VERSION ""

NS_ :

BS_:

BU_: WPC2 RLPSU DPSU APSU PSB SHVU_RR vHS_B2 FCS EMCU SLB ARS RCM CGW_CCU vDummy_HS_B ATS RLHV SGU PFSU ALBCU DSAU SWRC SHVU_FR RCS RRPSU BLTN_CAM SCM DLBCU OHCL RWPC RRHV WPC HOD ASAU

BO_ 607 ATS_04_200ms: 8 ATS
 SG_ ATS_RRStSldFwdBtn : 16|2@1+ (1,0) [0|0] ""  Vector__XXX
 SG_ ATS_RRStSldBwdBtn : 18|2@1+ (1,0) [0|0] ""  Vector__XXX
 SG_ ATS_RRStRclFwdBtn : 20|2@1+ (1,0) [0|0] ""  Vector__XXX
 SG_ ATS_RRStRclBwdBtn : 22|2@1+ (1,0) [0|0] ""  Vector__XXX
 SG_ ATS_RRStTltUpBtn : 24|2@1+ (1,0) [0|0] ""  Vector__XXX
 SG_ ATS_RRStTltDnBtn : 26|2@1+ (1,0) [0|0] ""  Vector__XXX
 SG_ ATS_RRStLegRestPopBtn : 32|2@1+ (1,0) [0|0] ""  Vector__XXX
 SG_ ATS_RRStFRestPopBtn : 34|2@1+ (1,0) [0|0] ""  Vector__XXX
 SG_ ATS_RRStAstPopBtn : 36|2@1+ (1,0) [0|0] ""  Vector__XXX
 SG_ ATS_RRFauCondiBtn : 38|2@1+ (1,0) [0|0] ""  Vector__XXX
 SG_ ATS_RRStHRestUpBtn : 40|2@1+ (1,0) [0|0] ""  Vector__XXX
 SG_ ATS_RRStHRestDnBtn : 42|2@1+ (1,0) [0|0] ""  Vector__XXX
 SG_ ATS_RRStHRestFwdBtn : 44|2@1+ (1,0) [0|0] ""  Vector__XXX
 SG_ ATS_RRStHRestBwdBtn : 46|2@1+ (1,0) [0|0] ""  Vector__XXX
 SG_ ATS_RRStShoulderADJFwdBtn : 48|2@1+ (1,0) [0|0] ""  Vector__XXX
 SG_ ATS_RRStShoulderADJBwdBtn : 50|2@1+ (1,0) [0|0] ""  Vector__XXX
 SG_ ATS_RRStLegRestUpBtn : 56|2@1+ (1,0) [0|0] ""  Vector__XXX
 SG_ ATS_RRStLegRestDnBtn : 58|2@1+ (1,0) [0|0] ""  Vector__XXX
 SG_ ATS_RRStLegRestExtUpBtn : 60|2@1+ (1,0) [0|0] ""  Vector__XXX
 SG_ ATS_RRStLegRestExtDnBtn : 62|2@1+ (1,0) [0|0] ""  Vector__XXX

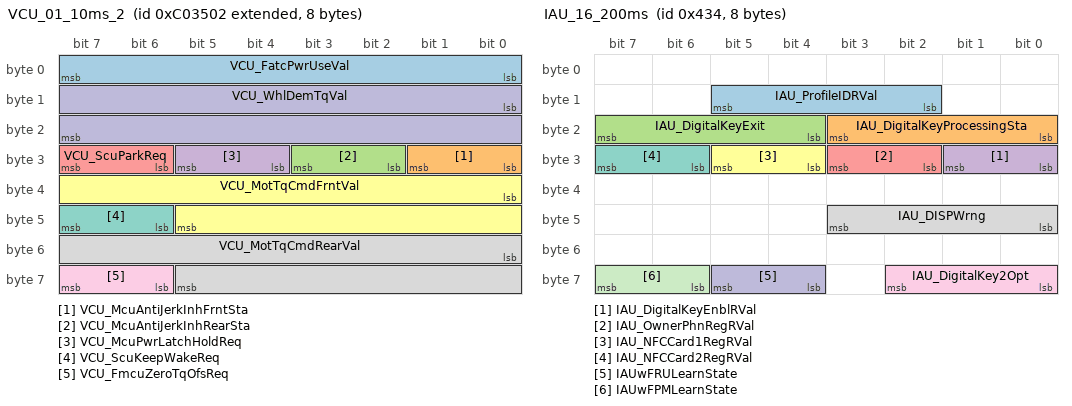
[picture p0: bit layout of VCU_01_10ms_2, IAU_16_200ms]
BO_ 2160080130 VCU_01_10ms_2: 8 CGW_CCU
 SG_ VCU_FatcPwrUseVal : 0|8@1+ (10,0) [0|2550] "W"  Vector__XXX
 SG_ VCU_McuAntiJerkInhFrntSta : 24|2@1+ (1,0) [0|3] ""  Vector__XXX
 SG_ VCU_McuAntiJerkInhRearSta : 26|2@1+ (1,0) [0|3] ""  Vector__XXX
 SG_ VCU_McuPwrLatchHoldReq : 28|2@1+ (1,0) [0|0] ""  Vector__XXX
 SG_ VCU_ScuParkReq : 30|2@1+ (1,0) [0|0] "flag"  Vector__XXX
 SG_ VCU_MotTqCmdFrntVal : 32|14@1- (0.125,0) [-1024|1023.875] "Nm"  Vector__XXX
 SG_ VCU_ScuKeepWakeReq : 46|2@1+ (1,0) [0|0] "flag"  Vector__XXX
 SG_ VCU_MotTqCmdRearVal : 48|14@1- (0.125,0) [-1024|1023.875] "Nm"  Vector__XXX
 SG_ VCU_FmcuZeroTqOfsReq : 62|2@1+ (1,0) [0|0] "flag"  Vector__XXX
 SG_ VCU_WhlDemTqVal : 8|16@1- (1,0) [-32768|32767] "Nm"  Vector__XXX

BO_ 1076 IAU_16_200ms: 8 CGW_CCU
 SG_ IAU_ProfileIDRVal : 10|4@1+ (1,0) [0|0] ""  WPC,RWPC,DPSU,DLBCU,RCM,BLTN_CAM,SGU,WPC2
 SG_ IAU_DigitalKeyProcessingSta : 16|4@1+ (1,0) [0|0] ""  Vector__XXX
 SG_ IAU_DigitalKeyExit : 20|4@1+ (1,0) [0|0] ""  Vector__XXX
 SG_ IAU_DigitalKeyEnblRVal : 24|2@1+ (1,0) [0|0] ""  Vector__XXX
 SG_ IAU_OwnerPhnRegRVal : 26|2@1+ (1,0) [0|0] ""  Vector__XXX
 SG_ IAU_NFCCard1RegRVal : 28|2@1+ (1,0) [0|0] ""  Vector__XXX
 SG_ IAU_NFCCard2RegRVal : 30|2@1+ (1,0) [0|0] ""  Vector__XXX
 SG_ IAU_DISPWrng : 40|4@1+ (1,0) [0|0] ""  Vector__XXX
 SG_ IAU_DigitalKey2Opt : 56|3@1+ (1,0) [0|0] ""  WPC,WPC2
 SG_ IAUwFRULearnState : 60|2@1+ (1,0) [0|0] ""  Vector__XXX
 SG_ IAUwFPMLearnState : 62|2@1+ (1,0) [0|0] ""  Vector__XXX

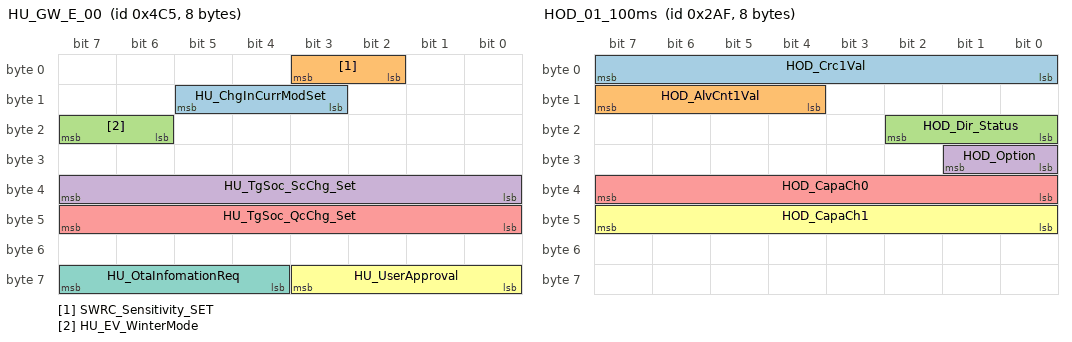
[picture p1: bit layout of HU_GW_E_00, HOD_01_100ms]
BO_ 1221 HU_GW_E_00: 8 CGW_CCU
 SG_ HU_ChgInCurrModSet : 11|3@1+ (1,0) [0|0] ""  Vector__XXX
 SG_ SWRC_Sensitivity_SET : 2|2@1+ (1,0) [0|0] ""  SWRC
 SG_ HU_EV_WinterMode : 22|2@1+ (1,0) [0|0] ""  Vector__XXX
 SG_ HU_TgSoc_ScChg_Set : 32|8@1+ (0.5,0) [0|100] "%"  Vector__XXX
 SG_ HU_TgSoc_QcChg_Set : 40|8@1+ (0.5,0) [0|100] "%"  Vector__XXX
 SG_ HU_UserApproval : 56|4@1+ (1,0) [0|0] ""  Vector__XXX
 SG_ HU_OtaInfomationReq : 60|4@1+ (1,0) [0|0] ""  Vector__XXX

BO_ 687 HOD_01_100ms: 8 HOD
 SG_ HOD_Crc1Val : 0|8@1+ (1,0) [0|0] ""  CGW_CCU
 SG_ HOD_AlvCnt1Val : 12|4@1+ (1,0) [0|0] ""  CGW_CCU
 SG_ HOD_Dir_Status : 16|3@1+ (1,0) [0|0] ""  CGW_CCU
 SG_ HOD_Option : 24|2@1+ (1,0) [0|0] ""  CGW_CCU
 SG_ HOD_CapaCh0 : 32|8@1+ (1,0) [0|0] ""  CGW_CCU
 SG_ HOD_CapaCh1 : 40|8@1+ (1,0) [0|0] ""  CGW_CCU

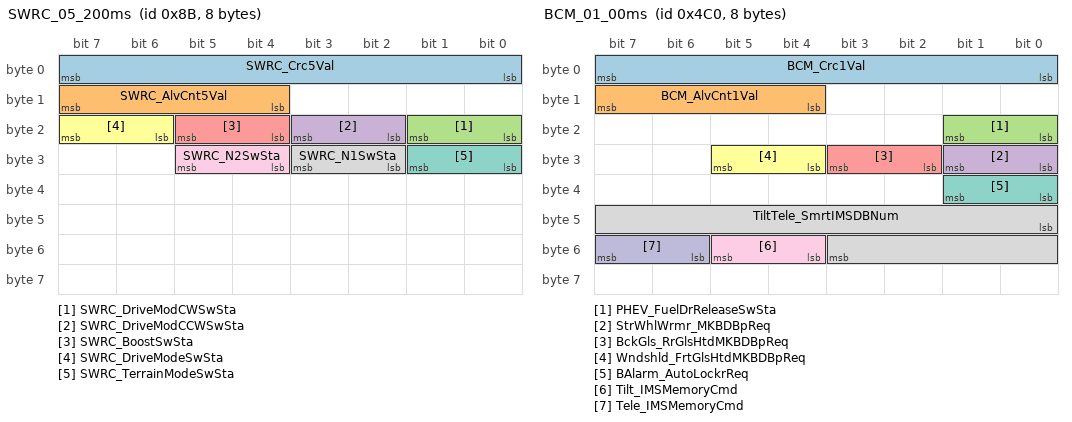
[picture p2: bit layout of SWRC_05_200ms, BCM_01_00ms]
BO_ 139 SWRC_05_200ms: 8 SWRC
 SG_ SWRC_Crc5Val : 0|8@1+ (1,0) [0|0] ""  CGW_CCU
 SG_ SWRC_AlvCnt5Val : 12|4@1+ (1,0) [0|0] ""  CGW_CCU
 SG_ SWRC_DriveModCWSwSta : 16|2@1+ (1,0) [0|0] ""  CGW_CCU
 SG_ SWRC_DriveModCCWSwSta : 18|2@1+ (1,0) [0|0] ""  CGW_CCU
 SG_ SWRC_BoostSwSta : 20|2@1+ (1,0) [0|0] ""  CGW_CCU
 SG_ SWRC_DriveModeSwSta : 22|2@1+ (1,0) [0|0] ""  CGW_CCU
 SG_ SWRC_TerrainModeSwSta : 24|2@1+ (1,0) [0|0] ""  CGW_CCU
 SG_ SWRC_N1SwSta : 26|2@1+ (1,0) [0|0] ""  CGW_CCU
 SG_ SWRC_N2SwSta : 28|2@1+ (1,0) [0|0] ""  CGW_CCU

BO_ 1216 BCM_01_00ms: 8 CGW_CCU
 SG_ BCM_Crc1Val : 0|8@1+ (1,0) [0|0] ""  Vector__XXX
 SG_ BCM_AlvCnt1Val : 12|4@1+ (1,0) [0|0] ""  Vector__XXX
 SG_ PHEV_FuelDrReleaseSwSta : 16|2@1+ (1,0) [0|0] ""  Vector__XXX
 SG_ StrWhlWrmr_MKBDBpReq : 24|2@1+ (1,0) [0|0] ""  Vector__XXX
 SG_ BckGls_RrGlsHtdMKBDBpReq : 26|2@1+ (1,0) [0|0] ""  Vector__XXX
 SG_ Wndshld_FrtGlsHtdMKBDBpReq : 28|2@1+ (1,0) [0|0] ""  Vector__XXX
 SG_ BAlarm_AutoLockrReq : 32|2@1+ (1,0) [0|0] ""  Vector__XXX
 SG_ TiltTele_SmrtIMSDBNum : 40|12@1+ (1,0) [0|0] ""  SCM
 SG_ Tilt_IMSMemoryCmd : 52|2@1+ (1,0) [0|0] ""  SCM
 SG_ Tele_IMSMemoryCmd : 54|2@1+ (1,0) [0|0] ""  SCM

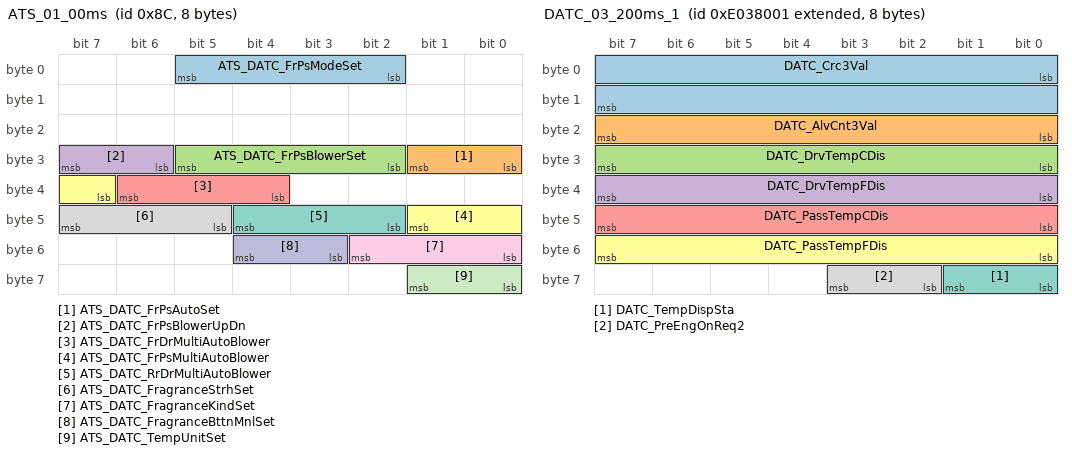
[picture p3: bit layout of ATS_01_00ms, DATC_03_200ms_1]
BO_ 140 ATS_01_00ms: 8 ATS
 SG_ ATS_DATC_FrPsModeSet : 2|4@1+ (1,0) [0|0] ""  CGW_CCU
 SG_ ATS_DATC_FrPsAutoSet : 24|2@1+ (1,0) [0|0] ""  CGW_CCU
 SG_ ATS_DATC_FrPsBlowerSet : 26|4@1+ (1,0) [0|0] ""  CGW_CCU
 SG_ ATS_DATC_FrPsBlowerUpDn : 30|2@1+ (1,0) [0|0] ""  CGW_CCU
 SG_ ATS_DATC_FrDrMultiAutoBlower : 36|3@1+ (1,0) [0|0] ""  CGW_CCU
 SG_ ATS_DATC_FrPsMultiAutoBlower : 39|3@1+ (1,0) [0|0] ""  CGW_CCU
 SG_ ATS_DATC_RrDrMultiAutoBlower : 42|3@1+ (1,0) [0|0] ""  CGW_CCU
 SG_ ATS_DATC_FragranceStrhSet : 45|3@1+ (1,0) [0|0] ""  CGW_CCU
 SG_ ATS_DATC_FragranceKindSet : 48|3@1+ (1,0) [0|0] ""  CGW_CCU
 SG_ ATS_DATC_FragranceBttnMnlSet : 51|2@1+ (1,0) [0|0] ""  CGW_CCU
 SG_ ATS_DATC_TempUnitSet : 56|2@1+ (1,0) [0|0] ""  CGW_CCU

BO_ 2382594049 DATC_03_200ms_1: 8 CGW_CCU
 SG_ DATC_Crc3Val : 0|16@1+ (1,0) [0|0] ""  Vector__XXX
 SG_ DATC_AlvCnt3Val : 16|8@1+ (1,0) [0|0] ""  Vector__XXX
 SG_ DATC_DrvTempCDis : 24|8@1+ (0.5,14) [0|0] "¡É"  ATS
 SG_ DATC_DrvTempFDis : 32|8@1+ (1,56) [0|0] "¢µ"  ATS
 SG_ DATC_PassTempCDis : 40|8@1+ (0.5,14) [0|0] "¡É"  ATS
 SG_ DATC_PassTempFDis : 48|8@1+ (1,56) [0|0] "¢µ"  ATS
 SG_ DATC_TempDispSta : 56|2@1+ (1,0) [0|0] ""  Vector__XXX
 SG_ DATC_PreEngOnReq2 : 58|2@1+ (1,0) [0|0] ""  Vector__XXX

BO_ 1219 HU_BLTN_CAM_E_00: 8 CGW_CCU
 SG_ BLTN_CAM_Rec_OWD_NvalueSet : 0|2@1+ (1,0) [0|0] ""  BLTN_CAM
 SG_ BLTN_CAM_Time_Stm_NvalueSet : 10|2@1+ (1,0) [0|0] ""  BLTN_CAM
 SG_ BLTN_CAM_Spd_Stm_NvalueSet : 12|2@1+ (1,0) [0|0] ""  BLTN_CAM
 SG_ BLTN_CAM_Locatn_Stm_NvalueSet : 14|2@1+ (1,0) [0|0] ""  BLTN_CAM
 SG_ BLTN_CAM_TrnSig_Stm_NvalueSet : 16|2@1+ (1,0) [0|0] ""  BLTN_CAM
 SG_ BLTN_CAM_AclBrk_Stm_NvalueSet : 18|2@1+ (1,0) [0|0] ""  BLTN_CAM
 SG_ BLTN_CAM_Rec_DEV_NvalueSet : 2|2@1+ (1,0) [0|0] ""  BLTN_CAM
 SG_ BLTN_CAM_GearPos_Stm_NvalueSet : 20|2@1+ (1,0) [0|0] ""  BLTN_CAM
 SG_ BLTN_CAM_EVSen_Stm_NvalueSet : 22|2@1+ (1,0) [0|0] ""  BLTN_CAM
 SG_ BLTN_CAM_Strangl_Stm_NvalueSet : 24|2@1+ (1,0) [0|0] ""  BLTN_CAM
 SG_ BLTN_CAM_PrkTime_NvalueSet : 30|8@1+ (1,0) [0|0] "Hour"  BLTN_CAM
 SG_ BLTN_CAM_EV_BfrTime_NvalueSet : 38|5@1+ (1,0) [0|0] ""  BLTN_CAM
 SG_ BLTN_CAM_Rec_OWP_NvalueSet : 4|2@1+ (1,0) [0|0] ""  BLTN_CAM
 SG_ BLTN_CAM_EV_AftTime_NvalueSet : 43|5@1+ (1,0) [0|0] ""  BLTN_CAM
 SG_ BLTN_CAM_TML_Int_NvalueSet : 48|4@1+ (1,0) [0|0] ""  BLTN_CAM
 SG_ BLTN_CAM_Sen_DEV_NvalueSet : 52|4@1+ (1,0) [0|0] ""  BLTN_CAM
 SG_ BLTN_CAM_Sen_PEV_NvalueSet : 56|4@1+ (1,0) [0|0] ""  BLTN_CAM
 SG_ BLTN_CAM_Rec_PEV_NvalueSet : 6|2@1+ (1,0) [0|0] ""  BLTN_CAM
 SG_ BLTN_CAM_AudRec_NvalueSet : 8|2@1+ (1,0) [0|0] ""  BLTN_CAM

BO_ 1218 HU_USM_E_08: 8 CGW_CCU
 SG_ C_AVN_PTGHeightNValueSet : 13|3@1+ (1,0) [0|0] ""  Vector__XXX
 SG_ CF_AVN_SCCMLReset : 16|2@1+ (1,0) [0|0] ""  Vector__XXX
 SG_ C_TgltAwayCloseNValue : 18|2@1+ (1,0) [0|0] ""  Vector__XXX
 SG_ C_HAnBNValueSet : 20|2@1+ (1,0) [0|0] ""  Vector__XXX
 SG_ CF_AVN_RrSeatRemindNValueSet : 22|2@1+ (1,0) [0|0] ""  Vector__XXX
 SG_ CF_AVN_DSWNValueSet : 24|2@1+ (1,0) [0|0] ""  Vector__XXX
 SG_ CF_AVN_RRPSU_RLNValueSet : 26|3@1+ (1,0) [0|0] ""  APSU,RRPSU,RLPSU
 SG_ CF_AVN_APSUNValueSet : 29|3@1+ (1,0) [0|0] ""  APSU,ASAU
 SG_ CF_AVN_NCC_CameraNValueSet : 32|3@1+ (1,0) [0|0] ""  Vector__XXX
 SG_ CF_AVN_RRPSU_RRNValueSet : 37|3@1+ (1,0) [0|0] ""  APSU,RRPSU,RLPSU
 SG_ CF_AVN_HtBlcAstNValueSet : 40|4@1+ (1,0) [0|0] ""  APSU,SHVU_FR
 SG_ CF_AVN_HtBlcDrvNValueSet : 44|4@1+ (1,0) [0|0] ""  APSU,SHVU_FR
 SG_ CF_AVN_SCCModeNValueSet : 48|2@1+ (1,0) [0|0] ""  Vector__XXX
 SG_ CF_AVN_SCCMLChar1Set : 50|3@1+ (1,0) [0|0] ""  Vector__XXX
 SG_ CF_AVN_UIPNValueSet : 54|2@1+ (1,0) [0|0] ""  Vector__XXX
 SG_ CF_AVN_SCCMLChar2Set : 56|3@1+ (1,0) [0|0] ""  Vector__XXX
 SG_ CF_AVN_SCCMLChar3Set : 59|3@1+ (1,0) [0|0] ""  Vector__XXX
 SG_ CF_AVN_HDALCFuncNValueSet : 8|2@1+ (1,0) [0|0] ""  Vector__XXX

BO_ 2323816451 CCU_CCS_01_00ms_3: 8 CGW_CCU

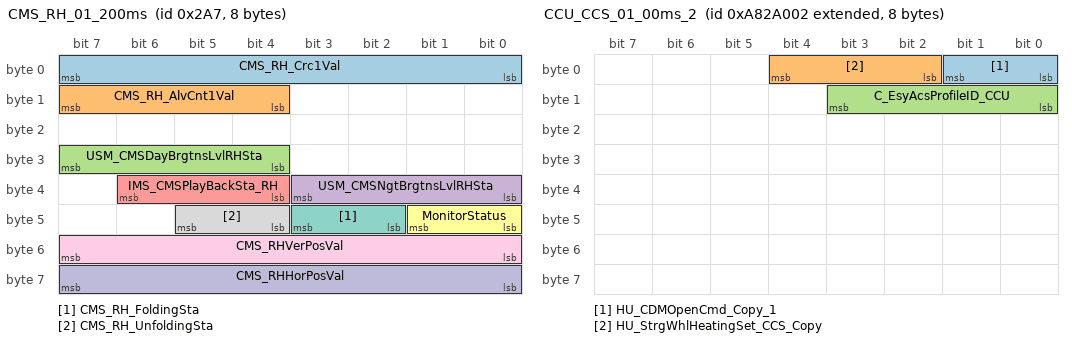
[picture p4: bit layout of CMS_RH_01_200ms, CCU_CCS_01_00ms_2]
BO_ 679 CMS_RH_01_200ms: 8 CGW_CCU
 SG_ CMS_RH_Crc1Val : 0|8@1+ (1,0) [0|0] ""  Vector__XXX
 SG_ CMS_RH_AlvCnt1Val : 12|4@1+ (1,0) [0|0] ""  Vector__XXX
 SG_ USM_CMSDayBrgtnsLvlRHSta : 28|4@1+ (1,0) [0|0] ""  Vector__XXX
 SG_ USM_CMSNgtBrgtnsLvlRHSta : 32|4@1+ (1,0) [0|0] ""  Vector__XXX
 SG_ IMS_CMSPlayBackSta_RH : 36|3@1+ (1,0) [0|0] ""  DPSU
 SG_ MonitorStatus : 40|2@1+ (1,0) [0|0] ""  Vector__XXX
 SG_ CMS_RH_FoldingSta : 42|2@1+ (1,0) [0|0] ""  Vector__XXX
 SG_ CMS_RH_UnfoldingSta : 44|2@1+ (1,0) [0|0] ""  Vector__XXX
 SG_ CMS_RHVerPosVal : 48|8@1+ (0.02,0) [0|0] "V"  Vector__XXX
 SG_ CMS_RHHorPosVal : 56|8@1+ (0.02,0) [0|0] "V"  Vector__XXX

BO_ 2323816450 CCU_CCS_01_00ms_2: 8 CGW_CCU
 SG_ HU_CDMOpenCmd_Copy_1 : 0|2@1+ (1,0) [0|0] ""  Vector__XXX
 SG_ HU_StrgWhlHeatingSet_CCS_Copy : 2|3@1+ (1,0) [0|0] ""  Vector__XXX
 SG_ C_EsyAcsProfileID_CCU : 8|4@1+ (1,0) [0|0] ""  DPSU

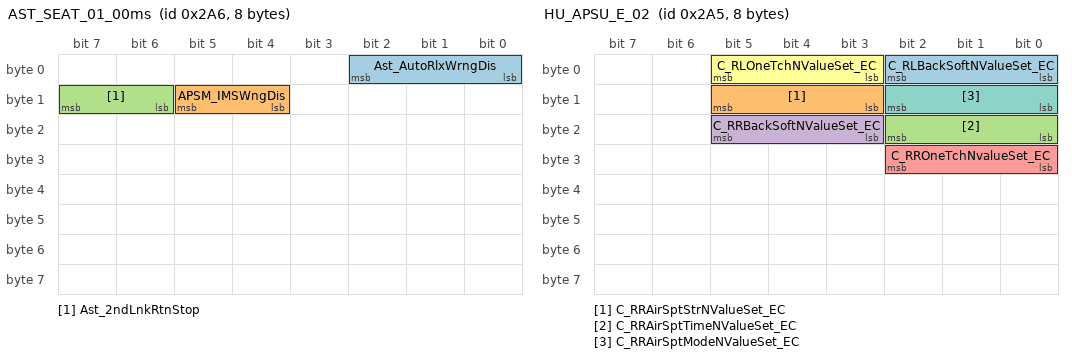
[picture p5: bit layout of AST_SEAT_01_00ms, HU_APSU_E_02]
BO_ 678 AST_SEAT_01_00ms: 8 APSU
 SG_ Ast_AutoRlxWrngDis : 0|3@1+ (1,0) [0|0] ""  CGW_CCU
 SG_ APSM_IMSWngDis : 12|2@1+ (1,0) [0|0] ""  Vector__XXX
 SG_ Ast_2ndLnkRtnStop : 14|2@1+ (1,0) [0|0] ""  RLPSU,RRPSU

BO_ 677 HU_APSU_E_02: 8 CGW_CCU
 SG_ C_RLBackSoftNValueSet_EC : 0|3@1+ (1,0) [0|0] ""  RLPSU,ATS
 SG_ C_RRAirSptStrNValueSet_EC : 11|3@1+ (1,0) [0|0] ""  RRPSU,ATS
 SG_ C_RRAirSptTimeNValueSet_EC : 16|3@1+ (1,0) [0|0] ""  RRPSU,ATS
 SG_ C_RRBackSoftNValueSet_EC : 19|3@1+ (1,0) [0|0] ""  RRPSU,ATS
 SG_ C_RROneTchNvalueSet_EC : 24|3@1+ (1,0) [0|0] ""  RRPSU,ATS
 SG_ C_RLOneTchNValueSet_EC : 3|3@1+ (1,0) [0|0] ""  RRPSU,RLPSU,ATS
 SG_ C_RRAirSptModeNValueSet_EC : 8|3@1+ (1,0) [0|0] ""  RRPSU,ATS

BO_ 2323816449 CCU_CCS_01_00ms_1: 8 CGW_CCU
 SG_ C_CtrlDrLockRlyCCS_Copy_2 : 0|2@1+ (1,0) [0|0] ""  Vector__XXX
 SG_ C_TeleHeatingCmdIBOX_Copy_2 : 10|2@1+ (1,0) [0|0] ""  Vector__XXX
 SG_ C_TeleStrgWhlHeatingCmdIBOX_Copy_2 : 12|2@1+ (1,0) [0|0] ""  Vector__XXX
 SG_ C_TeleDefoggerHeatingCmdIBOX_Copy_2 : 14|2@1+ (1,0) [0|0] ""  Vector__XXX
 SG_ C_TeleDrvSeatOpCmdIBOX_Copy_2 : 16|4@1+ (1,0) [0|0] ""  SHVU_FR,DPSU
 SG_ C_CtrlDrUnlockRlyCCS_Copy_2 : 2|2@1+ (1,0) [0|0] ""  Vector__XXX
 SG_ C_TeleAstSeatOpCmdIBOX_Copy_2 : 20|4@1+ (1,0) [0|0] ""  APSU,SHVU_FR
 SG_ C_TeleRRSeatOpCmdIBOX_Copy_2 : 24|4@1+ (1,0) [0|0] ""  RRHV,SHVU_FR,SHVU_RR,RRPSU,RLPSU,ATS
 SG_ C_TeleRLSeatOpCmdIBOX_Copy_1 : 28|4@1+ (1,0) [0|0] ""  RLHV,SHVU_FR,SHVU_RR,RRPSU,RLPSU,ATS
 SG_ C_BlindCmdAVN_Copy_2 : 32|3@1+ (1,0) [0|0] ""  Vector__XXX
 SG_ C_GlassCmdAVN_Copy_2 : 35|3@1+ (1,0) [0|0] ""  Vector__XXX
 SG_ C_DrvWindowCmdAVN_Copy_2 : 38|4@1+ (1,0) [0|0] ""  Vector__XXX
 SG_ C_HazardFromCCS_Copy_2 : 4|2@1+ (1,0) [0|0] ""  Vector__XXX
 SG_ C_AstWindowCmdAVN_Copy_2 : 42|4@1+ (1,0) [0|0] ""  Vector__XXX
 SG_ C_RRWindowCmdAVN_Copy_2 : 46|4@1+ (1,0) [0|0] ""  Vector__XXX
 SG_ C_RLWindowCmdAVN_Copy_2 : 50|4@1+ (1,0) [0|0] ""  Vector__XXX
 SG_ TailCtrlReq_Copy : 54|2@1+ (1,0) [0|0] ""  Vector__XXX
 SG_ HazardCtrlReq_Copy : 56|2@1+ (1,0) [0|0] ""  Vector__XXX
 SG_ HU_DATC_AirCleaningSet_Copy_1 : 58|2@1+ (1,0) [0|0] ""  Vector__XXX
 SG_ C_PanicFromCCS_Copy_2 : 6|2@1+ (1,0) [0|0] ""  Vector__XXX
 SG_ C_TeleFrontHeatingCmdIBOX_Copy_1 : 60|2@1+ (1,0) [0|0] ""  Vector__XXX
 SG_ RAC_AirCleaningCtrlReq_Copy_1 : 62|2@1+ (1,0) [0|0] ""  Vector__XXX
 SG_ C_PreCrankReq_Copy : 8|2@1+ (1,0) [0|0] ""  Vector__XXX

BO_ 676 HU_APSU_E_01: 8 CGW_CCU
 SG_ C_DrAirSptNValueSet_EC : 0|2@1+ (1,0) [0|0] ""  DLBCU,DSAU
 SG_ C_DrCushSoftNValueSet_EC : 11|3@1+ (1,0) [0|0] ""  DLBCU,DSAU
 SG_ C_AstAirSptNValueSet_EC : 14|2@1+ (1,0) [0|0] ""  ASAU,ALBCU
 SG_ C_DrBackSoftNValueSet_EC : 16|3@1+ (1,0) [0|0] ""  DLBCU,DSAU
 SG_ C_AstAirSptModeNValueSet_EC : 19|3@1+ (1,0) [0|0] ""  ASAU,ALBCU
 SG_ C_DrAirSptModeNValueSet_EC : 2|3@1+ (1,0) [0|0] ""  DLBCU,DSAU
 SG_ C_RLAirSptNValueSet_EC : 22|2@1+ (1,0) [0|0] ""  RLPSU,ATS
 SG_ C_AstAirSptStrNValueSet_EC : 24|3@1+ (1,0) [0|0] ""  ASAU,ALBCU
 SG_ C_AstAirSptTimeNValueSet_EC : 27|3@1+ (1,0) [0|0] ""  ASAU,ALBCU
 SG_ C_RRAirSptNValueSet_EC : 30|2@1+ (1,0) [0|0] ""  RRPSU,ATS
 SG_ C_AstCushSoftNValueSet_EC : 32|3@1+ (1,0) [0|0] ""  ASAU
 SG_ C_AstBackSoftNValueSet_EC : 35|3@1+ (1,0) [0|0] ""  ASAU
 SG_ C_AstRlxNValueSet_EC : 40|3@1+ (1,0) [0|0] ""  APSU
 SG_ C_RLAirSptModeNValueSet_EC : 43|3@1+ (1,0) [0|0] ""  RLPSU,ATS
 SG_ C_DrAirSptStrNValueSet_EC : 5|3@1+ (1,0) [0|0] ""  DLBCU,DSAU
 SG_ C_RLAirSptStrNValueSet_EC : 56|3@1+ (1,0) [0|0] ""  RLPSU,ATS
 SG_ C_RLAirSptTimeNValueSet_EC : 59|3@1+ (1,0) [0|0] ""  RLPSU,ATS
 SG_ C_DrAirSptTimeNValueSet_EC : 8|3@1+ (1,0) [0|0] ""  DLBCU,DSAU

BO_ 675 HU_USM_E_11: 8 CGW_CCU
 SG_ Usm_RpmMUDSet : 1|2@1+ (1,0) [0|0] ""  Vector__XXX
 SG_ CF_AVN_HtBlcRLNValueSet : 11|4@1+ (1,0) [0|0] ""  SHVU_FR,SHVU_RR,RRPSU,RLPSU
 SG_ CF_AVN_BRAKE_PedalfeelNValueSet2 : 15|3@1+ (1,0) [0|0] ""  Vector__XXX
 SG_ CF_AVN_ISLA_AutoNModSet : 18|2@1+ (1,0) [0|0] ""  Vector__XXX
 SG_ CF_AVN_HtBlcRRNValueSet : 20|4@1+ (1,0) [0|0] ""  SHVU_FR,SHVU_RR,RRPSU,RLPSU
 SG_ LapTimer_AutoMeasure_Setting : 24|2@1+ (1,0) [0|0] ""  Vector__XXX
 SG_ LapTimer_TimeGap_Setting : 26|2@1+ (1,0) [0|0] ""  Vector__XXX
 SG_ Usm_RpmSANDSet : 3|2@1+ (1,0) [0|0] ""  Vector__XXX
 SG_ CF_AVN_RemoteWDWNValueSet : 30|2@1+ (1,0) [0|0] ""  Vector__XXX
 SG_ USM_TowWeight_Set : 32|4@1+ (1,0) [0|0] ""  Vector__XXX
 SG_ CF_AVN_PABArbgNValueSet : 36|2@1+ (1,0) [0|0] ""  Vector__XXX
 SG_ CF_AVN_SportHUD2 : 38|2@1+ (1,0) [0|0] ""  Vector__XXX
 SG_ C_SLB_SmartCtrl_Set_Nvalue : 44|4@1+ (1,0) [0|0] ""  SLB,DLBCU
 SG_ HU_CustomNewMenuSet : 5|4@1+ (1,0) [0|0] ""  Vector__XXX
 SG_ USM_RpmComfortRearSet : 57|2@1+ (1,0) [0|0] ""  Vector__XXX
 SG_ Usm_RpmMyDriveModeSet : 59|2@1+ (1,0) [0|0] ""  Vector__XXX
 SG_ CF_AVN_PDWLmtNvalueSet : 61|2@1+ (1,0) [0|0] ""  Vector__XXX
 SG_ CF_AVN_PCA_RrEquipNvalueSet : 9|2@1+ (1,0) [0|0] ""  Vector__XXX

BO_ 1227 PSM_01_00ms: 8 DPSU
 SG_ DrvIMS_MemoryP1Req : 0|2@1+ (1,0) [0|0] ""  CGW_CCU
 SG_ DrvIMS_PlyBckP2Req : 10|2@1+ (1,0) [0|0] ""  CGW_CCU
 SG_ DrvIMS_PlyBckP3Req : 12|2@1+ (1,0) [0|0] ""  CGW_CCU
 SG_ DrvIMS_PlyBckStpReq : 14|2@1+ (1,0) [0|0] ""  CGW_CCU
 SG_ SmrtIMS_PlyBckReq : 16|12@1+ (1,0) [0|0] ""  CGW_CCU
 SG_ DrvIMS_MemoryP2Req : 2|2@1+ (1,0) [0|0] ""  CGW_CCU
 SG_ PSM_IMSReq : 28|3@1+ (1,0) [0|0] ""  CGW_CCU
 SG_ SmrtIMS_ImgDBVal : 32|5@1+ (1,0) [0|0] ""  CGW_CCU
 SG_ SmrtIMS_PlyBckStpReq : 37|2@1+ (1,0) [0|0] ""  CGW_CCU
 SG_ DrvIMS_MemoryP3Req : 4|2@1+ (1,0) [0|0] ""  CGW_CCU
 SG_ SmrtIMS_EnterSwSta : 40|2@1+ (1,0) [0|0] ""  CGW_CCU
 SG_ DrvIMS_BzrReq : 42|2@1+ (1,0) [0|0] ""  CGW_CCU
 SG_ DrvIMS_ErrConWmgDis : 46|2@1+ (1,0) [0|0] ""  CGW_CCU
 SG_ PSM_DrvRlxReturn_Req : 48|3@1+ (1,0) [0|0] ""  CGW_CCU
 SG_ Drv_AutoRlxWrngDis : 51|3@1+ (1,0) [0|0] ""  CGW_CCU
 SG_ DrvIMS_MemorySetEnaSta : 6|2@1+ (1,0) [0|0] ""  CGW_CCU
 SG_ DrvIMS_PlyBckP1Req : 8|2@1+ (1,0) [0|0] ""  CGW_CCU

BO_ 2323816452 CCU_CCS_01_00ms_4: 8 CGW_CCU

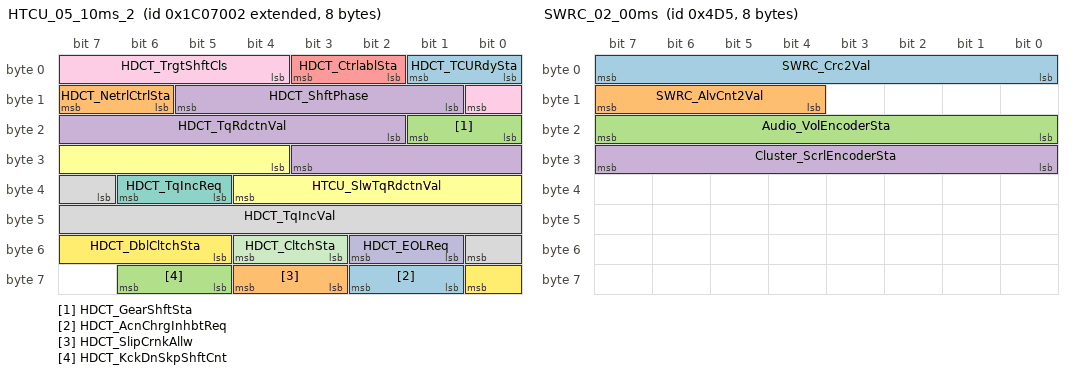
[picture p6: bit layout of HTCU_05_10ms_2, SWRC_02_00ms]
BO_ 2176872450 HTCU_05_10ms_2: 8 CGW_CCU
 SG_ HDCT_TCURdySta : 0|2@1+ (1,0) [0|0] ""  Vector__XXX
 SG_ HDCT_NetrlCtrlSta : 14|2@1+ (1,0) [0|0] ""  Vector__XXX
 SG_ HDCT_GearShftSta : 16|2@1+ (1,0) [0|0] ""  Vector__XXX
 SG_ HDCT_TqRdctnVal : 18|10@1+ (0.390625,-200) [0|0] "%"  Vector__XXX
 SG_ HDCT_CtrlablSta : 2|2@1+ (1,0) [0|0] ""  Vector__XXX
 SG_ HTCU_SlwTqRdctnVal : 28|9@1+ (0.390625,0) [0|0] "%"  Vector__XXX
 SG_ HDCT_TqIncReq : 37|2@1+ (1,0) [0|0] ""  Vector__XXX
 SG_ HDCT_TqIncVal : 39|10@1+ (0.390625,-200) [0|0] "%"  Vector__XXX
 SG_ HDCT_TrgtShftCls : 4|5@1+ (1,0) [0|0] "flag"  Vector__XXX
 SG_ HDCT_EOLReq : 49|2@1+ (1,0) [0|0] ""  Vector__XXX
 SG_ HDCT_CltchSta : 51|2@1+ (1,0) [0|0] ""  Vector__XXX
 SG_ HDCT_DblCltchSta : 53|4@1+ (1,0) [0|0] ""  Vector__XXX
 SG_ HDCT_AcnChrgInhbtReq : 57|2@1+ (1,0) [0|0] ""  Vector__XXX
 SG_ HDCT_SlipCrnkAllw : 59|2@1+ (1,0) [0|0] ""  Vector__XXX
 SG_ HDCT_KckDnSkpShftCnt : 61|2@1+ (1,0) [0|0] ""  Vector__XXX
 SG_ HDCT_ShftPhase : 9|5@1+ (1,0) [0|0] ""  Vector__XXX

BO_ 1237 SWRC_02_00ms: 8 SWRC
 SG_ SWRC_Crc2Val : 0|8@1+ (1,0) [0|0] ""  Vector__XXX
 SG_ SWRC_AlvCnt2Val : 12|4@1+ (1,0) [0|0] ""  Vector__XXX
 SG_ Audio_VolEncoderSta : 16|8@1+ (1,0) [0|0] ""  CGW_CCU
 SG_ Cluster_ScrlEncoderSta : 24|8@1+ (1,0) [0|0] ""  CGW_CCU

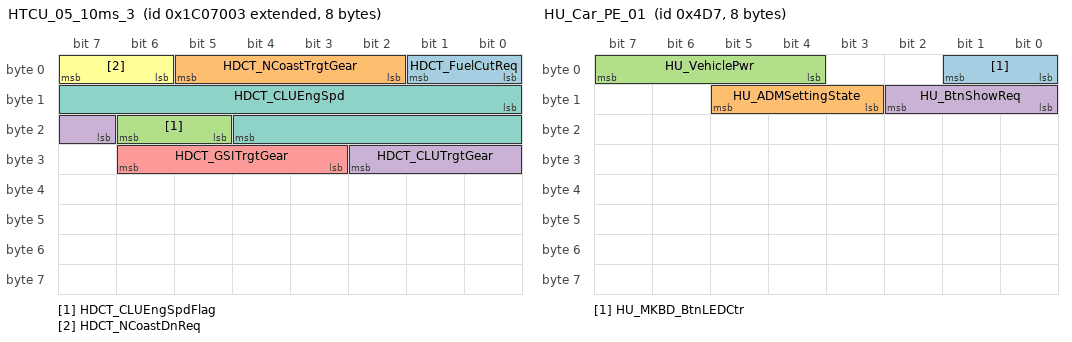
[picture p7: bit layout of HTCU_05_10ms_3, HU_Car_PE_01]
BO_ 2176872451 HTCU_05_10ms_3: 8 CGW_CCU
 SG_ HDCT_FuelCutReq : 0|2@1+ (1,0) [0|0] ""  Vector__XXX
 SG_ HDCT_NCoastTrgtGear : 2|4@1+ (1,0) [0|0] ""  Vector__XXX
 SG_ HDCT_CLUEngSpdFlag : 21|2@1+ (1,0) [0|0] ""  Vector__XXX
 SG_ HDCT_CLUTrgtGear : 23|4@1+ (1,0) [0|0] ""  Vector__XXX
 SG_ HDCT_GSITrgtGear : 27|4@1+ (1,0) [0|0] ""  Vector__XXX
 SG_ HDCT_NCoastDnReq : 6|2@1+ (1,0) [0|0] ""  Vector__XXX
 SG_ HDCT_CLUEngSpd : 8|13@1+ (0.9766,0) [0|0] ""  Vector__XXX

BO_ 1239 HU_Car_PE_01: 8 CGW_CCU
 SG_ HU_MKBD_BtnLEDCtr : 0|2@1+ (1,0) [0|0] ""  Vector__XXX
 SG_ HU_ADMSettingState : 11|3@1+ (1,0) [0|0] ""  Vector__XXX
 SG_ HU_VehiclePwr : 4|4@1+ (1,0) [0|0] ""  SGU
 SG_ HU_BtnShowReq : 8|3@1+ (1,0) [0|0] ""  SWRC

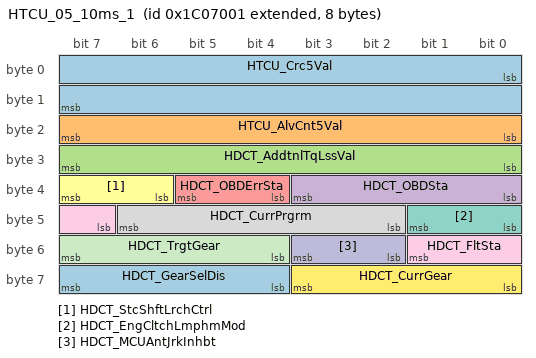
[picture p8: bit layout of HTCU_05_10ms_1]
BO_ 2176872449 HTCU_05_10ms_1: 8 CGW_CCU
 SG_ HTCU_Crc5Val : 0|16@1+ (1,0) [0|0] ""  Vector__XXX
 SG_ HTCU_AlvCnt5Val : 16|8@1+ (1,0) [0|0] ""  Vector__XXX
 SG_ HDCT_AddtnlTqLssVal : 24|8@1+ (0.390625,0) [0|0] "%"  Vector__XXX
 SG_ HDCT_OBDSta : 32|4@1+ (1,0) [0|0] ""  Vector__XXX
 SG_ HDCT_OBDErrSta : 36|2@1+ (1,0) [0|0] ""  Vector__XXX
 SG_ HDCT_StcShftLrchCtrl : 38|2@1+ (1,0) [0|0] ""  Vector__XXX
 SG_ HDCT_EngCltchLmphmMod : 40|2@1+ (1,0) [0|0] ""  Vector__XXX
 SG_ HDCT_CurrPrgrm : 42|5@1+ (1,0) [0|0] ""  Vector__XXX
 SG_ HDCT_FltSta : 47|3@1+ (1,0) [0|0] ""  Vector__XXX
 SG_ HDCT_MCUAntJrkInhbt : 50|2@1+ (1,0) [0|0] ""  Vector__XXX
 SG_ HDCT_TrgtGear : 52|4@1+ (1,0) [0|0] ""  Vector__XXX
 SG_ HDCT_CurrGear : 56|4@1+ (1,0) [0|0] ""  Vector__XXX
 SG_ HDCT_GearSelDis : 60|4@1+ (1,0) [0|0] ""  SWRC,BLTN_CAM

CM_ BO_ 678 "[EC] On Event and On Change";
CM_ SG_ 678 Ast_AutoRlxWrngDis "Assist seat auto relax warning information for AVN Display";
CM_ SG_ 678 APSM_IMSWngDis "Ast IMS information";
CM_ BO_ 140 "[EC] On Event and On Change";
CM_ SG_ 140 ATS_DATC_FrPsModeSet "Front Passenger side Mode Set";
CM_ SG_ 140 ATS_DATC_FrPsAutoSet "Front Passenger side Auto Set";
CM_ SG_ 140 ATS_DATC_FrPsBlowerSet "Front Passenger side Blower Set";
CM_ SG_ 140 ATS_DATC_FrPsBlowerUpDn "Front Passenger side Blower Up Down";
CM_ SG_ 140 ATS_DATC_FrDrMultiAutoBlower "Front Driver side Multi-Auto Blower set";
CM_ SG_ 140 ATS_DATC_FrPsMultiAutoBlower "Front Passenger side Multi-Auto Blower set";
CM_ SG_ 140 ATS_DATC_RrDrMultiAutoBlower "Rear Driver side Multi-Auto Blower set";
CM_ SG_ 140 ATS_DATC_FragranceStrhSet "Fragrance Strength Set (¹ßÇâ ±â´É Çâ ¼¼±â ¼³Á¤)";
CM_ SG_ 140 ATS_DATC_FragranceKindSet "Fragrance Kind Set (¹ßÇâ ±â´É Çâ Á¾·ù ¼³Á¤)";
CM_ SG_ 140 ATS_DATC_FragranceBttnMnlSet "Fragrance Button Manual Set (¹ßÇâ ±â´É ¹öÆ° ¼öµ¿ ÀÔ·Â)";
CM_ SG_ 140 ATS_DATC_TempUnitSet "Temp Unit Set (¿Âµµ ´ÜÀ§ ¼³Á¤)";
CM_ BO_ 607 "[PE] Periodic and On Event";
CM_ SG_ 607 ATS_RRStSldFwdBtn "Rear Right Power Seat Slide Forward Touch Button";
CM_ SG_ 607 ATS_RRStSldBwdBtn "Rear Right Power Seat Slide Backward Touch Button";
CM_ SG_ 607 ATS_RRStRclFwdBtn "Rear Right Power Seat Recline Forward Touch Button";
CM_ SG_ 607 ATS_RRStRclBwdBtn "Rear Right Power Seat Recline Backward Touch Button";
CM_ SG_ 607 ATS_RRStTltUpBtn "Rear Right Power Seat Tilt Up Touch Button";
CM_ SG_ 607 ATS_RRStTltDnBtn "Rear Right Power Seat Tilt Down Touch Button";
CM_ SG_ 607 ATS_RRStLegRestPopBtn "Rear Right Leg Rest Move Pop Up Button";
CM_ SG_ 607 ATS_RRStFRestPopBtn "Rear Right Foot Rest Move Pop Up Button";
CM_ SG_ 607 ATS_RRStAstPopBtn "Rear Right Assist Seat Move Pop Up Button";
CM_ SG_ 607 ATS_RRFauCondiBtn "Rear Right FAU Operational Condition Move Button";
CM_ SG_ 607 ATS_RRStHRestUpBtn "Rear Right Power Seat Head Rest Up Touch Button";
CM_ SG_ 607 ATS_RRStHRestDnBtn "Rear Right Power Seat Head Rest Down Touch Button";
CM_ SG_ 607 ATS_RRStHRestFwdBtn "Rear Right Power Seat Head Rest Forward Touch Button";
CM_ SG_ 607 ATS_RRStHRestBwdBtn "Rear Right Power Seat Head Rest Backward Touch Button";
CM_ SG_ 607 ATS_RRStShoulderADJFwdBtn "Rear Right Power Seat Shoulder Adjuster Forward Touch Button";
CM_ SG_ 607 ATS_RRStShoulderADJBwdBtn "Rear Right Power Seat Shoulder Adjuster Backward Touch Button";
CM_ SG_ 607 ATS_RRStLegRestUpBtn "Rear Right Power Seat Leg Rest Up Touch Button";
CM_ SG_ 607 ATS_RRStLegRestDnBtn "Rear Right Power Seat Leg Rest Down Touch Button";
CM_ SG_ 607 ATS_RRStLegRestExtUpBtn "Rear Right Power Seat Leg Rest Ext. Up Touch Button";
CM_ SG_ 607 ATS_RRStLegRestExtDnBtn "Rear Right Power Seat Leg Rest Ext. Down Touch Button";
CM_ BO_ 1216 "[EC] On Event and On Change";
CM_ SG_ 1216 BCM_Crc1Val "BCM_CyclicRedundancyCheck1Value";
CM_ SG_ 1216 BCM_AlvCnt1Val "BCM_AliveCounter1Value";
CM_ SG_ 1216 PHEV_FuelDrReleaseSwSta "PHEV_FuelDoorReleaseSwitchStatus ##2G##BCM - BCMmsg01 - C_FuelDrReleaseSw";
CM_ SG_ 1216 BAlarm_AutoLockrReq "BAlarm_AutoLockRequest ##2G##BCM - BCMmsg01 - C_AutoLockCmd";
CM_ BO_ 2323816449 "[EC] On Event and On Change";
CM_ SG_ 2323816449 C_CtrlDrLockRlyCCS_Copy_2 "Command for Remote Door Lock";
CM_ SG_ 2323816449 C_TeleHeatingCmdIBOX_Copy_2 "'Command for Remote Heating

(Steering Wheel, Rear Window, Side Mirror)";
CM_ SG_ 2323816449 C_TeleStrgWhlHeatingCmdIBOX_Copy_2 "'Command for Remote Heating
(Steering Wheel)";
CM_ SG_ 2323816449 C_TeleDefoggerHeatingCmdIBOX_Copy_2 "'Command for Remote Heating
(Rear Window, Side Mirror)";
CM_ SG_ 2323816449 C_TeleDrvSeatOpCmdIBOX_Copy_2 "Command for Remote Seat Heat/Vent control (Driver)";
CM_ SG_ 2323816449 C_CtrlDrUnlockRlyCCS_Copy_2 "Command for Remote Door UnLock";
CM_ SG_ 2323816449 C_TeleAstSeatOpCmdIBOX_Copy_2 "Command for Remote Seat Heat/Vent control (Passenger)";
CM_ SG_ 2323816449 C_TeleRRSeatOpCmdIBOX_Copy_2 "Command for Remote Seat Heat/Vent control (Rear Right)";
CM_ SG_ 2323816449 C_TeleRLSeatOpCmdIBOX_Copy_1 "Command for Remote Seat Heat/Vent control (Rear Left)";
CM_ SG_ 2323816449 C_BlindCmdAVN_Copy_2 "This signal indicates Sunroof Blind Open/Close Command";
CM_ SG_ 2323816449 C_GlassCmdAVN_Copy_2 "This signal indicates Sunroof Glass Open/Close Command";
CM_ SG_ 2323816449 C_DrvWindowCmdAVN_Copy_2 "This signal indicates DRV Window Open/Close Command";
CM_ SG_ 2323816449 C_HazardFromCCS_Copy_2 "Command for Remote Hazard";
CM_ SG_ 2323816449 C_AstWindowCmdAVN_Copy_2 "This signal indicates AST Window Open/Close Command";
CM_ SG_ 2323816449 C_RRWindowCmdAVN_Copy_2 "This signal indicates RR Window Open/Close Command";
CM_ SG_ 2323816449 C_RLWindowCmdAVN_Copy_2 "This signal indicates RL Window Open/Close Command";
CM_ SG_ 2323816449 TailCtrlReq_Copy "This signal is for cotroling Tail lamp.";
CM_ SG_ 2323816449 HazardCtrlReq_Copy "This signal is request for controling Hazard lamp.";
CM_ SG_ 2323816449 HU_DATC_AirCleaningSet_Copy_1 "Air Cleaning System set";
CM_ SG_ 2323816449 C_PanicFromCCS_Copy_2 "Command for Remote Panic (Only for USA)";
CM_ SG_ 2323816449 C_TeleFrontHeatingCmdIBOX_Copy_1 "Command for Remote Heating (Front Window)";
CM_ SG_ 2323816449 RAC_AirCleaningCtrlReq_Copy_1 "RAC_Air Cleaning Control Request";
CM_ SG_ 2323816449 C_PreCrankReq_Copy "Command for B-CAN wake up singal (Need to send this signal before other remote commands)";
CM_ BO_ 2323816450 "[EC] On Event and On Change";
CM_ SG_ 2323816450 HU_CDMOpenCmd_Copy_1 "Command for CDM open/close";
CM_ SG_ 2323816450 C_EsyAcsProfileID_CCU "This signal indicates the current detected profile ID by smartphone APP.
(The drv seat move to the easy access position of the detected profile ID when receive the signal)";
CM_ BO_ 2323816451 "[EC] On Event and On Change";
CM_ BO_ 2323816452 "[EC] On Event and On Change";
CM_ BO_ 679 "[PE] Periodic and On Event";
CM_ SG_ 679 CMS_RH_Crc1Val "CMS_RH_CyclicRedundancyCheck1Value";
CM_ SG_ 679 CMS_RH_AlvCnt1Val "CMS_RH_AliveCounter1Value";
CM_ SG_ 679 CMS_RHVerPosVal "RH Outside Mirror Vertical Position sensor value";
CM_ SG_ 679 CMS_RHHorPosVal "RH Outside Mirror Horizontal Position sensor value";
CM_ BO_ 2382594049 "[PE] Periodic and On Event";
CM_ SG_ 2382594049 DATC_Crc3Val "DATC_CyclicRedundancyCheck3Value";
CM_ SG_ 2382594049 DATC_AlvCnt3Val "DATC_AliveCounter3Value";
CM_ SG_ 2382594049 DATC_DrvTempCDis "DATC_DriverTemperatureCelciusDisplay";
CM_ SG_ 2382594049 DATC_DrvTempFDis "DATC_DriverTemperatureFahrenheitDisplay";
CM_ SG_ 2382594049 DATC_PassTempCDis "DATC_PassengerTemperatureCelciusDisplay";
CM_ SG_ 2382594049 DATC_PassTempFDis "DATC_PassengerTemperatureFahrenheitDisplay";
CM_ SG_ 2382594049 DATC_TempDispSta "DATCTempDisplayStatus";
CM_ SG_ 2382594049 DATC_PreEngOnReq2 "Pre Engine On Request";
CM_ BO_ 687 "[P] Periodic";
CM_ SG_ 687 HOD_Crc1Val "HOD_CyclicRedundancyCheck1Value";
CM_ SG_ 687 HOD_AlvCnt1Val "HOD_AliveCounter1Value";
CM_ SG_ 687 HOD_Dir_Status "hands on-off status";
CM_ SG_ 687 HOD_Option "HOD_Option";
CM_ SG_ 687 HOD_CapaCh0 "Front zone Capacitance value(pF)";
CM_ SG_ 687 HOD_CapaCh1 "Rear zone Capacitance value(pF)";
CM_ BO_ 2176872449 "[P] Periodic";
CM_ SG_ 2176872449 HTCU_Crc5Val "HTCU_CyclicRedundancyCheck5Value";
CM_ SG_ 2176872449 HTCU_AlvCnt5Val "HTCU_AliveCounter5Value";
CM_ SG_ 2176872449 HDCT_AddtnlTqLssVal "Additional Torque Loss Value ## TCU16 - CR_Tcu_AddTqLoss_Pc";
CM_ SG_ 2176872449 HDCT_OBDSta "OBD Status ## TCU16 - CF_Tcu_ObdStat";
CM_ SG_ 2176872449 HDCT_OBDErrSta "OBD Error Status ## TCU16 - CF_Tcu_ObdRelErr";
CM_ SG_ 2176872449 HDCT_StcShftLrchCtrl "Static Shift Lurch Control ## TCU16 - CF_Tcu_StaticLurchCtl";
CM_ SG_ 2176872449 HDCT_EngCltchLmphmMod "Engine Clutch Limphome Mode ## TCU16 - CF_Tcu_CltLimAct";
CM_ SG_ 2176872449 HDCT_CurrPrgrm "Current Program ## TCU16 - CF_Tcu_CurProgram";
CM_ SG_ 2176872449 HDCT_FltSta "TCU fault status ## TCU16 - CF_Tcu_Flt";
CM_ SG_ 2176872449 HDCT_MCUAntJrkInhbt "MCU Anti-Jerk Inhibition ## TCU16 - CF_Tcu_MCUAntiJerkInh";
CM_ SG_ 2176872449 HDCT_TrgtGear "Target Gear ## TCU11 - CF_Tcu_TarGe";
CM_ SG_ 2176872449 HDCT_CurrGear "Current Gear ## TCU11 - HDCT_CurrGear";
CM_ SG_ 2176872449 HDCT_GearSelDis "Gear Select Display ## TCU11 - CF_Tcu_GarSelDisp";
CM_ BO_ 2176872450 "[P] Periodic";
CM_ SG_ 2176872450 HDCT_TCURdySta "TCU Ready Status ## TCU11 - CF_Tcu_Rdy";
CM_ SG_ 2176872450 HDCT_NetrlCtrlSta "Neutralize Control Status ## TCU11 - CF_Tcu_NeutAck";
CM_ SG_ 2176872450 HDCT_GearShftSta "Gear Shfit Status ## TCU11 - CF_Tcu_GarChange";
CM_ SG_ 2176872450 HDCT_TqRdctnVal "Torque Reduction Value ## TCU11 - CR_Tcu_TqRedReq_Pc";
CM_ SG_ 2176872450 HDCT_CtrlablSta "Controllable Status ## TCU11 - CF_Tcu_Cont";
CM_ SG_ 2176872450 HTCU_SlwTqRdctnVal "Slow Torque Reduction Value ## TCU11 - CR_Tcu_TqRedReqSlw_Pc";
CM_ SG_ 2176872450 HDCT_TqIncReq "Torque Increase Request ## TCU11 - CF_Tcu_TqIncReq";
CM_ SG_ 2176872450 HDCT_TqIncVal "Torque Increase Value ## TCU11 - CR_Tcu_TqIncReq_Pc";
CM_ SG_ 2176872450 HDCT_TrgtShftCls "Target Shift Class ## TCU11 - CF_Tcu_ShiftClass";
CM_ SG_ 2176872450 HDCT_EOLReq "EOL Request ## DCT_TCU1 - CF_Tcu_DCT_EOLReq";
CM_ SG_ 2176872450 HDCT_CltchSta "Clutch Status ## DCT_TCU1 - CF_Tcu_CltStat";
CM_ SG_ 2176872450 HDCT_DblCltchSta "Double Clutch Status ## DCT_TCU1 - CF_Tcu_DCT_CltState";
CM_ SG_ 2176872450 HDCT_AcnChrgInhbtReq "Aircon Change Inhibit Request ## DCT_TCU1 - CF_Tcu_ChgInhAC";
CM_ SG_ 2176872450 HDCT_SlipCrnkAllw "Slip Crank Allow ## DCT_TCU1 - CF_Tcu_SlipCrk_Allow";
CM_ SG_ 2176872450 HDCT_KckDnSkpShftCnt "Kick Down Skip Shift Count ## DCT_TCU1 - CF_Tcu_KD_SkipShft_Cnt";
CM_ SG_ 2176872450 HDCT_ShftPhase "Shift Phase ## TCU11 - CF_Tcu_ShiftPhase";
CM_ BO_ 2176872451 "[P] Periodic";
CM_ SG_ 2176872451 HDCT_FuelCutReq "Fuel Cut Request ## DCT_TCU1 - CF_Tcu_FuelCutReq";
CM_ SG_ 2176872451 HDCT_NCoastTrgtGear "N Coast Target Gear ## DCT_TCU1 - CR_Tcu_NCoastTgtGear";
CM_ SG_ 2176872451 HDCT_CLUEngSpdFlag "Cluster Engine Speed Flag ## DCT_TCU1 - Cluster_Engine_RPM_Flag";
CM_ SG_ 2176872451 HDCT_CLUTrgtGear "Clutster Target Gear ## DCT_TCU1 - CF_Tcu_TarGeforCLU";
CM_ SG_ 2176872451 HDCT_GSITrgtGear "GSI Target Gear ## DCT_TCU1 - CF_Tcu_GSITgtGear";
CM_ SG_ 2176872451 HDCT_NCoastDnReq "N Coast Down Request ## DCT_TCU1 - CF_Tcu_NcoastDwnReq";
CM_ SG_ 2176872451 HDCT_CLUEngSpd "Clutster Engine Speed ## DCT_TCU1 - Cluster_Engine_RPM";
CM_ BO_ 676 "[EC] On Event and On Change";
CM_ SG_ 676 C_DrAirSptNValueSet_EC "Driver Seat Smart Air Support On/Off";
CM_ SG_ 676 C_DrCushSoftNValueSet_EC "Driver Seat Cushion Softness";
CM_ SG_ 676 C_AstAirSptNValueSet_EC "Assistant Seat Smart Air Support On/Off";
CM_ SG_ 676 C_DrBackSoftNValueSet_EC "Driver Seat Back Softness";
CM_ SG_ 676 C_AstAirSptModeNValueSet_EC "Assistant Seat Smart Air Support Mode";
CM_ SG_ 676 C_DrAirSptModeNValueSet_EC "Driver Seat Smart Air Support Mode";
CM_ SG_ 676 C_RLAirSptNValueSet_EC "2nd Left Seat Smart Air Support On/Off";
CM_ SG_ 676 C_AstAirSptStrNValueSet_EC "Assistant Seat Smart Air Support Strength";
CM_ SG_ 676 C_AstAirSptTimeNValueSet_EC "Assistant Seat Smart Air Support Time";
CM_ SG_ 676 C_RRAirSptNValueSet_EC "2nd Right side seat Smart Air Support On/Off";
CM_ SG_ 676 C_AstCushSoftNValueSet_EC "Assistant Seat Cushion Softness off/low/mid/high";
CM_ SG_ 676 C_AstBackSoftNValueSet_EC "Assistant Seat Back Softness Off/Low/Mid/High";
CM_ SG_ 676 C_AstRlxNValueSet_EC "Assistant seat Moving control : Relaxtion mode";
CM_ SG_ 676 C_RLAirSptModeNValueSet_EC "2nd Left Seat Smart Air Support Mode";
CM_ SG_ 676 C_DrAirSptStrNValueSet_EC "Driver Seat Smart Air Support Strength";
CM_ SG_ 676 C_RLAirSptStrNValueSet_EC "2nd Left Seat Smart Air Support Strength";
CM_ SG_ 676 C_RLAirSptTimeNValueSet_EC "2nd Left Seat Smart Air Support Time";
CM_ SG_ 676 C_DrAirSptTimeNValueSet_EC "Driver Seat Smart Air Support Time";
CM_ BO_ 677 "[EC] On Event and On Change";
CM_ SG_ 677 C_RLBackSoftNValueSet_EC "2nd Left Seat Back Softness";
CM_ SG_ 677 C_RRAirSptStrNValueSet_EC "2nd Right side seat Smart Air Support Strength";
CM_ SG_ 677 C_RRAirSptTimeNValueSet_EC "2nd Right side seat Smart Air Support Time";
CM_ SG_ 677 C_RRBackSoftNValueSet_EC "2nd Right side seat Back Softness";
CM_ SG_ 677 C_RROneTchNvalueSet_EC "2nd Right side seat One Touch Mode";
CM_ SG_ 677 C_RLOneTchNValueSet_EC "2nd Left side seat One Touch Mode";
CM_ SG_ 677 C_RRAirSptModeNValueSet_EC "2nd Right side seat Moving control : Smart Air Support Mode";
CM_ BO_ 1219 "[EC] On Event and On Change";
CM_ SG_ 1219 BLTN_CAM_Rec_OWD_NvalueSet "Record On/Off Set of On While Driving";
CM_ SG_ 1219 BLTN_CAM_Time_Stm_NvalueSet "Record Set of Date and Time Stamp";
CM_ SG_ 1219 BLTN_CAM_Spd_Stm_NvalueSet "Record Set of Speed Stamp";
CM_ SG_ 1219 BLTN_CAM_Locatn_Stm_NvalueSet "Record Set of Location Stamp";
CM_ SG_ 1219 BLTN_CAM_TrnSig_Stm_NvalueSet "Record Set of Turn Signal Stamp";
CM_ SG_ 1219 BLTN_CAM_AclBrk_Stm_NvalueSet "Record Set of Accelerator Brake Stamp";
CM_ SG_ 1219 BLTN_CAM_Rec_DEV_NvalueSet "Record On/Off Set of Driving Event";
CM_ SG_ 1219 BLTN_CAM_GearPos_Stm_NvalueSet "Record Set of Gear Position Stamp";
CM_ SG_ 1219 BLTN_CAM_EVSen_Stm_NvalueSet "Record Set of Event Sensitivity Stamp";
CM_ SG_ 1219 BLTN_CAM_Strangl_Stm_NvalueSet "Record Set of Steering Angle Stamp";
CM_ SG_ 1219 BLTN_CAM_PrkTime_NvalueSet "Parking Operation Setting Time, Resolution : hr";
CM_ SG_ 1219 BLTN_CAM_EV_BfrTime_NvalueSet "Driving Event Time Setting - Before, Resolution : sec";
CM_ SG_ 1219 BLTN_CAM_Rec_OWP_NvalueSet "Record On/Off Set of On While Parked, 0x0(Default) : Parking recording function not supported";
CM_ SG_ 1219 BLTN_CAM_EV_AftTime_NvalueSet "Driving Event Time Setting - After, Resolution : sec";
CM_ SG_ 1219 BLTN_CAM_TML_Int_NvalueSet "Record Set of Time-lapse Interval, Resolution : sec";
CM_ SG_ 1219 BLTN_CAM_Sen_DEV_NvalueSet "Set of Event  Detection Sensitivity of Driving Mode";
CM_ SG_ 1219 BLTN_CAM_Sen_PEV_NvalueSet "Set of Event  Detection Sensitivity of Parking Mode";
CM_ SG_ 1219 BLTN_CAM_Rec_PEV_NvalueSet "Record Set of Parked Event, 0x0(Default) : Parking recording function not supported";
CM_ SG_ 1219 BLTN_CAM_AudRec_NvalueSet "Audio Record On/Off Set";
CM_ BO_ 1239 "[PE] Periodic and On Event";
CM_ SG_ 1239 HU_ADMSettingState "Information for ADM(Accessry Delay Mode) Setting Vaule in HU / Made at 2021.1.25";
CM_ SG_ 1239 HU_VehiclePwr "Information for the H/U power status for ADM(Accessary Delay Mode)";
CM_ BO_ 1221 "[EC] On Event and On Change";
CM_ SG_ 1221 HU_ChgInCurrModSet "Charge current set signal";
CM_ SG_ 1221 SWRC_Sensitivity_SET "SWRC_OpticalSwtich_Sensitivity_Setting";
CM_ SG_ 1221 HU_EV_WinterMode "<For after OS/DE/SK3 EV/AE PE EV>

EV Battery temp. up setting on/off 
- setting signal : CR_Bms_WinterMode";
CM_ SG_ 1221 HU_TgSoc_ScChg_Set "<For after OS/DE/SK3 EV>
Target SOC user setting value for slow charger(SC/AC).
- For EV only";
CM_ SG_ 1221 HU_TgSoc_QcChg_Set "<For after OS/DE/SK3 EV>
Target SOC user setting value for fast charger(QC/DC).
- For EV only";
CM_ BO_ 1218 "[EC] On Event and On Change";
CM_ SG_ 1218 C_AVN_PTGHeightNValueSet "Power Tailgate(Trunk) Height Request Signal";
CM_ SG_ 1218 CF_AVN_SCCMLReset "Request for SCC-ML reset";
CM_ SG_ 1218 C_HAnBNValueSet "USM Request for Horn Feedback";
CM_ SG_ 1218 CF_AVN_RrSeatRemindNValueSet "USM Request for Rear Seat Remind function";
CM_ SG_ 1218 CF_AVN_DSWNValueSet "Request for driver state warning";
CM_ SG_ 1218 CF_AVN_RRPSU_RLNValueSet "Request for Seat easy access of rear left seat";
CM_ SG_ 1218 CF_AVN_APSUNValueSet "Request for easy access of passenger seat";
CM_ SG_ 1218 CF_AVN_NCC_CameraNValueSet "Request for Eco Vehicle NCC";
CM_ SG_ 1218 CF_AVN_RRPSU_RRNValueSet "Request for seat easy access of rear right seat";
CM_ SG_ 1218 CF_AVN_HtBlcAstNValueSet "Request for Passenger seat heater balance";
CM_ SG_ 1218 CF_AVN_HtBlcDrvNValueSet "Request for Driver seat heater balance";
CM_ SG_ 1218 CF_AVN_SCCModeNValueSet "This signal request for scc setting(Whether sccml or following driving mode)";
CM_ SG_ 1218 CF_AVN_SCCMLChar1Set "Request for scc-ml acceleration learning result change";
CM_ SG_ 1218 CF_AVN_UIPNValueSet "USM Request for Ultrasonic Intrusion Protection function";
CM_ SG_ 1218 CF_AVN_SCCMLChar2Set "Request for scc-ml distnace learning result change";
CM_ SG_ 1218 CF_AVN_SCCMLChar3Set "Request for scc-ml reaction learning result change";
CM_ SG_ 1218 CF_AVN_HDALCFuncNValueSet "Request for highway lane change assist";
CM_ BO_ 675 "[EC] On Event and On Change";
CM_ SG_ 675 CF_AVN_HtBlcRLNValueSet "Request for 2nd Left seat heater balance";
CM_ SG_ 675 CF_AVN_ISLA_AutoNModSet "USM Set Signal for Activing N Mode Setting when Vehicle enter into Winding Road";
CM_ SG_ 675 CF_AVN_HtBlcRRNValueSet "Request for 2nd Right seat heater balance";
CM_ SG_ 675 CF_AVN_RemoteWDWNValueSet "Remote Window On/Off Set signal of USM for Fob Key";
CM_ SG_ 675 USM_TowWeight_Set "Trailer Mode Setting USM: Tow Weight set for User";
CM_ SG_ 675 CF_AVN_PABArbgNValueSet "USM PAB On/Off Set Signal";
CM_ SG_ 675 CF_AVN_SportHUD2 "Related to HUD Sports mode of custom mode2";
CM_ SG_ 675 HU_CustomNewMenuSet "Custom Mode User Setting Signal";
CM_ SG_ 675 USM_RpmComfortRearSet "RPM Display Setting When Comfort(Rear) mode Set";
CM_ SG_ 675 Usm_RpmMyDriveModeSet "Cluster MY Drive Mode RPM Set Signal";
CM_ SG_ 675 CF_AVN_PCA_RrEquipNvalueSet "Headunit Setting signal for Rear Safety of USM";
CM_ BO_ 1076 "[PE] Periodic and On Event";
CM_ SG_ 1076 IAU_ProfileIDRVal "This signal Indicate the Current detected Profile ID by IAU.";
CM_ SG_ 1076 IAU_DigitalKeyProcessingSta "Digital Key USM settitng Process State";
CM_ SG_ 1076 IAU_DigitalKeyExit "Digital Key USM setting Exit Condition";
CM_ SG_ 1076 IAU_DigitalKeyEnblRVal "Digital Key Function Enable / Disable flag (Fob is required for changing flag)";
CM_ SG_ 1076 IAU_OwnerPhnRegRVal "Vehicle Owner's Phone is Registered for Digital Key function";
CM_ SG_ 1076 IAU_NFCCard1RegRVal "NFC Card 1 is Registered for Digital Key function";
CM_ SG_ 1076 IAU_NFCCard2RegRVal "NFC Card 2 is Registered for Digital Key function";
CM_ SG_ 1076 IAU_DigitalKey2Opt "Digital Key2 Option Signal";
CM_ BO_ 1227 "[EC] On Event and On Change";
CM_ SG_ 1227 DrvIMS_MemoryP1Req "PSM_DriverSeatPositionMemoryP1Request";
CM_ SG_ 1227 DrvIMS_PlyBckP2Req "PSM_PlayBackP2Request";
CM_ SG_ 1227 DrvIMS_PlyBckP3Req "PSM_PlayBackP3Request";
CM_ SG_ 1227 DrvIMS_PlyBckStpReq "PSM_PlayBackStopRequest";
CM_ SG_ 1227 SmrtIMS_PlyBckReq "HCIMS_PlayBackRequest";
CM_ SG_ 1227 DrvIMS_MemoryP2Req "PSM_DriverSeatPositionMemoryP2Request";
CM_ SG_ 1227 SmrtIMS_ImgDBVal "Smart IMS image DB number";
CM_ SG_ 1227 SmrtIMS_PlyBckStpReq "HCIMS_Status";
CM_ SG_ 1227 DrvIMS_MemoryP3Req "PSM_DriverSeatPositionMemoryP3Request";
CM_ SG_ 1227 SmrtIMS_EnterSwSta "Smart IMS switch on using IMS switch";
CM_ SG_ 1227 DrvIMS_BzrReq "PSM_DriverSeatImsBuzzerRequest";
CM_ SG_ 1227 DrvIMS_ErrConWmgDis "Warning about IMS Mem/Play Error Condition";
CM_ SG_ 1227 Drv_AutoRlxWrngDis "Drive seat auto relax warning information for AVN display";
CM_ SG_ 1227 DrvIMS_MemorySetEnaSta "PSM_MemorySetEnableStatus";
CM_ SG_ 1227 DrvIMS_PlyBckP1Req "PSM_PlayBackP1Request";
CM_ BO_ 1237 "[EC] On Event and On Change";
CM_ SG_ 1237 SWRC_Crc2Val "SWRC_CyclicRedundancyCheck2Value";
CM_ SG_ 1237 SWRC_AlvCnt2Val "SWRC_AliveCounter2Value";
CM_ SG_ 1237 Audio_VolEncoderSta "Audio_VolumeScrollSwitchStatus";
CM_ SG_ 1237 Cluster_ScrlEncoderSta "Cluster_ScrollSwitchStatus";
CM_ BO_ 139 "[PE] Periodic and On Event";
CM_ BO_ 2160080130 "[P] Periodic";
CM_ SG_ 2160080130 VCU_FatcPwrUseVal "VCU_FatcPowerUseValue ##2G##VCU - VCU5 - CR_Vcu_FatcCst";
CM_ SG_ 2160080130 VCU_McuAntiJerkInhFrntSta "VCU_McuAntiJerkInhibitionFrontStatus";
CM_ SG_ 2160080130 VCU_McuAntiJerkInhRearSta "VCU_McuAntiJerkInhibitionRearStatus ##2G##VCU - VCU3 - CF_Vcu_MCUAntiJerkInh";
CM_ SG_ 2160080130 VCU_McuPwrLatchHoldReq "VCU_McuPowerLatchHoldRequest ##2G##VCU - VCU20 - CF_Vcu_McuPwrLatchHoldReq";
CM_ SG_ 2160080130 VCU_ScuParkReq "VCU_ScuParkingRequest ##2G##VCU - VCU12 - CF_Vcu_PARKCMD";
CM_ SG_ 2160080130 VCU_MotTqCmdFrntVal "VCU_MotorTorqueCommandFrontValue";
CM_ SG_ 2160080130 VCU_ScuKeepWakeReq "VCU_ScuKeepWakeRequest ##2G##VCU - VCU12 - CF_Vcu_SSD";
CM_ SG_ 2160080130 VCU_MotTqCmdRearVal "VCU_MotorTorqueCommandRearValue";
CM_ SG_ 2160080130 VCU_FmcuZeroTqOfsReq "VCU_FmcuZeroTorqueOffsetRequest";
CM_ SG_ 2160080130 VCU_WhlDemTqVal "VCU_WheelDemandTorqueValue ##2G##VCU - VCU2 - CR_Vcu_WhlDemTq_Nm";
BA_DEF_ BO_ "DiagState" ENUM "No","Yes" ;
BA_DEF_ BO_ "DiagResponse" ENUM "No","Yes" ;
BA_DEF_ BO_ "DiagRequest" ENUM "No","Yes" ;
BA_DEF_ BO_ "TpMessage" ENUM "No","Yes" ;
BA_DEF_ BO_ "UsrMsgIDSforwardDeviation" INT 0 100 ;
BA_DEF_ BO_ "UsrMsgIDSbackwardDeviation" INT 50 1000 ;
BA_DEF_ BO_ "GenMsgCycleTime" INT 0 2000 ;
BA_DEF_ BO_ "GenMsgStartDelayTime" INT 0 2000 ;
BA_DEF_ BO_ "GenMsgSendType" ENUM "Cyclic","NoMsgSendType" ;
BA_DEF_ BO_ "GenMsgCycleTimeFast" INT 0 500 ;
BA_DEF_ BO_ "GenMsgDelayTime" INT 0 20 ;
BA_DEF_ BO_ "GenMsgILSupport" ENUM "No","Yes" ;
BA_DEF_ BO_ "GenMsgNrOfRepetition" INT 0 3 ;
BA_DEF_ BO_ "NmMessage" ENUM "No","Yes" ;
BA_DEF_ BO_ "NWM-Botschaft" ENUM "No","Yes" ;
BA_DEF_ BO_ "TpTxIndex" INT 0 255 ;
BA_DEF_ BO_ "VFrameFormat" ENUM "StandardCAN","ExtendedCAN","reserved","reserved","reserved","reserved","reserved","reserved","reserved","reserved","reserved","reserved","reserved","reserved","StandardCAN_FD","ExtendedCAN_FD" ;
BA_DEF_ SG_ "UserSigValidity" ENUM "B+","ACC","IG","IG1","IG2","IG3","IG1 or IG2","IG1 or IG3","Undef" ;
BA_DEF_ SG_ "TimeoutValue" STRING ;
BA_DEF_ SG_ "UsrSigPurpose" ENUM "Undef","FN","DIAG","DIAG(Req)","DIAG(Res)","DIAG(Phy)","DEV","CCP(Req)","CCP(Res)","NM","TP" ;
BA_DEF_ SG_ "GenSigStartValue" INT 0 1215752192 ;
BA_DEF_ SG_ "NetworkRequest" ENUM "Yes","No" ;
BA_DEF_ SG_ "NetworkRequestHoldingTime" INT 0 65535 ;
BA_DEF_ SG_ "Description" STRING ;
BA_DEF_ SG_ "Version" STRING ;
BA_DEF_ SG_ "GenSigEnvVarType" ENUM "Int","Float","Undef" ;
BA_DEF_ SG_ "GenSigSendType" ENUM "Cyclic","OnWrite","OnWriteWithRepetition","OnChange","OnChangeWithRepetition","IfActive","IfActiveWithRepetition","NoSigSendType","OnChangeAndIfActive","OnChangeAndIfActiveWithRepetition" ;
BA_DEF_ SG_ "GwSigLatencyTime" INT 0 65536 ;
BA_DEF_ SG_ "GwSigMissingSourceType" ENUM "Undef","OldValue","DefaultValue","InitialValue" ;
BA_DEF_ SG_ "NWM-WakeupAllowed" ENUM "<n.a.>" ;
BA_DEF_ SG_ "RoutingFactor" INT 1 1215752192 ;
BA_DEF_REL_ BU_SG_REL_ "GenSigTimeoutTime" INT 0 7000 ;
BA_DEF_DEF_ "DiagState" "No" ;
BA_DEF_DEF_ "DiagResponse" "No" ;
BA_DEF_DEF_ "DiagRequest" "No" ;
BA_DEF_DEF_ "TpMessage" "No" ;
BA_DEF_DEF_ "UsrMsgIDSforwardDeviation" 10 ;
BA_DEF_DEF_ "UsrMsgIDSbackwardDeviation" 100 ;
BA_DEF_DEF_ "GenMsgCycleTime" 200 ;
BA_DEF_DEF_ "GenMsgStartDelayTime" 0 ;
BA_DEF_DEF_ "GenMsgSendType" "NoMsgSendType" ;
BA_DEF_DEF_ "GenMsgCycleTimeFast" 40 ;
BA_DEF_DEF_ "GenMsgDelayTime" 20 ;
BA_DEF_DEF_ "GenMsgILSupport" "Yes" ;
BA_DEF_DEF_ "GenMsgNrOfRepetition" 3 ;
BA_DEF_DEF_ "NmMessage" "No" ;
BA_DEF_DEF_ "NWM-Botschaft" "No" ;
BA_DEF_DEF_ "TpTxIndex" 0 ;
BA_DEF_DEF_ "VFrameFormat" "StandardCAN" ;
BA_DEF_DEF_ "UserSigValidity" "IG" ;
BA_DEF_DEF_ "TimeoutValue" "" ;
BA_DEF_DEF_ "UsrSigPurpose" "FN" ;
BA_DEF_DEF_ "GenSigStartValue" 0 ;
BA_DEF_DEF_ "NetworkRequest" "No" ;
BA_DEF_DEF_ "NetworkRequestHoldingTime" 0 ;
BA_DEF_DEF_ "Description" "" ;
BA_DEF_DEF_ "Version" "" ;
BA_DEF_DEF_ "GenSigEnvVarType" "Undef" ;
BA_DEF_DEF_ "GenSigSendType" "NoSigSendType" ;
BA_DEF_DEF_ "GwSigLatencyTime" 40 ;
BA_DEF_DEF_ "GwSigMissingSourceType" "Undef" ;
BA_DEF_DEF_ "NWM-WakeupAllowed" "<n.a.>" ;
BA_DEF_DEF_ "RoutingFactor" 1 ;
BA_DEF_DEF_REL_ "GenSigTimeoutTime" 500 ;
BA_ "GenMsgCycleTime" BO_ 678 0;
BA_ "GenSigSendType" SG_ 678 Ast_AutoRlxWrngDis 4;
BA_ "UserSigValidity" SG_ 678 Ast_AutoRlxWrngDis 1;
BA_REL_ "GenSigTimeoutTime" BU_SG_REL_ CGW_CCU SG_ 678 Ast_AutoRlxWrngDis 0;
BA_ "NetworkRequest" SG_ 678 Ast_AutoRlxWrngDis 0;
BA_ "NetworkRequestHoldingTime" SG_ 678 Ast_AutoRlxWrngDis 5000;
BA_ "RoutingFactor" SG_ 678 Ast_AutoRlxWrngDis 0;
BA_ "Version" SG_ 678 Ast_AutoRlxWrngDis "21.06.10";
BA_ "GenSigSendType" SG_ 678 APSM_IMSWngDis 4;
BA_ "UserSigValidity" SG_ 678 APSM_IMSWngDis 0;
BA_ "NetworkRequest" SG_ 678 APSM_IMSWngDis 0;
BA_ "NetworkRequestHoldingTime" SG_ 678 APSM_IMSWngDis 5000;
BA_ "RoutingFactor" SG_ 678 APSM_IMSWngDis 0;
BA_ "Version" SG_ 678 APSM_IMSWngDis "21.08.01";
BA_ "Description" SG_ 678 Ast_2ndLnkRtnStop "2¿­ ¿äÃ» µû¸¥ µ¿½Â¼® ¸±·º¼Ç ½ÃÆ® Ç¥ÁØÀ§Ä¡ ÀÌµ¿ °£ µ¿ÀÛ Áß´Ü ¹ß»ý ½Ã ÇÇµå¹é ½ÅÈ£";
BA_ "GenSigSendType" SG_ 678 Ast_2ndLnkRtnStop 4;
BA_ "UserSigValidity" SG_ 678 Ast_2ndLnkRtnStop 0;
BA_REL_ "GenSigTimeoutTime" BU_SG_REL_ RLPSU SG_ 678 Ast_2ndLnkRtnStop 0;
BA_REL_ "GenSigTimeoutTime" BU_SG_REL_ RRPSU SG_ 678 Ast_2ndLnkRtnStop 0;
BA_ "RoutingFactor" SG_ 678 Ast_2ndLnkRtnStop 0;
BA_ "Version" SG_ 678 Ast_2ndLnkRtnStop "22.02.01";
BA_ "GenMsgCycleTime" BO_ 140 0;
BA_ "Description" SG_ 140 ATS_DATC_FrPsModeSet "Àü¼® Á¶¼ö¼® Ãø ¸ðµå ¼³Á¤";
BA_ "GenSigSendType" SG_ 140 ATS_DATC_FrPsModeSet 4;
BA_ "UserSigValidity" SG_ 140 ATS_DATC_FrPsModeSet 3;
BA_REL_ "GenSigTimeoutTime" BU_SG_REL_ CGW_CCU SG_ 140 ATS_DATC_FrPsModeSet 0;
BA_ "Version" SG_ 140 ATS_DATC_FrPsModeSet "19.12.08";
BA_ "Description" SG_ 140 ATS_DATC_FrPsAutoSet "Àü¼® Á¶¼ö¼® Ãø AUTO ¼³Á¤";
BA_ "GenSigSendType" SG_ 140 ATS_DATC_FrPsAutoSet 4;
BA_ "UserSigValidity" SG_ 140 ATS_DATC_FrPsAutoSet 3;
BA_REL_ "GenSigTimeoutTime" BU_SG_REL_ CGW_CCU SG_ 140 ATS_DATC_FrPsAutoSet 0;
BA_ "Version" SG_ 140 ATS_DATC_FrPsAutoSet "19.12.08";
BA_ "Description" SG_ 140 ATS_DATC_FrPsBlowerSet "Àü¼® Á¶¼ö¼® Ãø ºí·Î¿ö ´Ü¼ö ¼³Á¤";
BA_ "GenSigSendType" SG_ 140 ATS_DATC_FrPsBlowerSet 4;
BA_ "GenSigStartValue" SG_ 140 ATS_DATC_FrPsBlowerSet 15;
BA_ "UserSigValidity" SG_ 140 ATS_DATC_FrPsBlowerSet 3;
BA_REL_ "GenSigTimeoutTime" BU_SG_REL_ CGW_CCU SG_ 140 ATS_DATC_FrPsBlowerSet 0;
BA_ "Version" SG_ 140 ATS_DATC_FrPsBlowerSet "19.12.08";
BA_ "Description" SG_ 140 ATS_DATC_FrPsBlowerUpDn "Àü¼® Á¶¼ö¼® Ãø ºí·Î¿ö Áõ°¨ ¼³Á¤";
BA_ "GenSigSendType" SG_ 140 ATS_DATC_FrPsBlowerUpDn 4;
BA_ "UserSigValidity" SG_ 140 ATS_DATC_FrPsBlowerUpDn 3;
BA_REL_ "GenSigTimeoutTime" BU_SG_REL_ CGW_CCU SG_ 140 ATS_DATC_FrPsBlowerUpDn 0;
BA_ "Version" SG_ 140 ATS_DATC_FrPsBlowerUpDn "19.12.08";
BA_ "Description" SG_ 140 ATS_DATC_FrDrMultiAutoBlower "Àü¼® ¿îÀü¼® Ãø ¸ÖÆ¼¿ÀÅäºí·Î¿ö ¼³Á¤";
BA_ "GenSigSendType" SG_ 140 ATS_DATC_FrDrMultiAutoBlower 4;
BA_ "UserSigValidity" SG_ 140 ATS_DATC_FrDrMultiAutoBlower 3;
BA_REL_ "GenSigTimeoutTime" BU_SG_REL_ CGW_CCU SG_ 140 ATS_DATC_FrDrMultiAutoBlower 0;
BA_ "Version" SG_ 140 ATS_DATC_FrDrMultiAutoBlower "19.12.08";
BA_ "Description" SG_ 140 ATS_DATC_FrPsMultiAutoBlower "Àü¼® Á¶¼ö¼® Ãø ¸ÖÆ¼¿ÀÅäºí·Î¿ö ¼³Á¤";
BA_ "GenSigSendType" SG_ 140 ATS_DATC_FrPsMultiAutoBlower 4;
BA_ "UserSigValidity" SG_ 140 ATS_DATC_FrPsMultiAutoBlower 3;
BA_REL_ "GenSigTimeoutTime" BU_SG_REL_ CGW_CCU SG_ 140 ATS_DATC_FrPsMultiAutoBlower 0;
BA_ "Version" SG_ 140 ATS_DATC_FrPsMultiAutoBlower "19.12.08";
BA_ "Description" SG_ 140 ATS_DATC_RrDrMultiAutoBlower "ÈÄ¼® ¿îÀü¼® Ãø ¸ÖÆ¼¿ÀÅäºí·Î¿ö ¼³Á¤";
BA_ "GenSigSendType" SG_ 140 ATS_DATC_RrDrMultiAutoBlower 4;
BA_ "UserSigValidity" SG_ 140 ATS_DATC_RrDrMultiAutoBlower 3;
BA_REL_ "GenSigTimeoutTime" BU_SG_REL_ CGW_CCU SG_ 140 ATS_DATC_RrDrMultiAutoBlower 0;
BA_ "Version" SG_ 140 ATS_DATC_RrDrMultiAutoBlower "19.12.08";
BA_ "Description" SG_ 140 ATS_DATC_FragranceStrhSet "Fragrance Strength Set (¹ßÇâ ±â´É Çâ ¼¼±â ¼³Á¤)";
BA_ "GenSigSendType" SG_ 140 ATS_DATC_FragranceStrhSet 4;
BA_ "GenSigStartValue" SG_ 140 ATS_DATC_FragranceStrhSet 7;
BA_ "UserSigValidity" SG_ 140 ATS_DATC_FragranceStrhSet 3;
BA_REL_ "GenSigTimeoutTime" BU_SG_REL_ CGW_CCU SG_ 140 ATS_DATC_FragranceStrhSet 0;
BA_ "Version" SG_ 140 ATS_DATC_FragranceStrhSet "20.03.01";
BA_ "Description" SG_ 140 ATS_DATC_FragranceKindSet "Fragrance Kind Set (¹ßÇâ ±â´É Çâ Á¾·ù ¼³Á¤)";
BA_ "GenSigSendType" SG_ 140 ATS_DATC_FragranceKindSet 4;
BA_ "GenSigStartValue" SG_ 140 ATS_DATC_FragranceKindSet 7;
BA_ "UserSigValidity" SG_ 140 ATS_DATC_FragranceKindSet 3;
BA_REL_ "GenSigTimeoutTime" BU_SG_REL_ CGW_CCU SG_ 140 ATS_DATC_FragranceKindSet 0;
BA_ "Version" SG_ 140 ATS_DATC_FragranceKindSet "20.03.01";
BA_ "Description" SG_ 140 ATS_DATC_FragranceBttnMnlSet "Fragrance Button Manual Set (¹ßÇâ ±â´É ¹öÆ° ¼öµ¿ ÀÔ·Â)";
BA_ "GenSigSendType" SG_ 140 ATS_DATC_FragranceBttnMnlSet 4;
BA_ "GenSigStartValue" SG_ 140 ATS_DATC_FragranceBttnMnlSet 3;
BA_ "UserSigValidity" SG_ 140 ATS_DATC_FragranceBttnMnlSet 3;
BA_REL_ "GenSigTimeoutTime" BU_SG_REL_ CGW_CCU SG_ 140 ATS_DATC_FragranceBttnMnlSet 0;
BA_ "Version" SG_ 140 ATS_DATC_FragranceBttnMnlSet "20.03.01";
BA_ "Description" SG_ 140 ATS_DATC_TempUnitSet "Temp Unit Set (¿Âµµ ´ÜÀ§ ¼³Á¤)";
BA_ "GenSigSendType" SG_ 140 ATS_DATC_TempUnitSet 4;
BA_ "GenSigStartValue" SG_ 140 ATS_DATC_TempUnitSet 3;
BA_ "UserSigValidity" SG_ 140 ATS_DATC_TempUnitSet 3;
BA_REL_ "GenSigTimeoutTime" BU_SG_REL_ CGW_CCU SG_ 140 ATS_DATC_TempUnitSet 0;
BA_ "Version" SG_ 140 ATS_DATC_TempUnitSet "20.04.02";
BA_ "GenMsgSendType" BO_ 607 0;
BA_ "Description" SG_ 607 ATS_RRStSldFwdBtn "ÈÄ¼® RH ½½¶óÀÌµù Àü¹æ ÀÌµ¿";
BA_ "GenSigSendType" SG_ 607 ATS_RRStSldFwdBtn 4;
BA_ "UserSigValidity" SG_ 607 ATS_RRStSldFwdBtn 3;
BA_ "NetworkRequest" SG_ 607 ATS_RRStSldFwdBtn 0;
BA_ "NetworkRequestHoldingTime" SG_ 607 ATS_RRStSldFwdBtn 5000;
BA_ "Version" SG_ 607 ATS_RRStSldFwdBtn "19.09.02";
BA_ "Description" SG_ 607 ATS_RRStSldBwdBtn "ÈÄ¼® RH ½½¶óÀÌµù ÈÄ¹æ ÀÌµ¿";
BA_ "GenSigSendType" SG_ 607 ATS_RRStSldBwdBtn 4;
BA_ "UserSigValidity" SG_ 607 ATS_RRStSldBwdBtn 3;
BA_ "NetworkRequest" SG_ 607 ATS_RRStSldBwdBtn 0;
BA_ "NetworkRequestHoldingTime" SG_ 607 ATS_RRStSldBwdBtn 5000;
BA_ "Version" SG_ 607 ATS_RRStSldBwdBtn "19.09.02";
BA_ "Description" SG_ 607 ATS_RRStRclFwdBtn "ÈÄ¼® RH ¸®Å¬¶óÀÌ´× Àü¹æ ÀÌµ¿";
BA_ "GenSigSendType" SG_ 607 ATS_RRStRclFwdBtn 4;
BA_ "UserSigValidity" SG_ 607 ATS_RRStRclFwdBtn 3;
BA_ "NetworkRequest" SG_ 607 ATS_RRStRclFwdBtn 0;
BA_ "NetworkRequestHoldingTime" SG_ 607 ATS_RRStRclFwdBtn 5000;
BA_ "Version" SG_ 607 ATS_RRStRclFwdBtn "19.09.02";
BA_ "Description" SG_ 607 ATS_RRStRclBwdBtn "ÈÄ¼® RH ¸®Å¬¶óÀÌ´× ÈÄ¹æ ÀÌµ¿";
BA_ "GenSigSendType" SG_ 607 ATS_RRStRclBwdBtn 4;
BA_ "UserSigValidity" SG_ 607 ATS_RRStRclBwdBtn 3;
BA_ "NetworkRequest" SG_ 607 ATS_RRStRclBwdBtn 0;
BA_ "NetworkRequestHoldingTime" SG_ 607 ATS_RRStRclBwdBtn 5000;
BA_ "Version" SG_ 607 ATS_RRStRclBwdBtn "19.09.02";
BA_ "Description" SG_ 607 ATS_RRStTltUpBtn "ÈÄ¼® RH Æ¿Æ® ¾÷ ÀÌµ¿";
BA_ "GenSigSendType" SG_ 607 ATS_RRStTltUpBtn 4;
BA_ "UserSigValidity" SG_ 607 ATS_RRStTltUpBtn 3;
BA_ "NetworkRequest" SG_ 607 ATS_RRStTltUpBtn 0;
BA_ "NetworkRequestHoldingTime" SG_ 607 ATS_RRStTltUpBtn 5000;
BA_ "Version" SG_ 607 ATS_RRStTltUpBtn "19.09.02";
BA_ "Description" SG_ 607 ATS_RRStTltDnBtn "ÈÄ¼® RH Æ¿Æ® ´Ù¿î ÀÌµ¿";
BA_ "GenSigSendType" SG_ 607 ATS_RRStTltDnBtn 4;
BA_ "UserSigValidity" SG_ 607 ATS_RRStTltDnBtn 3;
BA_ "NetworkRequest" SG_ 607 ATS_RRStTltDnBtn 0;
BA_ "NetworkRequestHoldingTime" SG_ 607 ATS_RRStTltDnBtn 5000;
BA_ "Version" SG_ 607 ATS_RRStTltDnBtn "19.09.02";
BA_ "Description" SG_ 607 ATS_RRStLegRestPopBtn "Rear Right Leg Rest Move Pop Up Button";
BA_ "GenSigSendType" SG_ 607 ATS_RRStLegRestPopBtn 4;
BA_ "UserSigValidity" SG_ 607 ATS_RRStLegRestPopBtn 3;
BA_ "NetworkRequest" SG_ 607 ATS_RRStLegRestPopBtn 0;
BA_ "NetworkRequestHoldingTime" SG_ 607 ATS_RRStLegRestPopBtn 5000;
BA_ "Version" SG_ 607 ATS_RRStLegRestPopBtn "20.07.01";
BA_ "Description" SG_ 607 ATS_RRStFRestPopBtn "Rear Right Foot Rest Move Pop Up Button";
BA_ "GenSigSendType" SG_ 607 ATS_RRStFRestPopBtn 4;
BA_ "UserSigValidity" SG_ 607 ATS_RRStFRestPopBtn 3;
BA_ "NetworkRequest" SG_ 607 ATS_RRStFRestPopBtn 0;
BA_ "NetworkRequestHoldingTime" SG_ 607 ATS_RRStFRestPopBtn 5000;
BA_ "Version" SG_ 607 ATS_RRStFRestPopBtn "20.07.01";
BA_ "Description" SG_ 607 ATS_RRStAstPopBtn "Rear Right Assist Seat Move Pop Up Button";
BA_ "GenSigSendType" SG_ 607 ATS_RRStAstPopBtn 4;
BA_ "UserSigValidity" SG_ 607 ATS_RRStAstPopBtn 3;
BA_ "NetworkRequest" SG_ 607 ATS_RRStAstPopBtn 0;
BA_ "NetworkRequestHoldingTime" SG_ 607 ATS_RRStAstPopBtn 5000;
BA_ "Version" SG_ 607 ATS_RRStAstPopBtn "20.07.01";
BA_ "Description" SG_ 607 ATS_RRFauCondiBtn "Rear Right FAU Operational Condition Move Button";
BA_ "GenSigSendType" SG_ 607 ATS_RRFauCondiBtn 4;
BA_ "UserSigValidity" SG_ 607 ATS_RRFauCondiBtn 3;
BA_ "NetworkRequest" SG_ 607 ATS_RRFauCondiBtn 0;
BA_ "NetworkRequestHoldingTime" SG_ 607 ATS_RRFauCondiBtn 5000;
BA_ "Version" SG_ 607 ATS_RRFauCondiBtn "20.07.01";
BA_ "Description" SG_ 607 ATS_RRStHRestUpBtn "ÈÄ¼® RH Çìµå·¹½ºÆ® ¾÷ ÀÌµ¿";
BA_ "GenSigSendType" SG_ 607 ATS_RRStHRestUpBtn 4;
BA_ "UserSigValidity" SG_ 607 ATS_RRStHRestUpBtn 3;
BA_ "NetworkRequest" SG_ 607 ATS_RRStHRestUpBtn 0;
BA_ "NetworkRequestHoldingTime" SG_ 607 ATS_RRStHRestUpBtn 5000;
BA_ "Version" SG_ 607 ATS_RRStHRestUpBtn "19.09.02";
BA_ "Description" SG_ 607 ATS_RRStHRestDnBtn "ÈÄ¼® RH Çìµå·¹½ºÆ® ´Ù¿î ÀÌµ¿";
BA_ "GenSigSendType" SG_ 607 ATS_RRStHRestDnBtn 4;
BA_ "UserSigValidity" SG_ 607 ATS_RRStHRestDnBtn 3;
BA_ "NetworkRequest" SG_ 607 ATS_RRStHRestDnBtn 0;
BA_ "NetworkRequestHoldingTime" SG_ 607 ATS_RRStHRestDnBtn 5000;
BA_ "Version" SG_ 607 ATS_RRStHRestDnBtn "19.09.02";
BA_ "Description" SG_ 607 ATS_RRStHRestFwdBtn "ÈÄ¼® RH Çìµå·¹½ºÆ® Àü¹æ ÀÌµ¿";
BA_ "GenSigSendType" SG_ 607 ATS_RRStHRestFwdBtn 4;
BA_ "UserSigValidity" SG_ 607 ATS_RRStHRestFwdBtn 3;
BA_ "NetworkRequest" SG_ 607 ATS_RRStHRestFwdBtn 0;
BA_ "NetworkRequestHoldingTime" SG_ 607 ATS_RRStHRestFwdBtn 5000;
BA_ "Version" SG_ 607 ATS_RRStHRestFwdBtn "19.09.02";
BA_ "Description" SG_ 607 ATS_RRStHRestBwdBtn "ÈÄ¼® RH Çìµå·¹½ºÆ® ÈÄ¹æ ÀÌµ¿";
BA_ "GenSigSendType" SG_ 607 ATS_RRStHRestBwdBtn 4;
BA_ "UserSigValidity" SG_ 607 ATS_RRStHRestBwdBtn 3;
BA_ "NetworkRequest" SG_ 607 ATS_RRStHRestBwdBtn 0;
BA_ "NetworkRequestHoldingTime" SG_ 607 ATS_RRStHRestBwdBtn 5000;
BA_ "Version" SG_ 607 ATS_RRStHRestBwdBtn "19.09.02";
BA_ "Description" SG_ 607 ATS_RRStShoulderADJFwdBtn "ÈÄ¼® RH ¼ñ´õ¾îÁ®½ºÅÍ FWD ÀÌµ¿";
BA_ "GenSigSendType" SG_ 607 ATS_RRStShoulderADJFwdBtn 4;
BA_ "UserSigValidity" SG_ 607 ATS_RRStShoulderADJFwdBtn 3;
BA_ "NetworkRequest" SG_ 607 ATS_RRStShoulderADJFwdBtn 0;
BA_ "NetworkRequestHoldingTime" SG_ 607 ATS_RRStShoulderADJFwdBtn 5000;
BA_ "Version" SG_ 607 ATS_RRStShoulderADJFwdBtn "20.03.02";
BA_ "Description" SG_ 607 ATS_RRStShoulderADJBwdBtn "ÈÄ¼® RH ¼ñ´õ¾îÁ®½ºÅÍ BWD ÀÌµ¿";
BA_ "GenSigSendType" SG_ 607 ATS_RRStShoulderADJBwdBtn 4;
BA_ "UserSigValidity" SG_ 607 ATS_RRStShoulderADJBwdBtn 3;
BA_ "NetworkRequest" SG_ 607 ATS_RRStShoulderADJBwdBtn 0;
BA_ "NetworkRequestHoldingTime" SG_ 607 ATS_RRStShoulderADJBwdBtn 5000;
BA_ "Version" SG_ 607 ATS_RRStShoulderADJBwdBtn "20.03.02";
BA_ "Description" SG_ 607 ATS_RRStLegRestUpBtn "ÈÄ¼® RH ·¹±×·¹½ºÆ® ¾÷ ÀÌµ¿";
BA_ "GenSigSendType" SG_ 607 ATS_RRStLegRestUpBtn 4;
BA_ "UserSigValidity" SG_ 607 ATS_RRStLegRestUpBtn 3;
BA_ "NetworkRequest" SG_ 607 ATS_RRStLegRestUpBtn 0;
BA_ "NetworkRequestHoldingTime" SG_ 607 ATS_RRStLegRestUpBtn 5000;
BA_ "Version" SG_ 607 ATS_RRStLegRestUpBtn "19.09.02";
BA_ "Description" SG_ 607 ATS_RRStLegRestDnBtn "ÈÄ¼® RH ·¹±×·¹½ºÆ® ´Ù¿î ÀÌµ¿";
BA_ "GenSigSendType" SG_ 607 ATS_RRStLegRestDnBtn 4;
BA_ "UserSigValidity" SG_ 607 ATS_RRStLegRestDnBtn 3;
BA_ "NetworkRequest" SG_ 607 ATS_RRStLegRestDnBtn 0;
BA_ "NetworkRequestHoldingTime" SG_ 607 ATS_RRStLegRestDnBtn 5000;
BA_ "Version" SG_ 607 ATS_RRStLegRestDnBtn "19.09.02";
BA_ "Description" SG_ 607 ATS_RRStLegRestExtUpBtn "ÈÄ¼® RH ·¹±×·¹½ºÆ® Àü¹æ ÀÍ½ºÅÙ¼Ç ÀÌµ¿";
BA_ "GenSigSendType" SG_ 607 ATS_RRStLegRestExtUpBtn 4;
BA_ "UserSigValidity" SG_ 607 ATS_RRStLegRestExtUpBtn 3;
BA_ "NetworkRequest" SG_ 607 ATS_RRStLegRestExtUpBtn 0;
BA_ "NetworkRequestHoldingTime" SG_ 607 ATS_RRStLegRestExtUpBtn 5000;
BA_ "Version" SG_ 607 ATS_RRStLegRestExtUpBtn "19.09.02";
BA_ "Description" SG_ 607 ATS_RRStLegRestExtDnBtn "ÈÄ¼® RH ·¹±×·¹½ºÆ® ÈÄ¹æ ÀÍ½ºÅÙ¼Ç ÀÌµ¿";
BA_ "GenSigSendType" SG_ 607 ATS_RRStLegRestExtDnBtn 4;
BA_ "UserSigValidity" SG_ 607 ATS_RRStLegRestExtDnBtn 3;
BA_ "NetworkRequest" SG_ 607 ATS_RRStLegRestExtDnBtn 0;
BA_ "NetworkRequestHoldingTime" SG_ 607 ATS_RRStLegRestExtDnBtn 5000;
BA_ "Version" SG_ 607 ATS_RRStLegRestExtDnBtn "19.09.02";
BA_ "GenMsgCycleTime" BO_ 1216 0;
BA_ "Description" SG_ 1216 BCM_Crc1Val "The data area for CRC calculation is based on the data length (DLC) of the message DB.

The CRC shall be calculated over the entire data block (excluding the CRC bytes) including the user data, alive counter and Data ID 

 

- CRC Polynomial (0x1D) , Initial Value : 0x00, XOR value : 0xFF, Data ID Mode : Both, Data ID : Message ID + 0xF800 

- The initial value is for CRC calculation and the message should be sent with the calculated result value. 

The mathematical expression to 8 bit CRC polynomial is given here. G(x) = x8 + x4 + x3 + x2 + 1";
BA_ "GenSigSendType" SG_ 1216 BCM_Crc1Val 4;
BA_ "GenSigStartValue" SG_ 1216 BCM_Crc1Val 255;
BA_ "UserSigValidity" SG_ 1216 BCM_Crc1Val 0;
BA_ "Version" SG_ 1216 BCM_Crc1Val "18.11.08";
BA_ "Description" SG_ 1216 BCM_AlvCnt1Val "For the first transmission request for a data element the counter shall be initialized with 0 and shall be incremented by 1

for every subsequent send request. When the counter reaches the maximum value(0xE), then it shall restart with 0 for the next send request";
BA_ "GenSigSendType" SG_ 1216 BCM_AlvCnt1Val 4;
BA_ "UserSigValidity" SG_ 1216 BCM_AlvCnt1Val 0;
BA_ "Version" SG_ 1216 BCM_AlvCnt1Val "18.11.08";
BA_ "Description" SG_ 1216 PHEV_FuelDrReleaseSwSta "- Fuel Filler Door Release SW";
BA_ "GenSigSendType" SG_ 1216 PHEV_FuelDrReleaseSwSta 4;
BA_ "UserSigValidity" SG_ 1216 PHEV_FuelDrReleaseSwSta 0;
BA_ "NetworkRequest" SG_ 1216 PHEV_FuelDrReleaseSwSta 0;
BA_ "NetworkRequestHoldingTime" SG_ 1216 PHEV_FuelDrReleaseSwSta 5000;
BA_ "Version" SG_ 1216 PHEV_FuelDrReleaseSwSta "17.12.00";
BA_ "Description" SG_ 1216 StrWhlWrmr_MKBDBpReq "Steering Wheel Warmer Switch Beep Command";
BA_ "GenSigSendType" SG_ 1216 StrWhlWrmr_MKBDBpReq 4;
BA_ "UserSigValidity" SG_ 1216 StrWhlWrmr_MKBDBpReq 0;
BA_ "NetworkRequest" SG_ 1216 StrWhlWrmr_MKBDBpReq 0;
BA_ "NetworkRequestHoldingTime" SG_ 1216 StrWhlWrmr_MKBDBpReq 5000;
BA_ "Version" SG_ 1216 StrWhlWrmr_MKBDBpReq "20.08.02";
BA_ "Description" SG_ 1216 BckGls_RrGlsHtdMKBDBpReq "Rear Defogger Switch Beep Request";
BA_ "GenSigSendType" SG_ 1216 BckGls_RrGlsHtdMKBDBpReq 4;
BA_ "UserSigValidity" SG_ 1216 BckGls_RrGlsHtdMKBDBpReq 0;
BA_ "NetworkRequest" SG_ 1216 BckGls_RrGlsHtdMKBDBpReq 0;
BA_ "NetworkRequestHoldingTime" SG_ 1216 BckGls_RrGlsHtdMKBDBpReq 5000;
BA_ "Version" SG_ 1216 BckGls_RrGlsHtdMKBDBpReq "20.08.02";
BA_ "Description" SG_ 1216 Wndshld_FrtGlsHtdMKBDBpReq "Front Heated Glass Switch Beep Request";
BA_ "GenSigSendType" SG_ 1216 Wndshld_FrtGlsHtdMKBDBpReq 4;
BA_ "UserSigValidity" SG_ 1216 Wndshld_FrtGlsHtdMKBDBpReq 0;
BA_ "NetworkRequest" SG_ 1216 Wndshld_FrtGlsHtdMKBDBpReq 0;
BA_ "NetworkRequestHoldingTime" SG_ 1216 Wndshld_FrtGlsHtdMKBDBpReq 5000;
BA_ "Version" SG_ 1216 Wndshld_FrtGlsHtdMKBDBpReq "20.08.02";
BA_ "Description" SG_ 1216 BAlarm_AutoLockrReq "-Lock request by Auto Locking

 (BurglarAlarmFunction)";
BA_ "GenSigSendType" SG_ 1216 BAlarm_AutoLockrReq 4;
BA_ "UserSigValidity" SG_ 1216 BAlarm_AutoLockrReq 0;
BA_ "NetworkRequest" SG_ 1216 BAlarm_AutoLockrReq 0;
BA_ "NetworkRequestHoldingTime" SG_ 1216 BAlarm_AutoLockrReq 5000;
BA_ "Version" SG_ 1216 BAlarm_AutoLockrReq "17.12.00";
BA_ "Description" SG_ 1216 TiltTele_SmrtIMSDBNum "Smart IMS DB Number Information";
BA_ "GenSigSendType" SG_ 1216 TiltTele_SmrtIMSDBNum 4;
BA_ "UserSigValidity" SG_ 1216 TiltTele_SmrtIMSDBNum 0;
BA_REL_ "GenSigTimeoutTime" BU_SG_REL_ SCM SG_ 1216 TiltTele_SmrtIMSDBNum 0;
BA_ "NetworkRequest" SG_ 1216 TiltTele_SmrtIMSDBNum 0;
BA_ "NetworkRequestHoldingTime" SG_ 1216 TiltTele_SmrtIMSDBNum 5000;
BA_ "Version" SG_ 1216 TiltTele_SmrtIMSDBNum "20.08.02";
BA_ "Description" SG_ 1216 Tilt_IMSMemoryCmd "Command for IMS Memory";
BA_ "GenSigSendType" SG_ 1216 Tilt_IMSMemoryCmd 4;
BA_ "UserSigValidity" SG_ 1216 Tilt_IMSMemoryCmd 0;
BA_REL_ "GenSigTimeoutTime" BU_SG_REL_ SCM SG_ 1216 Tilt_IMSMemoryCmd 0;
BA_ "NetworkRequest" SG_ 1216 Tilt_IMSMemoryCmd 0;
BA_ "NetworkRequestHoldingTime" SG_ 1216 Tilt_IMSMemoryCmd 5000;
BA_ "Version" SG_ 1216 Tilt_IMSMemoryCmd "20.08.07";
BA_ "Description" SG_ 1216 Tele_IMSMemoryCmd "Command for IMS Memory";
BA_ "GenSigSendType" SG_ 1216 Tele_IMSMemoryCmd 4;
BA_ "UserSigValidity" SG_ 1216 Tele_IMSMemoryCmd 0;
BA_REL_ "GenSigTimeoutTime" BU_SG_REL_ SCM SG_ 1216 Tele_IMSMemoryCmd 0;
BA_ "NetworkRequest" SG_ 1216 Tele_IMSMemoryCmd 0;
BA_ "NetworkRequestHoldingTime" SG_ 1216 Tele_IMSMemoryCmd 5000;
BA_ "Version" SG_ 1216 Tele_IMSMemoryCmd "20.08.07";
BA_ "GenMsgCycleTime" BO_ 2323816449 0;
BA_ "VFrameFormat" BO_ 2323816449 1;
BA_ "GenSigSendType" SG_ 2323816449 C_CtrlDrLockRlyCCS_Copy_2 4;
BA_ "UserSigValidity" SG_ 2323816449 C_CtrlDrLockRlyCCS_Copy_2 0;
BA_ "NetworkRequest" SG_ 2323816449 C_CtrlDrLockRlyCCS_Copy_2 0;
BA_ "NetworkRequestHoldingTime" SG_ 2323816449 C_CtrlDrLockRlyCCS_Copy_2 2000;
BA_ "Version" SG_ 2323816449 C_CtrlDrLockRlyCCS_Copy_2 "20.08.07";
BA_ "GenSigSendType" SG_ 2323816449 C_TeleHeatingCmdIBOX_Copy_2 4;
BA_ "GenSigStartValue" SG_ 2323816449 C_TeleHeatingCmdIBOX_Copy_2 3;
BA_ "UserSigValidity" SG_ 2323816449 C_TeleHeatingCmdIBOX_Copy_2 0;
BA_ "NetworkRequest" SG_ 2323816449 C_TeleHeatingCmdIBOX_Copy_2 0;
BA_ "NetworkRequestHoldingTime" SG_ 2323816449 C_TeleHeatingCmdIBOX_Copy_2 2000;
BA_ "Version" SG_ 2323816449 C_TeleHeatingCmdIBOX_Copy_2 "20.08.07";
BA_ "GenSigSendType" SG_ 2323816449 C_TeleStrgWhlHeatingCmdIBOX_Copy_2 4;
BA_ "GenSigStartValue" SG_ 2323816449 C_TeleStrgWhlHeatingCmdIBOX_Copy_2 3;
BA_ "UserSigValidity" SG_ 2323816449 C_TeleStrgWhlHeatingCmdIBOX_Copy_2 0;
BA_ "NetworkRequest" SG_ 2323816449 C_TeleStrgWhlHeatingCmdIBOX_Copy_2 0;
BA_ "NetworkRequestHoldingTime" SG_ 2323816449 C_TeleStrgWhlHeatingCmdIBOX_Copy_2 2000;
BA_ "Version" SG_ 2323816449 C_TeleStrgWhlHeatingCmdIBOX_Copy_2 "20.08.07";
BA_ "GenSigSendType" SG_ 2323816449 C_TeleDefoggerHeatingCmdIBOX_Copy_2 4;
BA_ "GenSigStartValue" SG_ 2323816449 C_TeleDefoggerHeatingCmdIBOX_Copy_2 3;
BA_ "UserSigValidity" SG_ 2323816449 C_TeleDefoggerHeatingCmdIBOX_Copy_2 0;
BA_ "NetworkRequest" SG_ 2323816449 C_TeleDefoggerHeatingCmdIBOX_Copy_2 0;
BA_ "NetworkRequestHoldingTime" SG_ 2323816449 C_TeleDefoggerHeatingCmdIBOX_Copy_2 2000;
BA_ "Version" SG_ 2323816449 C_TeleDefoggerHeatingCmdIBOX_Copy_2 "20.08.07";
BA_ "GenSigSendType" SG_ 2323816449 C_TeleDrvSeatOpCmdIBOX_Copy_2 4;
BA_ "UserSigValidity" SG_ 2323816449 C_TeleDrvSeatOpCmdIBOX_Copy_2 3;
BA_REL_ "GenSigTimeoutTime" BU_SG_REL_ SHVU_FR SG_ 2323816449 C_TeleDrvSeatOpCmdIBOX_Copy_2 0;
BA_REL_ "GenSigTimeoutTime" BU_SG_REL_ DPSU SG_ 2323816449 C_TeleDrvSeatOpCmdIBOX_Copy_2 0;
BA_ "Version" SG_ 2323816449 C_TeleDrvSeatOpCmdIBOX_Copy_2 "20.08.07";
BA_ "GenSigSendType" SG_ 2323816449 C_CtrlDrUnlockRlyCCS_Copy_2 4;
BA_ "UserSigValidity" SG_ 2323816449 C_CtrlDrUnlockRlyCCS_Copy_2 0;
BA_ "NetworkRequest" SG_ 2323816449 C_CtrlDrUnlockRlyCCS_Copy_2 0;
BA_ "NetworkRequestHoldingTime" SG_ 2323816449 C_CtrlDrUnlockRlyCCS_Copy_2 2000;
BA_ "Version" SG_ 2323816449 C_CtrlDrUnlockRlyCCS_Copy_2 "20.08.07";
BA_ "GenSigSendType" SG_ 2323816449 C_TeleAstSeatOpCmdIBOX_Copy_2 4;
BA_ "UserSigValidity" SG_ 2323816449 C_TeleAstSeatOpCmdIBOX_Copy_2 3;
BA_REL_ "GenSigTimeoutTime" BU_SG_REL_ APSU SG_ 2323816449 C_TeleAstSeatOpCmdIBOX_Copy_2 0;
BA_REL_ "GenSigTimeoutTime" BU_SG_REL_ SHVU_FR SG_ 2323816449 C_TeleAstSeatOpCmdIBOX_Copy_2 0;
BA_ "Version" SG_ 2323816449 C_TeleAstSeatOpCmdIBOX_Copy_2 "20.08.07";
BA_ "GenSigSendType" SG_ 2323816449 C_TeleRRSeatOpCmdIBOX_Copy_2 4;
BA_ "UserSigValidity" SG_ 2323816449 C_TeleRRSeatOpCmdIBOX_Copy_2 3;
BA_REL_ "GenSigTimeoutTime" BU_SG_REL_ RRHV SG_ 2323816449 C_TeleRRSeatOpCmdIBOX_Copy_2 0;
BA_REL_ "GenSigTimeoutTime" BU_SG_REL_ SHVU_FR SG_ 2323816449 C_TeleRRSeatOpCmdIBOX_Copy_2 0;
BA_REL_ "GenSigTimeoutTime" BU_SG_REL_ SHVU_RR SG_ 2323816449 C_TeleRRSeatOpCmdIBOX_Copy_2 0;
BA_REL_ "GenSigTimeoutTime" BU_SG_REL_ RRPSU SG_ 2323816449 C_TeleRRSeatOpCmdIBOX_Copy_2 0;
BA_REL_ "GenSigTimeoutTime" BU_SG_REL_ RLPSU SG_ 2323816449 C_TeleRRSeatOpCmdIBOX_Copy_2 0;
BA_REL_ "GenSigTimeoutTime" BU_SG_REL_ ATS SG_ 2323816449 C_TeleRRSeatOpCmdIBOX_Copy_2 0;
BA_ "Version" SG_ 2323816449 C_TeleRRSeatOpCmdIBOX_Copy_2 "20.08.07";
BA_ "GenSigSendType" SG_ 2323816449 C_TeleRLSeatOpCmdIBOX_Copy_1 4;
BA_ "UserSigValidity" SG_ 2323816449 C_TeleRLSeatOpCmdIBOX_Copy_1 3;
BA_REL_ "GenSigTimeoutTime" BU_SG_REL_ RLHV SG_ 2323816449 C_TeleRLSeatOpCmdIBOX_Copy_1 0;
BA_REL_ "GenSigTimeoutTime" BU_SG_REL_ SHVU_FR SG_ 2323816449 C_TeleRLSeatOpCmdIBOX_Copy_1 0;
BA_REL_ "GenSigTimeoutTime" BU_SG_REL_ SHVU_RR SG_ 2323816449 C_TeleRLSeatOpCmdIBOX_Copy_1 0;
BA_REL_ "GenSigTimeoutTime" BU_SG_REL_ RRPSU SG_ 2323816449 C_TeleRLSeatOpCmdIBOX_Copy_1 0;
BA_REL_ "GenSigTimeoutTime" BU_SG_REL_ RLPSU SG_ 2323816449 C_TeleRLSeatOpCmdIBOX_Copy_1 0;
BA_REL_ "GenSigTimeoutTime" BU_SG_REL_ ATS SG_ 2323816449 C_TeleRLSeatOpCmdIBOX_Copy_1 0;
BA_ "Version" SG_ 2323816449 C_TeleRLSeatOpCmdIBOX_Copy_1 "20.08.07";
BA_ "GenSigSendType" SG_ 2323816449 C_BlindCmdAVN_Copy_2 4;
BA_ "GenSigStartValue" SG_ 2323816449 C_BlindCmdAVN_Copy_2 7;
BA_ "UserSigValidity" SG_ 2323816449 C_BlindCmdAVN_Copy_2 1;
BA_ "Version" SG_ 2323816449 C_BlindCmdAVN_Copy_2 "20.08.07";
BA_ "GenSigSendType" SG_ 2323816449 C_GlassCmdAVN_Copy_2 4;
BA_ "GenSigStartValue" SG_ 2323816449 C_GlassCmdAVN_Copy_2 7;
BA_ "UserSigValidity" SG_ 2323816449 C_GlassCmdAVN_Copy_2 1;
BA_ "Version" SG_ 2323816449 C_GlassCmdAVN_Copy_2 "20.08.07";
BA_ "GenSigSendType" SG_ 2323816449 C_DrvWindowCmdAVN_Copy_2 4;
BA_ "GenSigStartValue" SG_ 2323816449 C_DrvWindowCmdAVN_Copy_2 15;
BA_ "UserSigValidity" SG_ 2323816449 C_DrvWindowCmdAVN_Copy_2 0;
BA_ "Version" SG_ 2323816449 C_DrvWindowCmdAVN_Copy_2 "20.08.07";
BA_ "GenSigSendType" SG_ 2323816449 C_HazardFromCCS_Copy_2 4;
BA_ "UserSigValidity" SG_ 2323816449 C_HazardFromCCS_Copy_2 0;
BA_ "NetworkRequest" SG_ 2323816449 C_HazardFromCCS_Copy_2 0;
BA_ "NetworkRequestHoldingTime" SG_ 2323816449 C_HazardFromCCS_Copy_2 2000;
BA_ "Version" SG_ 2323816449 C_HazardFromCCS_Copy_2 "20.08.07";
BA_ "GenSigSendType" SG_ 2323816449 C_AstWindowCmdAVN_Copy_2 4;
BA_ "GenSigStartValue" SG_ 2323816449 C_AstWindowCmdAVN_Copy_2 15;
BA_ "UserSigValidity" SG_ 2323816449 C_AstWindowCmdAVN_Copy_2 0;
BA_ "Version" SG_ 2323816449 C_AstWindowCmdAVN_Copy_2 "20.08.07";
BA_ "GenSigSendType" SG_ 2323816449 C_RRWindowCmdAVN_Copy_2 4;
BA_ "GenSigStartValue" SG_ 2323816449 C_RRWindowCmdAVN_Copy_2 15;
BA_ "UserSigValidity" SG_ 2323816449 C_RRWindowCmdAVN_Copy_2 0;
BA_ "Version" SG_ 2323816449 C_RRWindowCmdAVN_Copy_2 "20.08.07";
BA_ "GenSigSendType" SG_ 2323816449 C_RLWindowCmdAVN_Copy_2 4;
BA_ "GenSigStartValue" SG_ 2323816449 C_RLWindowCmdAVN_Copy_2 15;
BA_ "UserSigValidity" SG_ 2323816449 C_RLWindowCmdAVN_Copy_2 0;
BA_ "Version" SG_ 2323816449 C_RLWindowCmdAVN_Copy_2 "20.08.07";
BA_ "Description" SG_ 2323816449 TailCtrlReq_Copy "This signal is for cotroling Tail lamp.";
BA_ "GenSigSendType" SG_ 2323816449 TailCtrlReq_Copy 4;
BA_ "UserSigValidity" SG_ 2323816449 TailCtrlReq_Copy 0;
BA_ "Version" SG_ 2323816449 TailCtrlReq_Copy "20.08.07";
BA_ "Description" SG_ 2323816449 HazardCtrlReq_Copy "This signal is request for controling Hazard lamp.";
BA_ "GenSigSendType" SG_ 2323816449 HazardCtrlReq_Copy 4;
BA_ "UserSigValidity" SG_ 2323816449 HazardCtrlReq_Copy 0;
BA_ "Version" SG_ 2323816449 HazardCtrlReq_Copy "20.08.07";
BA_ "GenSigSendType" SG_ 2323816449 HU_DATC_AirCleaningSet_Copy_1 4;
BA_ "GenSigStartValue" SG_ 2323816449 HU_DATC_AirCleaningSet_Copy_1 3;
BA_ "UserSigValidity" SG_ 2323816449 HU_DATC_AirCleaningSet_Copy_1 3;
BA_ "Version" SG_ 2323816449 HU_DATC_AirCleaningSet_Copy_1 "20.08.07";
BA_ "GenSigSendType" SG_ 2323816449 C_PanicFromCCS_Copy_2 4;
BA_ "UserSigValidity" SG_ 2323816449 C_PanicFromCCS_Copy_2 0;
BA_ "NetworkRequest" SG_ 2323816449 C_PanicFromCCS_Copy_2 0;
BA_ "NetworkRequestHoldingTime" SG_ 2323816449 C_PanicFromCCS_Copy_2 2000;
BA_ "Version" SG_ 2323816449 C_PanicFromCCS_Copy_2 "20.08.07";
BA_ "Description" SG_ 2323816449 C_TeleFrontHeatingCmdIBOX_Copy_1 "Command for Remote Heating (Front Window)";
BA_ "GenSigSendType" SG_ 2323816449 C_TeleFrontHeatingCmdIBOX_Copy_1 4;
BA_ "GenSigStartValue" SG_ 2323816449 C_TeleFrontHeatingCmdIBOX_Copy_1 3;
BA_ "UserSigValidity" SG_ 2323816449 C_TeleFrontHeatingCmdIBOX_Copy_1 0;
BA_ "NetworkRequest" SG_ 2323816449 C_TeleFrontHeatingCmdIBOX_Copy_1 0;
BA_ "NetworkRequestHoldingTime" SG_ 2323816449 C_TeleFrontHeatingCmdIBOX_Copy_1 2000;
BA_ "Version" SG_ 2323816449 C_TeleFrontHeatingCmdIBOX_Copy_1 "20.08.07";
BA_ "Description" SG_ 2323816449 RAC_AirCleaningCtrlReq_Copy_1 "CCS Module(Telematics unit) transmits this signal to control the air cleaning when the remote air-condition is request.";
BA_ "GenSigSendType" SG_ 2323816449 RAC_AirCleaningCtrlReq_Copy_1 4;
BA_ "UserSigValidity" SG_ 2323816449 RAC_AirCleaningCtrlReq_Copy_1 3;
BA_ "Version" SG_ 2323816449 RAC_AirCleaningCtrlReq_Copy_1 "20.09.00";
BA_ "GenSigSendType" SG_ 2323816449 C_PreCrankReq_Copy 4;
BA_ "UserSigValidity" SG_ 2323816449 C_PreCrankReq_Copy 0;
BA_ "NetworkRequest" SG_ 2323816449 C_PreCrankReq_Copy 0;
BA_ "Version" SG_ 2323816449 C_PreCrankReq_Copy "20.08.07";
BA_ "GenMsgCycleTime" BO_ 2323816450 0;
BA_ "VFrameFormat" BO_ 2323816450 1;
BA_ "Description" SG_ 2323816450 HU_CDMOpenCmd_Copy_1 "Command for CDM open/close";
BA_ "GenSigSendType" SG_ 2323816450 HU_CDMOpenCmd_Copy_1 4;
BA_ "UserSigValidity" SG_ 2323816450 HU_CDMOpenCmd_Copy_1 7;
BA_ "Version" SG_ 2323816450 HU_CDMOpenCmd_Copy_1 "20.09.00";
BA_ "Description" SG_ 2323816450 HU_StrgWhlHeatingSet_CCS_Copy "steering wheel heating control by step1/2";
BA_ "GenSigSendType" SG_ 2323816450 HU_StrgWhlHeatingSet_CCS_Copy 4;
BA_ "GenSigStartValue" SG_ 2323816450 HU_StrgWhlHeatingSet_CCS_Copy 7;
BA_ "UserSigValidity" SG_ 2323816450 HU_StrgWhlHeatingSet_CCS_Copy 0;
BA_ "Version" SG_ 2323816450 HU_StrgWhlHeatingSet_CCS_Copy "21.05.02";
BA_ "GenSigSendType" SG_ 2323816450 C_EsyAcsProfileID_CCU 4;
BA_ "UserSigValidity" SG_ 2323816450 C_EsyAcsProfileID_CCU 0;
BA_REL_ "GenSigTimeoutTime" BU_SG_REL_ DPSU SG_ 2323816450 C_EsyAcsProfileID_CCU 0;
BA_ "Version" SG_ 2323816450 C_EsyAcsProfileID_CCU "20.09.00";
BA_ "GenMsgCycleTime" BO_ 2323816451 0;
BA_ "VFrameFormat" BO_ 2323816451 1;
BA_ "GenMsgCycleTime" BO_ 2323816452 0;
BA_ "VFrameFormat" BO_ 2323816452 1;
BA_ "GenMsgSendType" BO_ 679 0;
BA_ "Description" SG_ 679 CMS_RH_Crc1Val "The data area for CRC calculation is based on the data length (DLC) of the message DB.

The CRC shall be calculated over the entire data block (excluding the CRC bytes) including the user data, alive counter and Data ID 

 

- CRC Polynomial (0x1D) , Initial Value : 0x00, XOR value : 0xFF, Data ID Mode : Both, Data ID : Message ID + 0xF800 

- The initial value is for CRC calculation and the message should be sent with the calculated result value. 

The mathematical expression to 8 bit CRC polynomial is given here. G(x) = x8 + x4 + x3 + x2 + 1";
BA_ "GenSigSendType" SG_ 679 CMS_RH_Crc1Val 4;
BA_ "GenSigStartValue" SG_ 679 CMS_RH_Crc1Val 255;
BA_ "UserSigValidity" SG_ 679 CMS_RH_Crc1Val 0;
BA_ "RoutingFactor" SG_ 679 CMS_RH_Crc1Val 0;
BA_ "Version" SG_ 679 CMS_RH_Crc1Val "19.09.06";
BA_ "Description" SG_ 679 CMS_RH_AlvCnt1Val "For the first transmission request for a data element the counter shall be initialized with 0 and shall be incremented by 1

for every subsequent send request. When the counter reaches the maximum value(0xE), then it shall restart with 0 for the next send request";
BA_ "GenSigSendType" SG_ 679 CMS_RH_AlvCnt1Val 4;
BA_ "UserSigValidity" SG_ 679 CMS_RH_AlvCnt1Val 0;
BA_ "RoutingFactor" SG_ 679 CMS_RH_AlvCnt1Val 0;
BA_ "Version" SG_ 679 CMS_RH_AlvCnt1Val "19.09.06";
BA_ "GenSigSendType" SG_ 679 USM_CMSDayBrgtnsLvlRHSta 4;
BA_ "GenSigStartValue" SG_ 679 USM_CMSDayBrgtnsLvlRHSta 5;
BA_ "UserSigValidity" SG_ 679 USM_CMSDayBrgtnsLvlRHSta 0;
BA_ "NetworkRequest" SG_ 679 USM_CMSDayBrgtnsLvlRHSta 0;
BA_ "NetworkRequestHoldingTime" SG_ 679 USM_CMSDayBrgtnsLvlRHSta 5;
BA_ "RoutingFactor" SG_ 679 USM_CMSDayBrgtnsLvlRHSta 0;
BA_ "Version" SG_ 679 USM_CMSDayBrgtnsLvlRHSta "19.12.00";
BA_ "GenSigSendType" SG_ 679 USM_CMSNgtBrgtnsLvlRHSta 4;
BA_ "GenSigStartValue" SG_ 679 USM_CMSNgtBrgtnsLvlRHSta 5;
BA_ "UserSigValidity" SG_ 679 USM_CMSNgtBrgtnsLvlRHSta 0;
BA_ "NetworkRequest" SG_ 679 USM_CMSNgtBrgtnsLvlRHSta 0;
BA_ "NetworkRequestHoldingTime" SG_ 679 USM_CMSNgtBrgtnsLvlRHSta 5;
BA_ "RoutingFactor" SG_ 679 USM_CMSNgtBrgtnsLvlRHSta 0;
BA_ "Version" SG_ 679 USM_CMSNgtBrgtnsLvlRHSta "19.12.00";
BA_ "GenSigSendType" SG_ 679 IMS_CMSPlayBackSta_RH 4;
BA_ "UserSigValidity" SG_ 679 IMS_CMSPlayBackSta_RH 0;
BA_REL_ "GenSigTimeoutTime" BU_SG_REL_ DPSU SG_ 679 IMS_CMSPlayBackSta_RH 1500;
BA_ "NetworkRequest" SG_ 679 IMS_CMSPlayBackSta_RH 0;
BA_ "NetworkRequestHoldingTime" SG_ 679 IMS_CMSPlayBackSta_RH 5;
BA_ "RoutingFactor" SG_ 679 IMS_CMSPlayBackSta_RH 0;
BA_ "Version" SG_ 679 IMS_CMSPlayBackSta_RH "20.08.07";
BA_ "GenSigSendType" SG_ 679 MonitorStatus 4;
BA_ "UserSigValidity" SG_ 679 MonitorStatus 0;
BA_ "NetworkRequest" SG_ 679 MonitorStatus 0;
BA_ "NetworkRequestHoldingTime" SG_ 679 MonitorStatus 5;
BA_ "RoutingFactor" SG_ 679 MonitorStatus 0;
BA_ "Version" SG_ 679 MonitorStatus "20.04.06";
BA_ "GenSigSendType" SG_ 679 CMS_RH_FoldingSta 4;
BA_ "UserSigValidity" SG_ 679 CMS_RH_FoldingSta 0;
BA_ "NetworkRequest" SG_ 679 CMS_RH_FoldingSta 0;
BA_ "NetworkRequestHoldingTime" SG_ 679 CMS_RH_FoldingSta 5000;
BA_ "RoutingFactor" SG_ 679 CMS_RH_FoldingSta 0;
BA_ "Version" SG_ 679 CMS_RH_FoldingSta "20.11.04";
BA_ "GenSigSendType" SG_ 679 CMS_RH_UnfoldingSta 4;
BA_ "UserSigValidity" SG_ 679 CMS_RH_UnfoldingSta 0;
BA_ "NetworkRequest" SG_ 679 CMS_RH_UnfoldingSta 0;
BA_ "NetworkRequestHoldingTime" SG_ 679 CMS_RH_UnfoldingSta 5000;
BA_ "RoutingFactor" SG_ 679 CMS_RH_UnfoldingSta 0;
BA_ "Version" SG_ 679 CMS_RH_UnfoldingSta "20.11.04";
BA_ "Description" SG_ 679 CMS_RHVerPosVal "This signal indicates RH Outside Mirror Vertical Position Sensor Voltage";
BA_ "GenSigSendType" SG_ 679 CMS_RHVerPosVal 4;
BA_ "UserSigValidity" SG_ 679 CMS_RHVerPosVal 0;
BA_ "NetworkRequest" SG_ 679 CMS_RHVerPosVal 0;
BA_ "NetworkRequestHoldingTime" SG_ 679 CMS_RHVerPosVal 5000;
BA_ "RoutingFactor" SG_ 679 CMS_RHVerPosVal 0;
BA_ "Version" SG_ 679 CMS_RHVerPosVal "20.08.07";
BA_ "Description" SG_ 679 CMS_RHHorPosVal "This signal indicates RH Outside Mirror Horizontal Position Sensor Voltage";
BA_ "GenSigSendType" SG_ 679 CMS_RHHorPosVal 4;
BA_ "UserSigValidity" SG_ 679 CMS_RHHorPosVal 0;
BA_ "NetworkRequest" SG_ 679 CMS_RHHorPosVal 0;
BA_ "NetworkRequestHoldingTime" SG_ 679 CMS_RHHorPosVal 5000;
BA_ "RoutingFactor" SG_ 679 CMS_RHHorPosVal 0;
BA_ "Version" SG_ 679 CMS_RHHorPosVal "20.08.07";
BA_ "GenMsgSendType" BO_ 2382594049 0;
BA_ "VFrameFormat" BO_ 2382594049 1;
BA_ "Description" SG_ 2382594049 DATC_Crc3Val "The data area for CRC calculation is based on the data length (DLC) of the message DB.

The CRC shall be calculated over the entire data block (excluding the CRC bytes) including the user data, alive counter and Data ID

 

- CRC Polynomial (0x1021) , Initial Value : 0xFFFF, XOR value : 0x0000, Data ID : Message ID + 0xF800 

- The initial value is for CRC calculation and the message should be sent with the calculated result value. 

- The mathematical expression to 16 bit CRC polynomial is given here. G(x) = x16 + x12 + x5 + 1";
BA_ "GenSigSendType" SG_ 2382594049 DATC_Crc3Val 4;
BA_ "GenSigStartValue" SG_ 2382594049 DATC_Crc3Val 65535;
BA_ "UserSigValidity" SG_ 2382594049 DATC_Crc3Val 3;
BA_ "Version" SG_ 2382594049 DATC_Crc3Val "18.11.08";
BA_ "Description" SG_ 2382594049 DATC_AlvCnt3Val "For the first transmission request for a data element the counter shall be initialized with 0 and shall be incremented by 1 for every subsequent send request. 

When the counter reaches the maximum value(0xFF), then it shall restart with 0 for the next send request";
BA_ "GenSigSendType" SG_ 2382594049 DATC_AlvCnt3Val 4;
BA_ "UserSigValidity" SG_ 2382594049 DATC_AlvCnt3Val 3;
BA_ "Version" SG_ 2382594049 DATC_AlvCnt3Val "18.11.08";
BA_ "Description" SG_ 2382594049 DATC_DrvTempCDis "This signal indicates setting temperature (¡É) of Driver Side.";
BA_ "GenSigSendType" SG_ 2382594049 DATC_DrvTempCDis 4;
BA_ "UserSigValidity" SG_ 2382594049 DATC_DrvTempCDis 6;
BA_REL_ "GenSigTimeoutTime" BU_SG_REL_ ATS SG_ 2382594049 DATC_DrvTempCDis 1500;
BA_ "Version" SG_ 2382594049 DATC_DrvTempCDis "18.05.01";
BA_ "Description" SG_ 2382594049 DATC_DrvTempFDis "This signal indicates setting temperature (¢µ) of Driver Side.";
BA_ "GenSigSendType" SG_ 2382594049 DATC_DrvTempFDis 4;
BA_ "UserSigValidity" SG_ 2382594049 DATC_DrvTempFDis 6;
BA_REL_ "GenSigTimeoutTime" BU_SG_REL_ ATS SG_ 2382594049 DATC_DrvTempFDis 1500;
BA_ "Version" SG_ 2382594049 DATC_DrvTempFDis "18.05.01";
BA_ "Description" SG_ 2382594049 DATC_PassTempCDis "This signal indicates setting temperature (¡É) of Passenger Side.";
BA_ "GenSigSendType" SG_ 2382594049 DATC_PassTempCDis 4;
BA_ "UserSigValidity" SG_ 2382594049 DATC_PassTempCDis 6;
BA_REL_ "GenSigTimeoutTime" BU_SG_REL_ ATS SG_ 2382594049 DATC_PassTempCDis 1500;
BA_ "Version" SG_ 2382594049 DATC_PassTempCDis "18.05.01";
BA_ "Description" SG_ 2382594049 DATC_PassTempFDis "This signal indicates setting temperature (¢µ) of Passenger Side.";
BA_ "GenSigSendType" SG_ 2382594049 DATC_PassTempFDis 4;
BA_ "UserSigValidity" SG_ 2382594049 DATC_PassTempFDis 6;
BA_REL_ "GenSigTimeoutTime" BU_SG_REL_ ATS SG_ 2382594049 DATC_PassTempFDis 1500;
BA_ "Version" SG_ 2382594049 DATC_PassTempFDis "18.05.01";
BA_ "Description" SG_ 2382594049 DATC_TempDispSta "This signal is an information display of the set temperature range of DATC.";
BA_ "GenSigSendType" SG_ 2382594049 DATC_TempDispSta 4;
BA_ "UserSigValidity" SG_ 2382594049 DATC_TempDispSta 7;
BA_ "Version" SG_ 2382594049 DATC_TempDispSta "17.11.00";
BA_ "Description" SG_ 2382594049 DATC_PreEngOnReq2 "Pre Engine On Request";
BA_ "GenSigSendType" SG_ 2382594049 DATC_PreEngOnReq2 4;
BA_ "UserSigValidity" SG_ 2382594049 DATC_PreEngOnReq2 4;
BA_ "Version" SG_ 2382594049 DATC_PreEngOnReq2 "20.04.03";
BA_ "GenMsgSendType" BO_ 687 0;
BA_ "GenMsgCycleTime" BO_ 687 100;
BA_ "GenMsgCycleTimeFast" BO_ 687 0;
BA_ "GenMsgNrOfRepetition" BO_ 687 0;
BA_ "Description" SG_ 687 HOD_Crc1Val "The data area for CRC calculation is based on the data length (DLC) of the message DB.

The CRC shall be calculated over the entire data block (excluding the CRC bytes) including the user data, alive counter and Data ID 

 

- CRC Polynomial (0x1D) , Initial Value : 0x00, XOR value : 0xFF, Data ID Mode : Both, Data ID : Message ID + 0xF800 

- The initial value is for CRC calculation and the message should be sent with the calculated result value. 

The mathematical expression to 8 bit CRC polynomial is given here. G(x) = x8 + x4 + x3 + x2 + 1";
BA_ "GenSigStartValue" SG_ 687 HOD_Crc1Val 255;
BA_ "UserSigValidity" SG_ 687 HOD_Crc1Val 3;
BA_REL_ "GenSigTimeoutTime" BU_SG_REL_ CGW_CCU SG_ 687 HOD_Crc1Val 1500;
BA_ "Version" SG_ 687 HOD_Crc1Val "19.08.08";
BA_ "Description" SG_ 687 HOD_AlvCnt1Val "For the first transmission request for a data element the counter shall be initialized with 0 and shall be incremented by 1

for every subsequent send request. When the counter reaches the maximum value(0xE), then it shall restart with 0 for the next send request";
BA_ "UserSigValidity" SG_ 687 HOD_AlvCnt1Val 3;
BA_REL_ "GenSigTimeoutTime" BU_SG_REL_ CGW_CCU SG_ 687 HOD_AlvCnt1Val 1500;
BA_ "Version" SG_ 687 HOD_AlvCnt1Val "19.08.08";
BA_ "Description" SG_ 687 HOD_Dir_Status "This signal indicates the status of hands on/off";
BA_ "GenSigStartValue" SG_ 687 HOD_Dir_Status 7;
BA_ "UserSigValidity" SG_ 687 HOD_Dir_Status 3;
BA_REL_ "GenSigTimeoutTime" BU_SG_REL_ CGW_CCU SG_ 687 HOD_Dir_Status 1500;
BA_ "Version" SG_ 687 HOD_Dir_Status "20.01.01";
BA_ "Description" SG_ 687 HOD_Option "This signal is a checkable signal that the HOD is applied.

This signal should be fixed 0x1.";
BA_ "UserSigValidity" SG_ 687 HOD_Option 3;
BA_REL_ "GenSigTimeoutTime" BU_SG_REL_ CGW_CCU SG_ 687 HOD_Option 1500;
BA_ "Version" SG_ 687 HOD_Option "20.01.01";
BA_ "Description" SG_ 687 HOD_CapaCh0 "This signal is a Front Capacitance value(pF)";
BA_ "UserSigValidity" SG_ 687 HOD_CapaCh0 3;
BA_REL_ "GenSigTimeoutTime" BU_SG_REL_ CGW_CCU SG_ 687 HOD_CapaCh0 1500;
BA_ "Version" SG_ 687 HOD_CapaCh0 "21.01.01";
BA_ "Description" SG_ 687 HOD_CapaCh1 "This signal is a Rear Capacitance value(pF)";
BA_ "UserSigValidity" SG_ 687 HOD_CapaCh1 3;
BA_REL_ "GenSigTimeoutTime" BU_SG_REL_ CGW_CCU SG_ 687 HOD_CapaCh1 1500;
BA_ "Version" SG_ 687 HOD_CapaCh1 "21.01.01";
BA_ "GenMsgSendType" BO_ 2176872449 0;
BA_ "GenMsgCycleTime" BO_ 2176872449 50;
BA_ "GenMsgCycleTimeFast" BO_ 2176872449 0;
BA_ "GenMsgNrOfRepetition" BO_ 2176872449 0;
BA_ "VFrameFormat" BO_ 2176872449 1;
BA_ "Description" SG_ 2176872449 HTCU_Crc5Val "The data area for CRC calculation is based on the data length (DLC) of the message DB.

The CRC shall be calculated over the entire data block (excluding the CRC bytes) including the user data, alive counter and Data ID

 

- CRC Polynomial (0x1021) , Initial Value : 0xFFFF, XOR value : 0x0000, Data ID : Message ID + 0xF800 

- The initial value is for CRC calculation and the message should be sent with the calculated result value. 

- The mathematical expression to 16 bit CRC polynomial is given here. G(x) = x16 + x12 + x5 + 1";
BA_ "GenSigStartValue" SG_ 2176872449 HTCU_Crc5Val 65535;
BA_ "UserSigValidity" SG_ 2176872449 HTCU_Crc5Val 3;
BA_ "RoutingFactor" SG_ 2176872449 HTCU_Crc5Val 5;
BA_ "Version" SG_ 2176872449 HTCU_Crc5Val "19.10.00";
BA_ "Description" SG_ 2176872449 HTCU_AlvCnt5Val "For the first transmission request for a data element the counter shall be initialized with 0 and shall be incremented by 1 for every subsequent send request. 

When the counter reaches the maximum value(0xFF), then it shall restart with 0 for the next send request";
BA_ "UserSigValidity" SG_ 2176872449 HTCU_AlvCnt5Val 3;
BA_ "RoutingFactor" SG_ 2176872449 HTCU_AlvCnt5Val 5;
BA_ "Version" SG_ 2176872449 HTCU_AlvCnt5Val "19.10.00";
BA_ "Description" SG_ 2176872449 HDCT_AddtnlTqLssVal "Additional torque loss";
BA_ "UserSigValidity" SG_ 2176872449 HDCT_AddtnlTqLssVal 3;
BA_ "RoutingFactor" SG_ 2176872449 HDCT_AddtnlTqLssVal 5;
BA_ "Version" SG_ 2176872449 HDCT_AddtnlTqLssVal "19.10.01";
BA_ "Description" SG_ 2176872449 HDCT_OBDSta "The signal HDCT_ObdSta is used to inform the OBD master (EMS-ECU) in case a OBD relevant fault is detected. According to the OBD regulations the HTCU could request MIL on, MIL blinking and freeze frame storage. If a freeze frame request by the HTCU has not been acknowledged (CF_Ems_ObdFrfAck) within 2 seconds, this request has to be canceled.

Value description

Bit 0: readiness info / Bit 1: freeze frame request / Bit 2: MIL on request / Bit3: MIL blinking request";
BA_ "UserSigValidity" SG_ 2176872449 HDCT_OBDSta 3;
BA_ "RoutingFactor" SG_ 2176872449 HDCT_OBDSta 5;
BA_ "Version" SG_ 2176872449 HDCT_OBDSta "19.10.01";
BA_ "Description" SG_ 2176872449 HDCT_OBDErrSta "Informs about the presence of an OBD-relevant error in the HTCU.

When an OBD-relevant error detected HDCT_ObdErrSta is set to 1 and the related DTC(s) would be recorded into non-volatile memory. Even if the error is not detected currently, HDCT_ObdErrSta should be set to 1 as long as DTC exists in memory.";
BA_ "UserSigValidity" SG_ 2176872449 HDCT_OBDErrSta 3;
BA_ "RoutingFactor" SG_ 2176872449 HDCT_OBDErrSta 5;
BA_ "Version" SG_ 2176872449 HDCT_OBDErrSta "19.10.01";
BA_ "Description" SG_ 2176872449 HDCT_StcShftLrchCtrl "Static shift DR or RD lurch control";
BA_ "UserSigValidity" SG_ 2176872449 HDCT_StcShftLrchCtrl 3;
BA_ "RoutingFactor" SG_ 2176872449 HDCT_StcShftLrchCtrl 5;
BA_ "Version" SG_ 2176872449 HDCT_StcShftLrchCtrl "19.10.01";
BA_ "Description" SG_ 2176872449 HDCT_EngCltchLmphmMod "Engine clutch limp-home control activation";
BA_ "UserSigValidity" SG_ 2176872449 HDCT_EngCltchLmphmMod 3;
BA_ "RoutingFactor" SG_ 2176872449 HDCT_EngCltchLmphmMod 5;
BA_ "Version" SG_ 2176872449 HDCT_EngCltchLmphmMod "19.10.01";
BA_ "UserSigValidity" SG_ 2176872449 HDCT_CurrPrgrm 3;
BA_ "RoutingFactor" SG_ 2176872449 HDCT_CurrPrgrm 5;
BA_ "Version" SG_ 2176872449 HDCT_CurrPrgrm "19.10.01";
BA_ "Description" SG_ 2176872449 HDCT_FltSta "informs about status of transmission control.



<Value Description>

Bit 0: TCU Diagnostic failure

Bit 1: TCU Diagnostic failure ? Limphome activated

Bit 2: OPU/EOP Diagnostic failure";
BA_ "UserSigValidity" SG_ 2176872449 HDCT_FltSta 3;
BA_ "RoutingFactor" SG_ 2176872449 HDCT_FltSta 5;
BA_ "Version" SG_ 2176872449 HDCT_FltSta "20.02.00";
BA_ "Description" SG_ 2176872449 HDCT_MCUAntJrkInhbt "MCU anti-jerk inhibition";
BA_ "UserSigValidity" SG_ 2176872449 HDCT_MCUAntJrkInhbt 3;
BA_ "RoutingFactor" SG_ 2176872449 HDCT_MCUAntJrkInhbt 5;
BA_ "Version" SG_ 2176872449 HDCT_MCUAntJrkInhbt "19.10.01";
BA_ "Description" SG_ 2176872449 HDCT_TrgtGear "HTCU_TrgtGearSta informs about the speed, which is currently engaged in the gearbox, or, in case of a gear change (HTCU_GearChgSta), which speed is reached.

Note: Gear changes covering more than one speed are also possible.

In the P and N positions, the frictional connection is interrupted hydraulically.

Depending on the type of error, the 3rd or 4th (forward) speed, and the R (reverse) speed are engaged in the limp home program.";
BA_ "UserSigValidity" SG_ 2176872449 HDCT_TrgtGear 3;
BA_ "RoutingFactor" SG_ 2176872449 HDCT_TrgtGear 5;
BA_ "Version" SG_ 2176872449 HDCT_TrgtGear "19.10.01";
BA_ "Description" SG_ 2176872449 HDCT_CurrGear "CUR_GR indicates the gear speed which is currently engaged in the gearbox.";
BA_ "UserSigValidity" SG_ 2176872449 HDCT_CurrGear 3;
BA_ "RoutingFactor" SG_ 2176872449 HDCT_CurrGear 5;
BA_ "Version" SG_ 2176872449 HDCT_CurrGear "19.10.01";
BA_ "Description" SG_ 2176872449 HDCT_GearSelDis "Position (P, R, N..), which was identified by the gear selector.

In case the gear selector is in a intermediate position, the last clear recognized position is used.

There is no specific phase relationship between the output and any other signal.";
BA_ "GenSigStartValue" SG_ 2176872449 HDCT_GearSelDis 9;
BA_ "UserSigValidity" SG_ 2176872449 HDCT_GearSelDis 3;
BA_ "RoutingFactor" SG_ 2176872449 HDCT_GearSelDis 5;
BA_ "Version" SG_ 2176872449 HDCT_GearSelDis "19.10.01";
BA_ "GenMsgSendType" BO_ 2176872450 0;
BA_ "GenMsgCycleTime" BO_ 2176872450 50;
BA_ "GenMsgCycleTimeFast" BO_ 2176872450 0;
BA_ "GenMsgNrOfRepetition" BO_ 2176872450 0;
BA_ "VFrameFormat" BO_ 2176872450 1;
BA_ "Description" SG_ 2176872450 HDCT_TCURdySta "Flag that the HTCU is ready to work. (In fact, this flag is true from the moment that CAN is working. So, normally no ¡°false¡± will be sent on CAN.) This flag does not show that everything is alright in the HTCU. This information is given in the warning and fault flags.";
BA_ "UserSigValidity" SG_ 2176872450 HDCT_TCURdySta 3;
BA_ "RoutingFactor" SG_ 2176872450 HDCT_TCURdySta 5;
BA_ "Version" SG_ 2176872450 HDCT_TCURdySta "19.10.01";
BA_ "Description" SG_ 2176872450 HDCT_NetrlCtrlSta "This signal indicates the status of Neutral Control Response.";
BA_ "UserSigValidity" SG_ 2176872450 HDCT_NetrlCtrlSta 3;
BA_ "RoutingFactor" SG_ 2176872450 HDCT_NetrlCtrlSta 5;
BA_ "Version" SG_ 2176872450 HDCT_NetrlCtrlSta "19.10.01";
BA_ "Description" SG_ 2176872450 HDCT_GearShftSta "HTCU_GearChgSta indicates whether a gear change is being executed in the gearbox.

Note : Gear change means a gear shift at D-range and Garage shift(PRND).";
BA_ "UserSigValidity" SG_ 2176872450 HDCT_GearShftSta 3;
BA_ "RoutingFactor" SG_ 2176872450 HDCT_GearShftSta 5;
BA_ "Version" SG_ 2176872450 HDCT_GearShftSta "19.10.01";
BA_ "Description" SG_ 2176872450 HDCT_TqRdctnVal "The HTCU requests a torque reduction via the signal CR_Tcu_TqInt_Pc to the ECU and MCU.

The requested torque HTCU_TqRdctnPcVal refers to a maximum torque CR_Ems_TqStd_Nm. This conversion into a physical quantity provides a range of CR_Ems_TqStd_Nm of 0 ..199.61%.

There is no specific phase relationship between the output and any other signal.

Conversion : (PH) = 0.390625 * (HEX) [%]";
BA_ "GenSigStartValue" SG_ 2176872450 HDCT_TqRdctnVal 1023;
BA_ "UserSigValidity" SG_ 2176872450 HDCT_TqRdctnVal 3;
BA_ "RoutingFactor" SG_ 2176872450 HDCT_TqRdctnVal 5;
BA_ "Version" SG_ 2176872450 HDCT_TqRdctnVal "20.05.02";
BA_ "Description" SG_ 2176872450 HDCT_CtrlablSta "CF_Tcu_Cont indicates the status of the HTCU control which normally works by hydraulic pressure in the T/M";
BA_ "UserSigValidity" SG_ 2176872450 HDCT_CtrlablSta 3;
BA_ "RoutingFactor" SG_ 2176872450 HDCT_CtrlablSta 5;
BA_ "Version" SG_ 2176872450 HDCT_CtrlablSta "19.10.01";
BA_ "Description" SG_ 2176872450 HTCU_SlwTqRdctnVal "The HTCU requests a slow torque reduction via the signal HTCU_TqRdctnPcVal to the ECU and MCU.";
BA_ "GenSigStartValue" SG_ 2176872450 HTCU_SlwTqRdctnVal 511;
BA_ "UserSigValidity" SG_ 2176872450 HTCU_SlwTqRdctnVal 3;
BA_ "RoutingFactor" SG_ 2176872450 HTCU_SlwTqRdctnVal 5;
BA_ "Version" SG_ 2176872450 HTCU_SlwTqRdctnVal "19.10.01";
BA_ "Description" SG_ 2176872450 HDCT_TqIncReq "An Identifier of a DCT HTCU controller for increasing torque intervention. 



This bit is to prevent the triggering of unintended DCT HTCU interventions.";
BA_ "UserSigValidity" SG_ 2176872450 HDCT_TqIncReq 3;
BA_ "RoutingFactor" SG_ 2176872450 HDCT_TqIncReq 5;
BA_ "Version" SG_ 2176872450 HDCT_TqIncReq "19.10.01";
BA_ "Description" SG_ 2176872450 HDCT_TqIncVal "The HTCU requests the engine RPM increase via the signal HTCU_TqIncPcVal to the EMS..

The requested torque HTCU_TqIncPcVal refers to maximum torque CR_Ems_TqStd_Nm. This conversion into a physical quantity provides a range of CR_Ems_TqStd_Nm of 0..99.6094%.";
BA_ "UserSigValidity" SG_ 2176872450 HDCT_TqIncVal 3;
BA_ "RoutingFactor" SG_ 2176872450 HDCT_TqIncVal 5;
BA_ "Version" SG_ 2176872450 HDCT_TqIncVal "20.05.02";
BA_ "Description" SG_ 2176872450 HDCT_TrgtShftCls "HTCU Shift Target Class";
BA_ "UserSigValidity" SG_ 2176872450 HDCT_TrgtShftCls 3;
BA_ "RoutingFactor" SG_ 2176872450 HDCT_TrgtShftCls 5;
BA_ "Version" SG_ 2176872450 HDCT_TrgtShftCls "19.10.01";
BA_ "UserSigValidity" SG_ 2176872450 HDCT_EOLReq 3;
BA_ "RoutingFactor" SG_ 2176872450 HDCT_EOLReq 5;
BA_ "Version" SG_ 2176872450 HDCT_EOLReq "19.10.01";
BA_ "Description" SG_ 2176872450 HDCT_CltchSta "Status of DCT clutches. This signal gives information about the frictional connection between the engine and the drive train.";
BA_ "UserSigValidity" SG_ 2176872450 HDCT_CltchSta 3;
BA_ "RoutingFactor" SG_ 2176872450 HDCT_CltchSta 5;
BA_ "Version" SG_ 2176872450 HDCT_CltchSta "19.10.01";
BA_ "UserSigValidity" SG_ 2176872450 HDCT_DblCltchSta 3;
BA_ "RoutingFactor" SG_ 2176872450 HDCT_DblCltchSta 5;
BA_ "Version" SG_ 2176872450 HDCT_DblCltchSta "19.10.01";
BA_ "Description" SG_ 2176872450 HDCT_AcnChrgInhbtReq "Inhibit changes of engine torque. e.g. by changing status of the air condition.";
BA_ "UserSigValidity" SG_ 2176872450 HDCT_AcnChrgInhbtReq 3;
BA_ "RoutingFactor" SG_ 2176872450 HDCT_AcnChrgInhbtReq 5;
BA_ "Version" SG_ 2176872450 HDCT_AcnChrgInhbtReq "19.10.01";
BA_ "UserSigValidity" SG_ 2176872450 HDCT_SlipCrnkAllw 3;
BA_ "RoutingFactor" SG_ 2176872450 HDCT_SlipCrnkAllw 5;
BA_ "Version" SG_ 2176872450 HDCT_SlipCrnkAllw "19.10.01";
BA_ "UserSigValidity" SG_ 2176872450 HDCT_KckDnSkpShftCnt 3;
BA_ "RoutingFactor" SG_ 2176872450 HDCT_KckDnSkpShftCnt 5;
BA_ "Version" SG_ 2176872450 HDCT_KckDnSkpShftCnt "19.10.01";
BA_ "Description" SG_ 2176872450 HDCT_ShftPhase "HDCT_ShftPhaseSta informs about control shift phase of the release element or apply element during shifting.";
BA_ "UserSigValidity" SG_ 2176872450 HDCT_ShftPhase 3;
BA_ "RoutingFactor" SG_ 2176872450 HDCT_ShftPhase 5;
BA_ "Version" SG_ 2176872450 HDCT_ShftPhase "19.10.01";
BA_ "GenMsgSendType" BO_ 2176872451 0;
BA_ "GenMsgCycleTime" BO_ 2176872451 50;
BA_ "GenMsgCycleTimeFast" BO_ 2176872451 0;
BA_ "GenMsgNrOfRepetition" BO_ 2176872451 0;
BA_ "VFrameFormat" BO_ 2176872451 1;
BA_ "Description" SG_ 2176872451 HDCT_FuelCutReq "Fuel Cut request bit signal to let EMS perform ¡®Fuel Cut torque intervention¡¯ during shift.";
BA_ "UserSigValidity" SG_ 2176872451 HDCT_FuelCutReq 3;
BA_ "RoutingFactor" SG_ 2176872451 HDCT_FuelCutReq 5;
BA_ "Version" SG_ 2176872451 HDCT_FuelCutReq "19.10.02";
BA_ "Description" SG_ 2176872451 HDCT_NCoastTrgtGear "Target Gear Information to Control of gN Coast Down";
BA_ "UserSigValidity" SG_ 2176872451 HDCT_NCoastTrgtGear 3;
BA_ "RoutingFactor" SG_ 2176872451 HDCT_NCoastTrgtGear 5;
BA_ "Version" SG_ 2176872451 HDCT_NCoastTrgtGear "19.10.02";
BA_ "Description" SG_ 2176872451 HDCT_CLUEngSpdFlag "Flag for Engine RPM(from ECU) Display on Cluster, Only when this flag is set to 1, Cluster shall display the Engine RPM from TCU";
BA_ "UserSigValidity" SG_ 2176872451 HDCT_CLUEngSpdFlag 3;
BA_ "RoutingFactor" SG_ 2176872451 HDCT_CLUEngSpdFlag 5;
BA_ "Version" SG_ 2176872451 HDCT_CLUEngSpdFlag "19.10.02";
BA_ "Description" SG_ 2176872451 HDCT_CLUTrgtGear "This target gear signal is only for Cluster.



It is different with HTCU_TrgtGearSta.";
BA_ "UserSigValidity" SG_ 2176872451 HDCT_CLUTrgtGear 3;
BA_ "RoutingFactor" SG_ 2176872451 HDCT_CLUTrgtGear 5;
BA_ "Version" SG_ 2176872451 HDCT_CLUTrgtGear "19.10.02";
BA_ "Description" SG_ 2176872451 HDCT_GSITrgtGear "Target Gear Information for Gear Shift Indicator";
BA_ "UserSigValidity" SG_ 2176872451 HDCT_GSITrgtGear 3;
BA_ "RoutingFactor" SG_ 2176872451 HDCT_GSITrgtGear 5;
BA_ "Version" SG_ 2176872451 HDCT_GSITrgtGear "19.10.02";
BA_ "Description" SG_ 2176872451 HDCT_NCoastDnReq "Act of gN Coast Down 

(Requested of Not Requested)";
BA_ "UserSigValidity" SG_ 2176872451 HDCT_NCoastDnReq 3;
BA_ "RoutingFactor" SG_ 2176872451 HDCT_NCoastDnReq 5;
BA_ "Version" SG_ 2176872451 HDCT_NCoastDnReq "19.10.02";
BA_ "Description" SG_ 2176872451 HDCT_CLUEngSpd "Engine RPM from TCU(only for the display on Cluster)";
BA_ "UserSigValidity" SG_ 2176872451 HDCT_CLUEngSpd 3;
BA_ "RoutingFactor" SG_ 2176872451 HDCT_CLUEngSpd 5;
BA_ "Version" SG_ 2176872451 HDCT_CLUEngSpd "19.10.02";
BA_ "GenMsgCycleTime" BO_ 676 0;
BA_ "Description" SG_ 676 C_DrAirSptNValueSet_EC "Driver Seat Smart Air Support On/Off";
BA_ "GenSigSendType" SG_ 676 C_DrAirSptNValueSet_EC 4;
BA_ "UserSigValidity" SG_ 676 C_DrAirSptNValueSet_EC 0;
BA_REL_ "GenSigTimeoutTime" BU_SG_REL_ DLBCU SG_ 676 C_DrAirSptNValueSet_EC 0;
BA_REL_ "GenSigTimeoutTime" BU_SG_REL_ DSAU SG_ 676 C_DrAirSptNValueSet_EC 0;
BA_ "Version" SG_ 676 C_DrAirSptNValueSet_EC "20.02.03";
BA_ "Description" SG_ 676 C_DrCushSoftNValueSet_EC "Driver Seat Cushion Softness";
BA_ "GenSigSendType" SG_ 676 C_DrCushSoftNValueSet_EC 4;
BA_ "UserSigValidity" SG_ 676 C_DrCushSoftNValueSet_EC 0;
BA_REL_ "GenSigTimeoutTime" BU_SG_REL_ DLBCU SG_ 676 C_DrCushSoftNValueSet_EC 0;
BA_REL_ "GenSigTimeoutTime" BU_SG_REL_ DSAU SG_ 676 C_DrCushSoftNValueSet_EC 0;
BA_ "Version" SG_ 676 C_DrCushSoftNValueSet_EC "20.02.03";
BA_ "Description" SG_ 676 C_AstAirSptNValueSet_EC "Assistant Seat Smart Air Support On/Off";
BA_ "GenSigSendType" SG_ 676 C_AstAirSptNValueSet_EC 4;
BA_ "UserSigValidity" SG_ 676 C_AstAirSptNValueSet_EC 0;
BA_REL_ "GenSigTimeoutTime" BU_SG_REL_ ASAU SG_ 676 C_AstAirSptNValueSet_EC 0;
BA_REL_ "GenSigTimeoutTime" BU_SG_REL_ ALBCU SG_ 676 C_AstAirSptNValueSet_EC 0;
BA_ "Version" SG_ 676 C_AstAirSptNValueSet_EC "20.02.03";
BA_ "Description" SG_ 676 C_DrBackSoftNValueSet_EC "Driver Seat Back Softness";
BA_ "GenSigSendType" SG_ 676 C_DrBackSoftNValueSet_EC 4;
BA_ "UserSigValidity" SG_ 676 C_DrBackSoftNValueSet_EC 0;
BA_REL_ "GenSigTimeoutTime" BU_SG_REL_ DLBCU SG_ 676 C_DrBackSoftNValueSet_EC 0;
BA_REL_ "GenSigTimeoutTime" BU_SG_REL_ DSAU SG_ 676 C_DrBackSoftNValueSet_EC 0;
BA_ "Version" SG_ 676 C_DrBackSoftNValueSet_EC "20.02.03";
BA_ "Description" SG_ 676 C_AstAirSptModeNValueSet_EC "Assistant Seat Smart Air Support Mode";
BA_ "GenSigSendType" SG_ 676 C_AstAirSptModeNValueSet_EC 4;
BA_ "UserSigValidity" SG_ 676 C_AstAirSptModeNValueSet_EC 0;
BA_REL_ "GenSigTimeoutTime" BU_SG_REL_ ASAU SG_ 676 C_AstAirSptModeNValueSet_EC 0;
BA_REL_ "GenSigTimeoutTime" BU_SG_REL_ ALBCU SG_ 676 C_AstAirSptModeNValueSet_EC 0;
BA_ "Version" SG_ 676 C_AstAirSptModeNValueSet_EC "20.02.03";
BA_ "Description" SG_ 676 C_DrAirSptModeNValueSet_EC "Driver Seat Smart Air Support Mode";
BA_ "GenSigSendType" SG_ 676 C_DrAirSptModeNValueSet_EC 4;
BA_ "UserSigValidity" SG_ 676 C_DrAirSptModeNValueSet_EC 0;
BA_REL_ "GenSigTimeoutTime" BU_SG_REL_ DLBCU SG_ 676 C_DrAirSptModeNValueSet_EC 0;
BA_REL_ "GenSigTimeoutTime" BU_SG_REL_ DSAU SG_ 676 C_DrAirSptModeNValueSet_EC 0;
BA_ "Version" SG_ 676 C_DrAirSptModeNValueSet_EC "20.02.03";
BA_ "Description" SG_ 676 C_RLAirSptNValueSet_EC "2nd Left Seat Smart Air Support On/Off";
BA_ "GenSigSendType" SG_ 676 C_RLAirSptNValueSet_EC 4;
BA_ "UserSigValidity" SG_ 676 C_RLAirSptNValueSet_EC 0;
BA_REL_ "GenSigTimeoutTime" BU_SG_REL_ RLPSU SG_ 676 C_RLAirSptNValueSet_EC 0;
BA_REL_ "GenSigTimeoutTime" BU_SG_REL_ ATS SG_ 676 C_RLAirSptNValueSet_EC 0;
BA_ "Version" SG_ 676 C_RLAirSptNValueSet_EC "20.02.03";
BA_ "Description" SG_ 676 C_AstAirSptStrNValueSet_EC "Assistant Seat Smart Air Support Strength";
BA_ "GenSigSendType" SG_ 676 C_AstAirSptStrNValueSet_EC 4;
BA_ "UserSigValidity" SG_ 676 C_AstAirSptStrNValueSet_EC 0;
BA_REL_ "GenSigTimeoutTime" BU_SG_REL_ ASAU SG_ 676 C_AstAirSptStrNValueSet_EC 0;
BA_REL_ "GenSigTimeoutTime" BU_SG_REL_ ALBCU SG_ 676 C_AstAirSptStrNValueSet_EC 0;
BA_ "Version" SG_ 676 C_AstAirSptStrNValueSet_EC "20.02.03";
BA_ "Description" SG_ 676 C_AstAirSptTimeNValueSet_EC "Assistant Seat Smart Air Support Time";
BA_ "GenSigSendType" SG_ 676 C_AstAirSptTimeNValueSet_EC 4;
BA_ "UserSigValidity" SG_ 676 C_AstAirSptTimeNValueSet_EC 0;
BA_REL_ "GenSigTimeoutTime" BU_SG_REL_ ASAU SG_ 676 C_AstAirSptTimeNValueSet_EC 0;
BA_REL_ "GenSigTimeoutTime" BU_SG_REL_ ALBCU SG_ 676 C_AstAirSptTimeNValueSet_EC 0;
BA_ "Version" SG_ 676 C_AstAirSptTimeNValueSet_EC "20.02.03";
BA_ "Description" SG_ 676 C_RRAirSptNValueSet_EC "2nd Right side seat Smart Air Support On/Off";
BA_ "GenSigSendType" SG_ 676 C_RRAirSptNValueSet_EC 4;
BA_ "UserSigValidity" SG_ 676 C_RRAirSptNValueSet_EC 0;
BA_REL_ "GenSigTimeoutTime" BU_SG_REL_ RRPSU SG_ 676 C_RRAirSptNValueSet_EC 0;
BA_REL_ "GenSigTimeoutTime" BU_SG_REL_ ATS SG_ 676 C_RRAirSptNValueSet_EC 0;
BA_ "Version" SG_ 676 C_RRAirSptNValueSet_EC "20.02.03";
BA_ "Description" SG_ 676 C_AstCushSoftNValueSet_EC "Assistant Seat Cushion Softness off/low/mid/high";
BA_ "GenSigSendType" SG_ 676 C_AstCushSoftNValueSet_EC 4;
BA_ "UserSigValidity" SG_ 676 C_AstCushSoftNValueSet_EC 0;
BA_REL_ "GenSigTimeoutTime" BU_SG_REL_ ASAU SG_ 676 C_AstCushSoftNValueSet_EC 0;
BA_ "Version" SG_ 676 C_AstCushSoftNValueSet_EC "20.02.03";
BA_ "Description" SG_ 676 C_AstBackSoftNValueSet_EC "Assistant Seat Back Softness Off/Low/Mid/High";
BA_ "GenSigSendType" SG_ 676 C_AstBackSoftNValueSet_EC 4;
BA_ "UserSigValidity" SG_ 676 C_AstBackSoftNValueSet_EC 0;
BA_REL_ "GenSigTimeoutTime" BU_SG_REL_ ASAU SG_ 676 C_AstBackSoftNValueSet_EC 0;
BA_ "Version" SG_ 676 C_AstBackSoftNValueSet_EC "20.02.03";
BA_ "Description" SG_ 676 C_AstRlxNValueSet_EC "Assistant seat Moving control : Relaxtion mode";
BA_ "GenSigSendType" SG_ 676 C_AstRlxNValueSet_EC 4;
BA_ "UserSigValidity" SG_ 676 C_AstRlxNValueSet_EC 0;
BA_REL_ "GenSigTimeoutTime" BU_SG_REL_ APSU SG_ 676 C_AstRlxNValueSet_EC 0;
BA_ "Version" SG_ 676 C_AstRlxNValueSet_EC "20.02.03";
BA_ "Description" SG_ 676 C_RLAirSptModeNValueSet_EC "2nd Left Seat Smart Air Support Mode";
BA_ "GenSigSendType" SG_ 676 C_RLAirSptModeNValueSet_EC 4;
BA_ "UserSigValidity" SG_ 676 C_RLAirSptModeNValueSet_EC 0;
BA_REL_ "GenSigTimeoutTime" BU_SG_REL_ RLPSU SG_ 676 C_RLAirSptModeNValueSet_EC 0;
BA_REL_ "GenSigTimeoutTime" BU_SG_REL_ ATS SG_ 676 C_RLAirSptModeNValueSet_EC 0;
BA_ "Version" SG_ 676 C_RLAirSptModeNValueSet_EC "20.02.03";
BA_ "Description" SG_ 676 C_DrAirSptStrNValueSet_EC "Driver Seat Smart Air Support Strength";
BA_ "GenSigSendType" SG_ 676 C_DrAirSptStrNValueSet_EC 4;
BA_ "UserSigValidity" SG_ 676 C_DrAirSptStrNValueSet_EC 0;
BA_REL_ "GenSigTimeoutTime" BU_SG_REL_ DLBCU SG_ 676 C_DrAirSptStrNValueSet_EC 0;
BA_REL_ "GenSigTimeoutTime" BU_SG_REL_ DSAU SG_ 676 C_DrAirSptStrNValueSet_EC 0;
BA_ "Version" SG_ 676 C_DrAirSptStrNValueSet_EC "20.02.03";
BA_ "Description" SG_ 676 C_RLAirSptStrNValueSet_EC "2nd Left Seat Smart Air Support Strength";
BA_ "GenSigSendType" SG_ 676 C_RLAirSptStrNValueSet_EC 4;
BA_ "UserSigValidity" SG_ 676 C_RLAirSptStrNValueSet_EC 0;
BA_REL_ "GenSigTimeoutTime" BU_SG_REL_ RLPSU SG_ 676 C_RLAirSptStrNValueSet_EC 0;
BA_REL_ "GenSigTimeoutTime" BU_SG_REL_ ATS SG_ 676 C_RLAirSptStrNValueSet_EC 0;
BA_ "Version" SG_ 676 C_RLAirSptStrNValueSet_EC "20.02.03";
BA_ "Description" SG_ 676 C_RLAirSptTimeNValueSet_EC "2nd Left Seat Smart Air Support Time";
BA_ "GenSigSendType" SG_ 676 C_RLAirSptTimeNValueSet_EC 4;
BA_ "UserSigValidity" SG_ 676 C_RLAirSptTimeNValueSet_EC 0;
BA_REL_ "GenSigTimeoutTime" BU_SG_REL_ RLPSU SG_ 676 C_RLAirSptTimeNValueSet_EC 0;
BA_REL_ "GenSigTimeoutTime" BU_SG_REL_ ATS SG_ 676 C_RLAirSptTimeNValueSet_EC 0;
BA_ "Version" SG_ 676 C_RLAirSptTimeNValueSet_EC "20.02.03";
BA_ "Description" SG_ 676 C_DrAirSptTimeNValueSet_EC "Driver Seat Smart Air Support Time";
BA_ "GenSigSendType" SG_ 676 C_DrAirSptTimeNValueSet_EC 4;
BA_ "UserSigValidity" SG_ 676 C_DrAirSptTimeNValueSet_EC 0;
BA_REL_ "GenSigTimeoutTime" BU_SG_REL_ DLBCU SG_ 676 C_DrAirSptTimeNValueSet_EC 0;
BA_REL_ "GenSigTimeoutTime" BU_SG_REL_ DSAU SG_ 676 C_DrAirSptTimeNValueSet_EC 0;
BA_ "Version" SG_ 676 C_DrAirSptTimeNValueSet_EC "20.02.03";
BA_ "GenMsgCycleTime" BO_ 677 0;
BA_ "Description" SG_ 677 C_RLBackSoftNValueSet_EC "2nd Left Seat Back Softness";
BA_ "GenSigSendType" SG_ 677 C_RLBackSoftNValueSet_EC 4;
BA_ "UserSigValidity" SG_ 677 C_RLBackSoftNValueSet_EC 0;
BA_REL_ "GenSigTimeoutTime" BU_SG_REL_ RLPSU SG_ 677 C_RLBackSoftNValueSet_EC 0;
BA_REL_ "GenSigTimeoutTime" BU_SG_REL_ ATS SG_ 677 C_RLBackSoftNValueSet_EC 0;
BA_ "Version" SG_ 677 C_RLBackSoftNValueSet_EC "20.02.03";
BA_ "Description" SG_ 677 C_RRAirSptStrNValueSet_EC "2nd Right side seat Smart Air Support Strength";
BA_ "GenSigSendType" SG_ 677 C_RRAirSptStrNValueSet_EC 4;
BA_ "UserSigValidity" SG_ 677 C_RRAirSptStrNValueSet_EC 0;
BA_REL_ "GenSigTimeoutTime" BU_SG_REL_ RRPSU SG_ 677 C_RRAirSptStrNValueSet_EC 0;
BA_REL_ "GenSigTimeoutTime" BU_SG_REL_ ATS SG_ 677 C_RRAirSptStrNValueSet_EC 0;
BA_ "Version" SG_ 677 C_RRAirSptStrNValueSet_EC "20.02.03";
BA_ "Description" SG_ 677 C_RRAirSptTimeNValueSet_EC "2nd Right side seat Smart Air Support Time";
BA_ "GenSigSendType" SG_ 677 C_RRAirSptTimeNValueSet_EC 4;
BA_ "UserSigValidity" SG_ 677 C_RRAirSptTimeNValueSet_EC 0;
BA_REL_ "GenSigTimeoutTime" BU_SG_REL_ RRPSU SG_ 677 C_RRAirSptTimeNValueSet_EC 0;
BA_REL_ "GenSigTimeoutTime" BU_SG_REL_ ATS SG_ 677 C_RRAirSptTimeNValueSet_EC 0;
BA_ "Version" SG_ 677 C_RRAirSptTimeNValueSet_EC "20.02.03";
BA_ "Description" SG_ 677 C_RRBackSoftNValueSet_EC "2nd Right side seat Back Softness";
BA_ "GenSigSendType" SG_ 677 C_RRBackSoftNValueSet_EC 4;
BA_ "UserSigValidity" SG_ 677 C_RRBackSoftNValueSet_EC 0;
BA_REL_ "GenSigTimeoutTime" BU_SG_REL_ RRPSU SG_ 677 C_RRBackSoftNValueSet_EC 0;
BA_REL_ "GenSigTimeoutTime" BU_SG_REL_ ATS SG_ 677 C_RRBackSoftNValueSet_EC 0;
BA_ "Version" SG_ 677 C_RRBackSoftNValueSet_EC "20.02.03";
BA_ "Description" SG_ 677 C_RROneTchNvalueSet_EC "2nd Right side seat One Touch Mode";
BA_ "GenSigSendType" SG_ 677 C_RROneTchNvalueSet_EC 4;
BA_ "UserSigValidity" SG_ 677 C_RROneTchNvalueSet_EC 0;
BA_REL_ "GenSigTimeoutTime" BU_SG_REL_ RRPSU SG_ 677 C_RROneTchNvalueSet_EC 0;
BA_REL_ "GenSigTimeoutTime" BU_SG_REL_ ATS SG_ 677 C_RROneTchNvalueSet_EC 0;
BA_ "Version" SG_ 677 C_RROneTchNvalueSet_EC "20.02.03";
BA_ "Description" SG_ 677 C_RLOneTchNValueSet_EC "2nd Left side seat One Touch Mode";
BA_ "GenSigSendType" SG_ 677 C_RLOneTchNValueSet_EC 4;
BA_ "UserSigValidity" SG_ 677 C_RLOneTchNValueSet_EC 0;
BA_REL_ "GenSigTimeoutTime" BU_SG_REL_ RRPSU SG_ 677 C_RLOneTchNValueSet_EC 0;
BA_REL_ "GenSigTimeoutTime" BU_SG_REL_ RLPSU SG_ 677 C_RLOneTchNValueSet_EC 0;
BA_REL_ "GenSigTimeoutTime" BU_SG_REL_ ATS SG_ 677 C_RLOneTchNValueSet_EC 0;
BA_ "Version" SG_ 677 C_RLOneTchNValueSet_EC "20.02.03";
BA_ "Description" SG_ 677 C_RRAirSptModeNValueSet_EC "2nd Right side seat Moving control : Smart Air Support Mode";
BA_ "GenSigSendType" SG_ 677 C_RRAirSptModeNValueSet_EC 4;
BA_ "UserSigValidity" SG_ 677 C_RRAirSptModeNValueSet_EC 0;
BA_REL_ "GenSigTimeoutTime" BU_SG_REL_ RRPSU SG_ 677 C_RRAirSptModeNValueSet_EC 0;
BA_REL_ "GenSigTimeoutTime" BU_SG_REL_ ATS SG_ 677 C_RRAirSptModeNValueSet_EC 0;
BA_ "Version" SG_ 677 C_RRAirSptModeNValueSet_EC "20.02.03";
BA_ "GenMsgCycleTime" BO_ 1219 0;
BA_ "Description" SG_ 1219 BLTN_CAM_Rec_OWD_NvalueSet "Record On/Off Set of On While Driving";
BA_ "GenSigSendType" SG_ 1219 BLTN_CAM_Rec_OWD_NvalueSet 4;
BA_ "UserSigValidity" SG_ 1219 BLTN_CAM_Rec_OWD_NvalueSet 0;
BA_REL_ "GenSigTimeoutTime" BU_SG_REL_ BLTN_CAM SG_ 1219 BLTN_CAM_Rec_OWD_NvalueSet 0;
BA_ "Version" SG_ 1219 BLTN_CAM_Rec_OWD_NvalueSet "21.05.02";
BA_ "Description" SG_ 1219 BLTN_CAM_Time_Stm_NvalueSet "Record Set of Date and Time Stamp";
BA_ "GenSigSendType" SG_ 1219 BLTN_CAM_Time_Stm_NvalueSet 4;
BA_ "UserSigValidity" SG_ 1219 BLTN_CAM_Time_Stm_NvalueSet 0;
BA_REL_ "GenSigTimeoutTime" BU_SG_REL_ BLTN_CAM SG_ 1219 BLTN_CAM_Time_Stm_NvalueSet 0;
BA_ "Version" SG_ 1219 BLTN_CAM_Time_Stm_NvalueSet "21.05.02";
BA_ "Description" SG_ 1219 BLTN_CAM_Spd_Stm_NvalueSet "Record Set of Speed Stamp";
BA_ "GenSigSendType" SG_ 1219 BLTN_CAM_Spd_Stm_NvalueSet 4;
BA_ "UserSigValidity" SG_ 1219 BLTN_CAM_Spd_Stm_NvalueSet 0;
BA_REL_ "GenSigTimeoutTime" BU_SG_REL_ BLTN_CAM SG_ 1219 BLTN_CAM_Spd_Stm_NvalueSet 0;
BA_ "Version" SG_ 1219 BLTN_CAM_Spd_Stm_NvalueSet "21.11.07";
BA_ "Description" SG_ 1219 BLTN_CAM_Locatn_Stm_NvalueSet "Record Set of Location Stamp";
BA_ "GenSigSendType" SG_ 1219 BLTN_CAM_Locatn_Stm_NvalueSet 4;
BA_ "UserSigValidity" SG_ 1219 BLTN_CAM_Locatn_Stm_NvalueSet 0;
BA_REL_ "GenSigTimeoutTime" BU_SG_REL_ BLTN_CAM SG_ 1219 BLTN_CAM_Locatn_Stm_NvalueSet 0;
BA_ "Version" SG_ 1219 BLTN_CAM_Locatn_Stm_NvalueSet "21.05.02";
BA_ "Description" SG_ 1219 BLTN_CAM_TrnSig_Stm_NvalueSet "Record Set of Turn Signal Stamp";
BA_ "GenSigSendType" SG_ 1219 BLTN_CAM_TrnSig_Stm_NvalueSet 4;
BA_ "UserSigValidity" SG_ 1219 BLTN_CAM_TrnSig_Stm_NvalueSet 0;
BA_REL_ "GenSigTimeoutTime" BU_SG_REL_ BLTN_CAM SG_ 1219 BLTN_CAM_TrnSig_Stm_NvalueSet 0;
BA_ "Version" SG_ 1219 BLTN_CAM_TrnSig_Stm_NvalueSet "21.05.02";
BA_ "Description" SG_ 1219 BLTN_CAM_AclBrk_Stm_NvalueSet "Record Set of Accelerator Brake Stamp";
BA_ "GenSigSendType" SG_ 1219 BLTN_CAM_AclBrk_Stm_NvalueSet 4;
BA_ "UserSigValidity" SG_ 1219 BLTN_CAM_AclBrk_Stm_NvalueSet 0;
BA_REL_ "GenSigTimeoutTime" BU_SG_REL_ BLTN_CAM SG_ 1219 BLTN_CAM_AclBrk_Stm_NvalueSet 0;
BA_ "Version" SG_ 1219 BLTN_CAM_AclBrk_Stm_NvalueSet "21.11.07";
BA_ "Description" SG_ 1219 BLTN_CAM_Rec_DEV_NvalueSet "Record On/Off Set of Driving Event";
BA_ "GenSigSendType" SG_ 1219 BLTN_CAM_Rec_DEV_NvalueSet 4;
BA_ "UserSigValidity" SG_ 1219 BLTN_CAM_Rec_DEV_NvalueSet 0;
BA_REL_ "GenSigTimeoutTime" BU_SG_REL_ BLTN_CAM SG_ 1219 BLTN_CAM_Rec_DEV_NvalueSet 0;
BA_ "Version" SG_ 1219 BLTN_CAM_Rec_DEV_NvalueSet "21.05.02";
BA_ "Description" SG_ 1219 BLTN_CAM_GearPos_Stm_NvalueSet "Record Set of Gear Position Stamp";
BA_ "GenSigSendType" SG_ 1219 BLTN_CAM_GearPos_Stm_NvalueSet 4;
BA_ "UserSigValidity" SG_ 1219 BLTN_CAM_GearPos_Stm_NvalueSet 0;
BA_REL_ "GenSigTimeoutTime" BU_SG_REL_ BLTN_CAM SG_ 1219 BLTN_CAM_GearPos_Stm_NvalueSet 0;
BA_ "Version" SG_ 1219 BLTN_CAM_GearPos_Stm_NvalueSet "21.11.07";
BA_ "Description" SG_ 1219 BLTN_CAM_EVSen_Stm_NvalueSet "Record Set of Event Sensitivity Stamp";
BA_ "GenSigSendType" SG_ 1219 BLTN_CAM_EVSen_Stm_NvalueSet 4;
BA_ "UserSigValidity" SG_ 1219 BLTN_CAM_EVSen_Stm_NvalueSet 0;
BA_REL_ "GenSigTimeoutTime" BU_SG_REL_ BLTN_CAM SG_ 1219 BLTN_CAM_EVSen_Stm_NvalueSet 0;
BA_ "Version" SG_ 1219 BLTN_CAM_EVSen_Stm_NvalueSet "21.05.02";
BA_ "Description" SG_ 1219 BLTN_CAM_Strangl_Stm_NvalueSet "Record Set of Steering Angle Stamp";
BA_ "GenSigSendType" SG_ 1219 BLTN_CAM_Strangl_Stm_NvalueSet 4;
BA_ "UserSigValidity" SG_ 1219 BLTN_CAM_Strangl_Stm_NvalueSet 0;
BA_REL_ "GenSigTimeoutTime" BU_SG_REL_ BLTN_CAM SG_ 1219 BLTN_CAM_Strangl_Stm_NvalueSet 0;
BA_ "Version" SG_ 1219 BLTN_CAM_Strangl_Stm_NvalueSet "21.07.05";
BA_ "Description" SG_ 1219 BLTN_CAM_PrkTime_NvalueSet "Parking Operation Setting Time, Resolution : hr";
BA_ "GenSigSendType" SG_ 1219 BLTN_CAM_PrkTime_NvalueSet 4;
BA_ "UserSigValidity" SG_ 1219 BLTN_CAM_PrkTime_NvalueSet 0;
BA_REL_ "GenSigTimeoutTime" BU_SG_REL_ BLTN_CAM SG_ 1219 BLTN_CAM_PrkTime_NvalueSet 0;
BA_ "Version" SG_ 1219 BLTN_CAM_PrkTime_NvalueSet "21.11.07";
BA_ "Description" SG_ 1219 BLTN_CAM_EV_BfrTime_NvalueSet "Driving Event Time Setting - Before, Resolution : sec";
BA_ "GenSigSendType" SG_ 1219 BLTN_CAM_EV_BfrTime_NvalueSet 4;
BA_ "UserSigValidity" SG_ 1219 BLTN_CAM_EV_BfrTime_NvalueSet 0;
BA_REL_ "GenSigTimeoutTime" BU_SG_REL_ BLTN_CAM SG_ 1219 BLTN_CAM_EV_BfrTime_NvalueSet 0;
BA_ "Version" SG_ 1219 BLTN_CAM_EV_BfrTime_NvalueSet "21.05.02";
BA_ "Description" SG_ 1219 BLTN_CAM_Rec_OWP_NvalueSet "Record On/Off Set of On While Parked, 0x0(Default) : Parking recording function not supported";
BA_ "GenSigSendType" SG_ 1219 BLTN_CAM_Rec_OWP_NvalueSet 4;
BA_ "UserSigValidity" SG_ 1219 BLTN_CAM_Rec_OWP_NvalueSet 0;
BA_REL_ "GenSigTimeoutTime" BU_SG_REL_ BLTN_CAM SG_ 1219 BLTN_CAM_Rec_OWP_NvalueSet 0;
BA_ "Version" SG_ 1219 BLTN_CAM_Rec_OWP_NvalueSet "21.05.02";
BA_ "Description" SG_ 1219 BLTN_CAM_EV_AftTime_NvalueSet "Driving Event Time Setting - After, Resolution : sec";
BA_ "GenSigSendType" SG_ 1219 BLTN_CAM_EV_AftTime_NvalueSet 4;
BA_ "UserSigValidity" SG_ 1219 BLTN_CAM_EV_AftTime_NvalueSet 0;
BA_REL_ "GenSigTimeoutTime" BU_SG_REL_ BLTN_CAM SG_ 1219 BLTN_CAM_EV_AftTime_NvalueSet 0;
BA_ "Version" SG_ 1219 BLTN_CAM_EV_AftTime_NvalueSet "21.05.02";
BA_ "Description" SG_ 1219 BLTN_CAM_TML_Int_NvalueSet "Record Set of Time-lapse Interval, Resolution : sec";
BA_ "GenSigSendType" SG_ 1219 BLTN_CAM_TML_Int_NvalueSet 4;
BA_ "UserSigValidity" SG_ 1219 BLTN_CAM_TML_Int_NvalueSet 0;
BA_REL_ "GenSigTimeoutTime" BU_SG_REL_ BLTN_CAM SG_ 1219 BLTN_CAM_TML_Int_NvalueSet 0;
BA_ "Version" SG_ 1219 BLTN_CAM_TML_Int_NvalueSet "21.05.02";
BA_ "Description" SG_ 1219 BLTN_CAM_Sen_DEV_NvalueSet "Set of Event  Detection Sensitivity of Driving Mode";
BA_ "GenSigSendType" SG_ 1219 BLTN_CAM_Sen_DEV_NvalueSet 4;
BA_ "UserSigValidity" SG_ 1219 BLTN_CAM_Sen_DEV_NvalueSet 0;
BA_REL_ "GenSigTimeoutTime" BU_SG_REL_ BLTN_CAM SG_ 1219 BLTN_CAM_Sen_DEV_NvalueSet 0;
BA_ "Version" SG_ 1219 BLTN_CAM_Sen_DEV_NvalueSet "21.05.02";
BA_ "Description" SG_ 1219 BLTN_CAM_Sen_PEV_NvalueSet "Set of Event  Detection Sensitivity of Parking Mode";
BA_ "GenSigSendType" SG_ 1219 BLTN_CAM_Sen_PEV_NvalueSet 4;
BA_ "UserSigValidity" SG_ 1219 BLTN_CAM_Sen_PEV_NvalueSet 0;
BA_REL_ "GenSigTimeoutTime" BU_SG_REL_ BLTN_CAM SG_ 1219 BLTN_CAM_Sen_PEV_NvalueSet 0;
BA_ "Version" SG_ 1219 BLTN_CAM_Sen_PEV_NvalueSet "21.05.02";
BA_ "Description" SG_ 1219 BLTN_CAM_Rec_PEV_NvalueSet "Record Set of Parked Event, 0x0(Default) : Parking recording function not supported";
BA_ "GenSigSendType" SG_ 1219 BLTN_CAM_Rec_PEV_NvalueSet 4;
BA_ "UserSigValidity" SG_ 1219 BLTN_CAM_Rec_PEV_NvalueSet 0;
BA_REL_ "GenSigTimeoutTime" BU_SG_REL_ BLTN_CAM SG_ 1219 BLTN_CAM_Rec_PEV_NvalueSet 0;
BA_ "Version" SG_ 1219 BLTN_CAM_Rec_PEV_NvalueSet "21.05.02";
BA_ "Description" SG_ 1219 BLTN_CAM_AudRec_NvalueSet "Audio Record On/Off Set";
BA_ "GenSigSendType" SG_ 1219 BLTN_CAM_AudRec_NvalueSet 4;
BA_ "UserSigValidity" SG_ 1219 BLTN_CAM_AudRec_NvalueSet 0;
BA_REL_ "GenSigTimeoutTime" BU_SG_REL_ BLTN_CAM SG_ 1219 BLTN_CAM_AudRec_NvalueSet 0;
BA_ "Version" SG_ 1219 BLTN_CAM_AudRec_NvalueSet "21.06.10";
BA_ "GenMsgSendType" BO_ 1239 0;
BA_ "Description" SG_ 1239 HU_MKBD_BtnLEDCtr "MKBD Button LED Backlight control signal (Hidden Light Button)";
BA_ "GenSigSendType" SG_ 1239 HU_MKBD_BtnLEDCtr 4;
BA_ "GenSigStartValue" SG_ 1239 HU_MKBD_BtnLEDCtr 3;
BA_ "UserSigValidity" SG_ 1239 HU_MKBD_BtnLEDCtr 0;
BA_ "Version" SG_ 1239 HU_MKBD_BtnLEDCtr "19.07.05";
BA_ "Description" SG_ 1239 HU_ADMSettingState "The signal transfers ADM Setting Value(On/Off) from HU to other module.";
BA_ "GenSigSendType" SG_ 1239 HU_ADMSettingState 4;
BA_ "UserSigValidity" SG_ 1239 HU_ADMSettingState 0;
BA_ "NetworkRequest" SG_ 1239 HU_ADMSettingState 0;
BA_ "NetworkRequestHoldingTime" SG_ 1239 HU_ADMSettingState 5000;
BA_ "Version" SG_ 1239 HU_ADMSettingState "21.01.07";
BA_ "GenSigSendType" SG_ 1239 HU_VehiclePwr 4;
BA_ "UserSigValidity" SG_ 1239 HU_VehiclePwr 0;
BA_REL_ "GenSigTimeoutTime" BU_SG_REL_ SGU SG_ 1239 HU_VehiclePwr 1500;
BA_ "NetworkRequest" SG_ 1239 HU_VehiclePwr 0;
BA_ "NetworkRequestHoldingTime" SG_ 1239 HU_VehiclePwr 5000;
BA_ "Version" SG_ 1239 HU_VehiclePwr "21.01.01";
BA_ "Description" SG_ 1239 HU_BtnShowReq "This signal indicates requesting turn on/off button light for H/Unit related buttons.";
BA_ "GenSigSendType" SG_ 1239 HU_BtnShowReq 4;
BA_ "GenSigStartValue" SG_ 1239 HU_BtnShowReq 7;
BA_ "UserSigValidity" SG_ 1239 HU_BtnShowReq 0;
BA_REL_ "GenSigTimeoutTime" BU_SG_REL_ SWRC SG_ 1239 HU_BtnShowReq 1500;
BA_ "NetworkRequest" SG_ 1239 HU_BtnShowReq 0;
BA_ "NetworkRequestHoldingTime" SG_ 1239 HU_BtnShowReq 5000;
BA_ "Version" SG_ 1239 HU_BtnShowReq "19.11.01";
BA_ "GenMsgCycleTime" BO_ 1221 0;
BA_ "Description" SG_ 1221 HU_ChgInCurrModSet "Charge current set signal";
BA_ "GenSigSendType" SG_ 1221 HU_ChgInCurrModSet 4;
BA_ "UserSigValidity" SG_ 1221 HU_ChgInCurrModSet 7;
BA_ "Version" SG_ 1221 HU_ChgInCurrModSet "19.08.06";
BA_ "Description" SG_ 1221 SWRC_Sensitivity_SET "This signal is for the SWRC Optical Switch Sensitivity Setting";
BA_ "GenSigSendType" SG_ 1221 SWRC_Sensitivity_SET 4;
BA_ "GenSigStartValue" SG_ 1221 SWRC_Sensitivity_SET 3;
BA_ "UserSigValidity" SG_ 1221 SWRC_Sensitivity_SET 3;
BA_REL_ "GenSigTimeoutTime" BU_SG_REL_ SWRC SG_ 1221 SWRC_Sensitivity_SET 0;
BA_ "Version" SG_ 1221 SWRC_Sensitivity_SET "19.12.00";
BA_ "Description" SG_ 1221 HU_EV_WinterMode "18.08.09_";
BA_ "GenSigSendType" SG_ 1221 HU_EV_WinterMode 4;
BA_ "GenSigStartValue" SG_ 1221 HU_EV_WinterMode 3;
BA_ "UserSigValidity" SG_ 1221 HU_EV_WinterMode 7;
BA_ "Version" SG_ 1221 HU_EV_WinterMode "18.09.04";
BA_ "Description" SG_ 1221 HU_TgSoc_ScChg_Set "18.08.09_";
BA_ "GenSigSendType" SG_ 1221 HU_TgSoc_ScChg_Set 4;
BA_ "GenSigStartValue" SG_ 1221 HU_TgSoc_ScChg_Set 255;
BA_ "UserSigValidity" SG_ 1221 HU_TgSoc_ScChg_Set 7;
BA_ "Version" SG_ 1221 HU_TgSoc_ScChg_Set "18.09.04";
BA_ "Description" SG_ 1221 HU_TgSoc_QcChg_Set "18.08.09_";
BA_ "GenSigSendType" SG_ 1221 HU_TgSoc_QcChg_Set 4;
BA_ "GenSigStartValue" SG_ 1221 HU_TgSoc_QcChg_Set 255;
BA_ "UserSigValidity" SG_ 1221 HU_TgSoc_QcChg_Set 7;
BA_ "Version" SG_ 1221 HU_TgSoc_QcChg_Set "18.09.04";
BA_ "Description" SG_ 1221 HU_UserApproval "Signal to send user decision on OTA approval.";
BA_ "GenSigSendType" SG_ 1221 HU_UserApproval 4;
BA_ "UserSigValidity" SG_ 1221 HU_UserApproval 0;
BA_ "Version" SG_ 1221 HU_UserApproval "21.03.01";
BA_ "Description" SG_ 1221 HU_OtaInfomationReq "Á¦¾î±â OTA °ü·Ã ÇÊ¿ä Á¤º¸¸¦ ¿äÃ»ÇÏ´Â ½ÅÈ£ (SW ¹öÀü, What's New, Download ÁøÇàÀ², Update ÁøÇàÀ²)";
BA_ "GenSigSendType" SG_ 1221 HU_OtaInfomationReq 4;
BA_ "UserSigValidity" SG_ 1221 HU_OtaInfomationReq 0;
BA_ "Version" SG_ 1221 HU_OtaInfomationReq "19.12.01";
BA_ "GenMsgCycleTime" BO_ 1218 0;
BA_ "Description" SG_ 1218 C_AVN_PTGHeightNValueSet "18.08.09_";
BA_ "GenSigSendType" SG_ 1218 C_AVN_PTGHeightNValueSet 4;
BA_ "UserSigValidity" SG_ 1218 C_AVN_PTGHeightNValueSet 3;
BA_ "Version" SG_ 1218 C_AVN_PTGHeightNValueSet "19.02.07";
BA_ "Description" SG_ 1218 CF_AVN_SCCMLReset "18.08.09_";
BA_ "GenSigSendType" SG_ 1218 CF_AVN_SCCMLReset 4;
BA_ "UserSigValidity" SG_ 1218 CF_AVN_SCCMLReset 3;
BA_ "Version" SG_ 1218 CF_AVN_SCCMLReset "18.09.04";
BA_ "Description" SG_ 1218 C_TgltAwayCloseNValue "USM Request for Tailgate Away Close";
BA_ "GenSigSendType" SG_ 1218 C_TgltAwayCloseNValue 4;
BA_ "UserSigValidity" SG_ 1218 C_TgltAwayCloseNValue 3;
BA_ "Version" SG_ 1218 C_TgltAwayCloseNValue "19.01.10";
BA_ "Description" SG_ 1218 C_HAnBNValueSet "18.08.09_";
BA_ "GenSigSendType" SG_ 1218 C_HAnBNValueSet 4;
BA_ "UserSigValidity" SG_ 1218 C_HAnBNValueSet 3;
BA_ "Version" SG_ 1218 C_HAnBNValueSet "18.09.04";
BA_ "Description" SG_ 1218 CF_AVN_RrSeatRemindNValueSet "18.08.09_";
BA_ "GenSigSendType" SG_ 1218 CF_AVN_RrSeatRemindNValueSet 4;
BA_ "UserSigValidity" SG_ 1218 CF_AVN_RrSeatRemindNValueSet 3;
BA_ "Version" SG_ 1218 CF_AVN_RrSeatRemindNValueSet "18.09.04";
BA_ "Description" SG_ 1218 CF_AVN_DSWNValueSet "18.08.09_";
BA_ "GenSigSendType" SG_ 1218 CF_AVN_DSWNValueSet 4;
BA_ "UserSigValidity" SG_ 1218 CF_AVN_DSWNValueSet 3;
BA_ "Version" SG_ 1218 CF_AVN_DSWNValueSet "18.09.04";
BA_ "Description" SG_ 1218 CF_AVN_RRPSU_RLNValueSet "18.08.09_";
BA_ "GenSigSendType" SG_ 1218 CF_AVN_RRPSU_RLNValueSet 4;
BA_ "UserSigValidity" SG_ 1218 CF_AVN_RRPSU_RLNValueSet 3;
BA_REL_ "GenSigTimeoutTime" BU_SG_REL_ APSU SG_ 1218 CF_AVN_RRPSU_RLNValueSet 0;
BA_REL_ "GenSigTimeoutTime" BU_SG_REL_ RRPSU SG_ 1218 CF_AVN_RRPSU_RLNValueSet 0;
BA_REL_ "GenSigTimeoutTime" BU_SG_REL_ RLPSU SG_ 1218 CF_AVN_RRPSU_RLNValueSet 0;
BA_ "Version" SG_ 1218 CF_AVN_RRPSU_RLNValueSet "18.09.04";
BA_ "Description" SG_ 1218 CF_AVN_APSUNValueSet "18.08.09_";
BA_ "GenSigSendType" SG_ 1218 CF_AVN_APSUNValueSet 4;
BA_ "UserSigValidity" SG_ 1218 CF_AVN_APSUNValueSet 3;
BA_REL_ "GenSigTimeoutTime" BU_SG_REL_ APSU SG_ 1218 CF_AVN_APSUNValueSet 0;
BA_REL_ "GenSigTimeoutTime" BU_SG_REL_ ASAU SG_ 1218 CF_AVN_APSUNValueSet 0;
BA_ "Version" SG_ 1218 CF_AVN_APSUNValueSet "18.09.04";
BA_ "Description" SG_ 1218 CF_AVN_NCC_CameraNValueSet "18.08.09_";
BA_ "GenSigSendType" SG_ 1218 CF_AVN_NCC_CameraNValueSet 4;
BA_ "UserSigValidity" SG_ 1218 CF_AVN_NCC_CameraNValueSet 3;
BA_ "Version" SG_ 1218 CF_AVN_NCC_CameraNValueSet "18.09.04";
BA_ "Description" SG_ 1218 CF_AVN_RRPSU_RRNValueSet "18.08.09_";
BA_ "GenSigSendType" SG_ 1218 CF_AVN_RRPSU_RRNValueSet 4;
BA_ "UserSigValidity" SG_ 1218 CF_AVN_RRPSU_RRNValueSet 3;
BA_REL_ "GenSigTimeoutTime" BU_SG_REL_ APSU SG_ 1218 CF_AVN_RRPSU_RRNValueSet 0;
BA_REL_ "GenSigTimeoutTime" BU_SG_REL_ RRPSU SG_ 1218 CF_AVN_RRPSU_RRNValueSet 0;
BA_REL_ "GenSigTimeoutTime" BU_SG_REL_ RLPSU SG_ 1218 CF_AVN_RRPSU_RRNValueSet 0;
BA_ "Version" SG_ 1218 CF_AVN_RRPSU_RRNValueSet "18.09.04";
BA_ "Description" SG_ 1218 CF_AVN_HtBlcAstNValueSet "18.08.09_";
BA_ "GenSigSendType" SG_ 1218 CF_AVN_HtBlcAstNValueSet 4;
BA_ "UserSigValidity" SG_ 1218 CF_AVN_HtBlcAstNValueSet 3;
BA_REL_ "GenSigTimeoutTime" BU_SG_REL_ APSU SG_ 1218 CF_AVN_HtBlcAstNValueSet 0;
BA_REL_ "GenSigTimeoutTime" BU_SG_REL_ SHVU_FR SG_ 1218 CF_AVN_HtBlcAstNValueSet 0;
BA_ "Version" SG_ 1218 CF_AVN_HtBlcAstNValueSet "18.09.04";
BA_ "Description" SG_ 1218 CF_AVN_HtBlcDrvNValueSet "18.08.09_";
BA_ "GenSigSendType" SG_ 1218 CF_AVN_HtBlcDrvNValueSet 4;
BA_ "UserSigValidity" SG_ 1218 CF_AVN_HtBlcDrvNValueSet 3;
BA_REL_ "GenSigTimeoutTime" BU_SG_REL_ APSU SG_ 1218 CF_AVN_HtBlcDrvNValueSet 0;
BA_REL_ "GenSigTimeoutTime" BU_SG_REL_ SHVU_FR SG_ 1218 CF_AVN_HtBlcDrvNValueSet 0;
BA_ "Version" SG_ 1218 CF_AVN_HtBlcDrvNValueSet "18.09.04";
BA_ "Description" SG_ 1218 CF_AVN_SCCModeNValueSet "18.12.03_";
BA_ "GenSigSendType" SG_ 1218 CF_AVN_SCCModeNValueSet 4;
BA_ "GenSigStartValue" SG_ 1218 CF_AVN_SCCModeNValueSet 3;
BA_ "UserSigValidity" SG_ 1218 CF_AVN_SCCModeNValueSet 3;
BA_ "Version" SG_ 1218 CF_AVN_SCCModeNValueSet "18.12.03";
BA_ "GenSigSendType" SG_ 1218 CF_AVN_SCCMLChar1Set 4;
BA_ "UserSigValidity" SG_ 1218 CF_AVN_SCCMLChar1Set 3;
BA_ "Version" SG_ 1218 CF_AVN_SCCMLChar1Set "19.11.05";
BA_ "Description" SG_ 1218 CF_AVN_UIPNValueSet "18.10.01_";
BA_ "GenSigSendType" SG_ 1218 CF_AVN_UIPNValueSet 4;
BA_ "UserSigValidity" SG_ 1218 CF_AVN_UIPNValueSet 3;
BA_ "Version" SG_ 1218 CF_AVN_UIPNValueSet "18.10.06";
BA_ "GenSigSendType" SG_ 1218 CF_AVN_SCCMLChar2Set 4;
BA_ "UserSigValidity" SG_ 1218 CF_AVN_SCCMLChar2Set 3;
BA_ "Version" SG_ 1218 CF_AVN_SCCMLChar2Set "19.11.05";
BA_ "GenSigSendType" SG_ 1218 CF_AVN_SCCMLChar3Set 4;
BA_ "UserSigValidity" SG_ 1218 CF_AVN_SCCMLChar3Set 3;
BA_ "Version" SG_ 1218 CF_AVN_SCCMLChar3Set "19.11.05";
BA_ "Description" SG_ 1218 CF_AVN_HDALCFuncNValueSet "18.08.09_";
BA_ "GenSigSendType" SG_ 1218 CF_AVN_HDALCFuncNValueSet 4;
BA_ "UserSigValidity" SG_ 1218 CF_AVN_HDALCFuncNValueSet 3;
BA_ "Version" SG_ 1218 CF_AVN_HDALCFuncNValueSet "18.09.04";
BA_ "GenMsgCycleTime" BO_ 675 0;
BA_ "Description" SG_ 675 Usm_RpmMUDSet "Related to Cluster Gauge";
BA_ "GenSigSendType" SG_ 675 Usm_RpmMUDSet 4;
BA_ "UserSigValidity" SG_ 675 Usm_RpmMUDSet 3;
BA_ "Version" SG_ 675 Usm_RpmMUDSet "20.02.04";
BA_ "GenSigSendType" SG_ 675 CF_AVN_HtBlcRLNValueSet 4;
BA_ "UserSigValidity" SG_ 675 CF_AVN_HtBlcRLNValueSet 3;
BA_REL_ "GenSigTimeoutTime" BU_SG_REL_ SHVU_FR SG_ 675 CF_AVN_HtBlcRLNValueSet 0;
BA_REL_ "GenSigTimeoutTime" BU_SG_REL_ SHVU_RR SG_ 675 CF_AVN_HtBlcRLNValueSet 0;
BA_REL_ "GenSigTimeoutTime" BU_SG_REL_ RRPSU SG_ 675 CF_AVN_HtBlcRLNValueSet 0;
BA_REL_ "GenSigTimeoutTime" BU_SG_REL_ RLPSU SG_ 675 CF_AVN_HtBlcRLNValueSet 0;
BA_ "Version" SG_ 675 CF_AVN_HtBlcRLNValueSet "20.06.03";
BA_ "Description" SG_ 675 CF_AVN_BRAKE_PedalfeelNValueSet2 "USM request for Brake Mode (New spec)";
BA_ "GenSigSendType" SG_ 675 CF_AVN_BRAKE_PedalfeelNValueSet2 4;
BA_ "UserSigValidity" SG_ 675 CF_AVN_BRAKE_PedalfeelNValueSet2 3;
BA_ "Version" SG_ 675 CF_AVN_BRAKE_PedalfeelNValueSet2 "20.04.06";
BA_ "Description" SG_ 675 CF_AVN_ISLA_AutoNModSet "USM Set Signal for Activing N Mode Setting when Vehicle enter into Winding Road";
BA_ "GenSigSendType" SG_ 675 CF_AVN_ISLA_AutoNModSet 4;
BA_ "UserSigValidity" SG_ 675 CF_AVN_ISLA_AutoNModSet 3;
BA_ "Version" SG_ 675 CF_AVN_ISLA_AutoNModSet "20.06.00";
BA_ "GenSigSendType" SG_ 675 CF_AVN_HtBlcRRNValueSet 4;
BA_ "UserSigValidity" SG_ 675 CF_AVN_HtBlcRRNValueSet 3;
BA_REL_ "GenSigTimeoutTime" BU_SG_REL_ SHVU_FR SG_ 675 CF_AVN_HtBlcRRNValueSet 0;
BA_REL_ "GenSigTimeoutTime" BU_SG_REL_ SHVU_RR SG_ 675 CF_AVN_HtBlcRRNValueSet 0;
BA_REL_ "GenSigTimeoutTime" BU_SG_REL_ RRPSU SG_ 675 CF_AVN_HtBlcRRNValueSet 0;
BA_REL_ "GenSigTimeoutTime" BU_SG_REL_ RLPSU SG_ 675 CF_AVN_HtBlcRRNValueSet 0;
BA_ "Version" SG_ 675 CF_AVN_HtBlcRRNValueSet "20.06.03";
BA_ "Description" SG_ 675 LapTimer_AutoMeasure_Setting "Setting value for auto-measurement of Laptimer";
BA_ "GenSigSendType" SG_ 675 LapTimer_AutoMeasure_Setting 4;
BA_ "GenSigStartValue" SG_ 675 LapTimer_AutoMeasure_Setting 3;
BA_ "UserSigValidity" SG_ 675 LapTimer_AutoMeasure_Setting 3;
BA_ "Version" SG_ 675 LapTimer_AutoMeasure_Setting "20.07.11";
BA_ "Description" SG_ 675 LapTimer_TimeGap_Setting "setting value for laptimer time gap displaying";
BA_ "GenSigSendType" SG_ 675 LapTimer_TimeGap_Setting 4;
BA_ "GenSigStartValue" SG_ 675 LapTimer_TimeGap_Setting 3;
BA_ "UserSigValidity" SG_ 675 LapTimer_TimeGap_Setting 3;
BA_ "Version" SG_ 675 LapTimer_TimeGap_Setting "20.07.11";
BA_ "Description" SG_ 675 Usm_RpmSANDSet "Related to Cluster Gauge";
BA_ "GenSigSendType" SG_ 675 Usm_RpmSANDSet 4;
BA_ "UserSigValidity" SG_ 675 Usm_RpmSANDSet 3;
BA_ "Version" SG_ 675 Usm_RpmSANDSet "20.02.04";
BA_ "Description" SG_ 675 CF_AVN_RemoteWDWNValueSet "Remote Window On/Off Set signal of USM for Fob Key";
BA_ "GenSigSendType" SG_ 675 CF_AVN_RemoteWDWNValueSet 4;
BA_ "UserSigValidity" SG_ 675 CF_AVN_RemoteWDWNValueSet 3;
BA_ "Version" SG_ 675 CF_AVN_RemoteWDWNValueSet "20.07.14";
BA_ "Description" SG_ 675 USM_TowWeight_Set "Trailer Mode Setting USM: Tow Weight set for User

-User can select the tow weight value for get the exact DTE value";
BA_ "GenSigSendType" SG_ 675 USM_TowWeight_Set 4;
BA_ "UserSigValidity" SG_ 675 USM_TowWeight_Set 7;
BA_ "Version" SG_ 675 USM_TowWeight_Set "20.10.02";
BA_ "Description" SG_ 675 CF_AVN_PABArbgNValueSet "USM PAB On/Off Set Signal";
BA_ "GenSigSendType" SG_ 675 CF_AVN_PABArbgNValueSet 4;
BA_ "UserSigValidity" SG_ 675 CF_AVN_PABArbgNValueSet 3;
BA_ "Version" SG_ 675 CF_AVN_PABArbgNValueSet "20.08.07";
BA_ "Description" SG_ 675 CF_AVN_SportHUD2 "Related to HUD Sports mode of custom mode2";
BA_ "GenSigSendType" SG_ 675 CF_AVN_SportHUD2 4;
BA_ "UserSigValidity" SG_ 675 CF_AVN_SportHUD2 3;
BA_ "Version" SG_ 675 CF_AVN_SportHUD2 "20.09.00";
BA_ "Description" SG_ 675 C_SLB_SmartCtrl_Set_Nvalue "USM time setting for Smart Posture Care 2.0  Off or 30min or 60min";
BA_ "GenSigSendType" SG_ 675 C_SLB_SmartCtrl_Set_Nvalue 4;
BA_ "UserSigValidity" SG_ 675 C_SLB_SmartCtrl_Set_Nvalue 3;
BA_REL_ "GenSigTimeoutTime" BU_SG_REL_ SLB SG_ 675 C_SLB_SmartCtrl_Set_Nvalue 0;
BA_REL_ "GenSigTimeoutTime" BU_SG_REL_ DLBCU SG_ 675 C_SLB_SmartCtrl_Set_Nvalue 0;
BA_ "Version" SG_ 675 C_SLB_SmartCtrl_Set_Nvalue "20.09.01";
BA_ "Description" SG_ 675 HU_CustomNewMenuSet "Custom Mode User Setting Signal";
BA_ "GenSigSendType" SG_ 675 HU_CustomNewMenuSet 4;
BA_ "UserSigValidity" SG_ 675 HU_CustomNewMenuSet 3;
BA_ "Version" SG_ 675 HU_CustomNewMenuSet "20.09.00";
BA_ "Description" SG_ 675 USM_RpmComfortRearSet "RPM Display Setting When Comfort(Rear) mode Set";
BA_ "GenSigSendType" SG_ 675 USM_RpmComfortRearSet 4;
BA_ "UserSigValidity" SG_ 675 USM_RpmComfortRearSet 3;
BA_ "Version" SG_ 675 USM_RpmComfortRearSet "20.10.02";
BA_ "Description" SG_ 675 Usm_RpmMyDriveModeSet "Cluster MY Drive Mode RPM Set Signal";
BA_ "GenSigSendType" SG_ 675 Usm_RpmMyDriveModeSet 4;
BA_ "UserSigValidity" SG_ 675 Usm_RpmMyDriveModeSet 3;
BA_ "Version" SG_ 675 Usm_RpmMyDriveModeSet "20.11.00";
BA_ "Description" SG_ 675 CF_AVN_PDWLmtNvalueSet "USM PDW (related VCU ECU) Set signal";
BA_ "GenSigSendType" SG_ 675 CF_AVN_PDWLmtNvalueSet 4;
BA_ "UserSigValidity" SG_ 675 CF_AVN_PDWLmtNvalueSet 3;
BA_ "Version" SG_ 675 CF_AVN_PDWLmtNvalueSet "22.02.02";
BA_ "Description" SG_ 675 CF_AVN_PCA_RrEquipNvalueSet "Headunit Setting signal for Rear Safety of USM";
BA_ "GenSigSendType" SG_ 675 CF_AVN_PCA_RrEquipNvalueSet 4;
BA_ "UserSigValidity" SG_ 675 CF_AVN_PCA_RrEquipNvalueSet 3;
BA_ "Version" SG_ 675 CF_AVN_PCA_RrEquipNvalueSet "20.06.04";
BA_ "GenMsgSendType" BO_ 1076 0;
BA_ "GenSigSendType" SG_ 1076 IAU_ProfileIDRVal 4;
BA_ "UserSigValidity" SG_ 1076 IAU_ProfileIDRVal 0;
BA_REL_ "GenSigTimeoutTime" BU_SG_REL_ WPC SG_ 1076 IAU_ProfileIDRVal 1500;
BA_REL_ "GenSigTimeoutTime" BU_SG_REL_ RWPC SG_ 1076 IAU_ProfileIDRVal 1500;
BA_REL_ "GenSigTimeoutTime" BU_SG_REL_ DPSU SG_ 1076 IAU_ProfileIDRVal 1500;
BA_REL_ "GenSigTimeoutTime" BU_SG_REL_ DLBCU SG_ 1076 IAU_ProfileIDRVal 1500;
BA_REL_ "GenSigTimeoutTime" BU_SG_REL_ RCM SG_ 1076 IAU_ProfileIDRVal 1500;
BA_REL_ "GenSigTimeoutTime" BU_SG_REL_ BLTN_CAM SG_ 1076 IAU_ProfileIDRVal 1500;
BA_REL_ "GenSigTimeoutTime" BU_SG_REL_ SGU SG_ 1076 IAU_ProfileIDRVal 1500;
BA_REL_ "GenSigTimeoutTime" BU_SG_REL_ WPC2 SG_ 1076 IAU_ProfileIDRVal 1500;
BA_ "NetworkRequest" SG_ 1076 IAU_ProfileIDRVal 0;
BA_ "NetworkRequestHoldingTime" SG_ 1076 IAU_ProfileIDRVal 5000;
BA_ "Version" SG_ 1076 IAU_ProfileIDRVal "20.05.02";
BA_ "GenSigSendType" SG_ 1076 IAU_DigitalKeyProcessingSta 4;
BA_ "UserSigValidity" SG_ 1076 IAU_DigitalKeyProcessingSta 3;
BA_ "NetworkRequest" SG_ 1076 IAU_DigitalKeyProcessingSta 0;
BA_ "NetworkRequestHoldingTime" SG_ 1076 IAU_DigitalKeyProcessingSta 5000;
BA_ "Version" SG_ 1076 IAU_DigitalKeyProcessingSta "20.11.02";
BA_ "Description" SG_ 1076 IAU_DigitalKeyExit "Digital Key USM setting Exit Condition";
BA_ "GenSigSendType" SG_ 1076 IAU_DigitalKeyExit 4;
BA_ "UserSigValidity" SG_ 1076 IAU_DigitalKeyExit 3;
BA_ "NetworkRequest" SG_ 1076 IAU_DigitalKeyExit 0;
BA_ "NetworkRequestHoldingTime" SG_ 1076 IAU_DigitalKeyExit 5000;
BA_ "Version" SG_ 1076 IAU_DigitalKeyExit "20.09.00";
BA_ "GenSigSendType" SG_ 1076 IAU_DigitalKeyEnblRVal 4;
BA_ "UserSigValidity" SG_ 1076 IAU_DigitalKeyEnblRVal 0;
BA_ "NetworkRequest" SG_ 1076 IAU_DigitalKeyEnblRVal 0;
BA_ "NetworkRequestHoldingTime" SG_ 1076 IAU_DigitalKeyEnblRVal 5000;
BA_ "Version" SG_ 1076 IAU_DigitalKeyEnblRVal "20.05.02";
BA_ "GenSigSendType" SG_ 1076 IAU_OwnerPhnRegRVal 4;
BA_ "UserSigValidity" SG_ 1076 IAU_OwnerPhnRegRVal 0;
BA_ "NetworkRequest" SG_ 1076 IAU_OwnerPhnRegRVal 0;
BA_ "NetworkRequestHoldingTime" SG_ 1076 IAU_OwnerPhnRegRVal 5000;
BA_ "Version" SG_ 1076 IAU_OwnerPhnRegRVal "20.05.02";
BA_ "GenSigSendType" SG_ 1076 IAU_NFCCard1RegRVal 4;
BA_ "UserSigValidity" SG_ 1076 IAU_NFCCard1RegRVal 0;
BA_ "NetworkRequest" SG_ 1076 IAU_NFCCard1RegRVal 0;
BA_ "NetworkRequestHoldingTime" SG_ 1076 IAU_NFCCard1RegRVal 5000;
BA_ "Version" SG_ 1076 IAU_NFCCard1RegRVal "17.12.08";
BA_ "GenSigSendType" SG_ 1076 IAU_NFCCard2RegRVal 4;
BA_ "UserSigValidity" SG_ 1076 IAU_NFCCard2RegRVal 0;
BA_ "NetworkRequest" SG_ 1076 IAU_NFCCard2RegRVal 0;
BA_ "NetworkRequestHoldingTime" SG_ 1076 IAU_NFCCard2RegRVal 5000;
BA_ "Version" SG_ 1076 IAU_NFCCard2RegRVal "17.12.08";
BA_ "Description" SG_ 1076 IAU_DISPWrng "This siganl warning from IAU";
BA_ "GenSigSendType" SG_ 1076 IAU_DISPWrng 4;
BA_ "UserSigValidity" SG_ 1076 IAU_DISPWrng 0;
BA_ "NetworkRequest" SG_ 1076 IAU_DISPWrng 0;
BA_ "NetworkRequestHoldingTime" SG_ 1076 IAU_DISPWrng 5000;
BA_ "Version" SG_ 1076 IAU_DISPWrng "20.08.07";
BA_ "Description" SG_ 1076 IAU_DigitalKey2Opt "This signal describe Digital Key capability";
BA_ "GenSigSendType" SG_ 1076 IAU_DigitalKey2Opt 4;
BA_ "UserSigValidity" SG_ 1076 IAU_DigitalKey2Opt 0;
BA_REL_ "GenSigTimeoutTime" BU_SG_REL_ WPC SG_ 1076 IAU_DigitalKey2Opt 1500;
BA_REL_ "GenSigTimeoutTime" BU_SG_REL_ WPC2 SG_ 1076 IAU_DigitalKey2Opt 1500;
BA_ "NetworkRequest" SG_ 1076 IAU_DigitalKey2Opt 0;
BA_ "NetworkRequestHoldingTime" SG_ 1076 IAU_DigitalKey2Opt 5000;
BA_ "Version" SG_ 1076 IAU_DigitalKey2Opt "20.08.00";
BA_ "Description" SG_ 1076 IAUwFRULearnState "This signal indicates learning process stste between IAU and FRU";
BA_ "GenSigSendType" SG_ 1076 IAUwFRULearnState 4;
BA_ "UserSigValidity" SG_ 1076 IAUwFRULearnState 0;
BA_ "NetworkRequest" SG_ 1076 IAUwFRULearnState 0;
BA_ "NetworkRequestHoldingTime" SG_ 1076 IAUwFRULearnState 5000;
BA_ "Version" SG_ 1076 IAUwFRULearnState "20.04.05";
BA_ "Description" SG_ 1076 IAUwFPMLearnState "This signal indicates learning process stste between IAU and FPM";
BA_ "GenSigSendType" SG_ 1076 IAUwFPMLearnState 4;
BA_ "UserSigValidity" SG_ 1076 IAUwFPMLearnState 0;
BA_ "NetworkRequest" SG_ 1076 IAUwFPMLearnState 0;
BA_ "NetworkRequestHoldingTime" SG_ 1076 IAUwFPMLearnState 5000;
BA_ "Version" SG_ 1076 IAUwFPMLearnState "20.04.05";
BA_ "GenMsgCycleTime" BO_ 1227 0;
BA_ "Description" SG_ 1227 DrvIMS_MemoryP1Req "-(Old)C_MEMP1CMD";
BA_ "GenSigSendType" SG_ 1227 DrvIMS_MemoryP1Req 4;
BA_ "UserSigValidity" SG_ 1227 DrvIMS_MemoryP1Req 0;
BA_REL_ "GenSigTimeoutTime" BU_SG_REL_ CGW_CCU SG_ 1227 DrvIMS_MemoryP1Req 0;
BA_ "NetworkRequest" SG_ 1227 DrvIMS_MemoryP1Req 0;
BA_ "NetworkRequestHoldingTime" SG_ 1227 DrvIMS_MemoryP1Req 5000;
BA_ "Version" SG_ 1227 DrvIMS_MemoryP1Req "17.11.00";
BA_ "GenSigSendType" SG_ 1227 DrvIMS_PlyBckP2Req 4;
BA_ "UserSigValidity" SG_ 1227 DrvIMS_PlyBckP2Req 0;
BA_REL_ "GenSigTimeoutTime" BU_SG_REL_ CGW_CCU SG_ 1227 DrvIMS_PlyBckP2Req 0;
BA_ "NetworkRequest" SG_ 1227 DrvIMS_PlyBckP2Req 0;
BA_ "NetworkRequestHoldingTime" SG_ 1227 DrvIMS_PlyBckP2Req 5000;
BA_ "Version" SG_ 1227 DrvIMS_PlyBckP2Req "17.11.00";
BA_ "Description" SG_ 1227 DrvIMS_PlyBckP3Req "PLAY IMS3";
BA_ "GenSigSendType" SG_ 1227 DrvIMS_PlyBckP3Req 4;
BA_ "UserSigValidity" SG_ 1227 DrvIMS_PlyBckP3Req 0;
BA_REL_ "GenSigTimeoutTime" BU_SG_REL_ CGW_CCU SG_ 1227 DrvIMS_PlyBckP3Req 0;
BA_ "NetworkRequest" SG_ 1227 DrvIMS_PlyBckP3Req 0;
BA_ "NetworkRequestHoldingTime" SG_ 1227 DrvIMS_PlyBckP3Req 5000;
BA_ "Version" SG_ 1227 DrvIMS_PlyBckP3Req "17.11.00";
BA_ "Description" SG_ 1227 DrvIMS_PlyBckStpReq "This signal is used to stop during playback";
BA_ "GenSigSendType" SG_ 1227 DrvIMS_PlyBckStpReq 4;
BA_ "UserSigValidity" SG_ 1227 DrvIMS_PlyBckStpReq 0;
BA_REL_ "GenSigTimeoutTime" BU_SG_REL_ CGW_CCU SG_ 1227 DrvIMS_PlyBckStpReq 0;
BA_ "NetworkRequest" SG_ 1227 DrvIMS_PlyBckStpReq 0;
BA_ "NetworkRequestHoldingTime" SG_ 1227 DrvIMS_PlyBckStpReq 5000;
BA_ "Version" SG_ 1227 DrvIMS_PlyBckStpReq "17.11.00";
BA_ "Description" SG_ 1227 SmrtIMS_PlyBckReq "Signal for Health Care IMS Playback DB Number";
BA_ "GenSigSendType" SG_ 1227 SmrtIMS_PlyBckReq 4;
BA_ "UserSigValidity" SG_ 1227 SmrtIMS_PlyBckReq 0;
BA_REL_ "GenSigTimeoutTime" BU_SG_REL_ CGW_CCU SG_ 1227 SmrtIMS_PlyBckReq 0;
BA_ "NetworkRequest" SG_ 1227 SmrtIMS_PlyBckReq 0;
BA_ "NetworkRequestHoldingTime" SG_ 1227 SmrtIMS_PlyBckReq 5000;
BA_ "Version" SG_ 1227 SmrtIMS_PlyBckReq "21.07.05";
BA_ "Description" SG_ 1227 DrvIMS_MemoryP2Req "-(Old)C_MEMP2CMD";
BA_ "GenSigSendType" SG_ 1227 DrvIMS_MemoryP2Req 4;
BA_ "UserSigValidity" SG_ 1227 DrvIMS_MemoryP2Req 0;
BA_REL_ "GenSigTimeoutTime" BU_SG_REL_ CGW_CCU SG_ 1227 DrvIMS_MemoryP2Req 0;
BA_ "NetworkRequest" SG_ 1227 DrvIMS_MemoryP2Req 0;
BA_ "NetworkRequestHoldingTime" SG_ 1227 DrvIMS_MemoryP2Req 5000;
BA_ "Version" SG_ 1227 DrvIMS_MemoryP2Req "17.11.00";
BA_ "Description" SG_ 1227 PSM_IMSReq "IMS request";
BA_ "GenSigSendType" SG_ 1227 PSM_IMSReq 4;
BA_ "UserSigValidity" SG_ 1227 PSM_IMSReq 0;
BA_REL_ "GenSigTimeoutTime" BU_SG_REL_ CGW_CCU SG_ 1227 PSM_IMSReq 0;
BA_ "NetworkRequest" SG_ 1227 PSM_IMSReq 0;
BA_ "NetworkRequestHoldingTime" SG_ 1227 PSM_IMSReq 5000;
BA_ "Version" SG_ 1227 PSM_IMSReq "21.02.02";
BA_ "Description" SG_ 1227 SmrtIMS_ImgDBVal "-(Old)C_SmartIMSImageDB";
BA_ "GenSigSendType" SG_ 1227 SmrtIMS_ImgDBVal 4;
BA_ "UserSigValidity" SG_ 1227 SmrtIMS_ImgDBVal 0;
BA_REL_ "GenSigTimeoutTime" BU_SG_REL_ CGW_CCU SG_ 1227 SmrtIMS_ImgDBVal 0;
BA_ "NetworkRequest" SG_ 1227 SmrtIMS_ImgDBVal 0;
BA_ "NetworkRequestHoldingTime" SG_ 1227 SmrtIMS_ImgDBVal 5000;
BA_ "Version" SG_ 1227 SmrtIMS_ImgDBVal "17.11.00";
BA_ "Description" SG_ 1227 SmrtIMS_PlyBckStpReq "Health Care IMS On/Off Flag";
BA_ "GenSigSendType" SG_ 1227 SmrtIMS_PlyBckStpReq 4;
BA_ "UserSigValidity" SG_ 1227 SmrtIMS_PlyBckStpReq 0;
BA_REL_ "GenSigTimeoutTime" BU_SG_REL_ CGW_CCU SG_ 1227 SmrtIMS_PlyBckStpReq 0;
BA_ "NetworkRequest" SG_ 1227 SmrtIMS_PlyBckStpReq 0;
BA_ "NetworkRequestHoldingTime" SG_ 1227 SmrtIMS_PlyBckStpReq 5000;
BA_ "Version" SG_ 1227 SmrtIMS_PlyBckStpReq "17.11.00";
BA_ "Description" SG_ 1227 DrvIMS_MemoryP3Req "Memory IMS3";
BA_ "GenSigSendType" SG_ 1227 DrvIMS_MemoryP3Req 4;
BA_ "UserSigValidity" SG_ 1227 DrvIMS_MemoryP3Req 0;
BA_REL_ "GenSigTimeoutTime" BU_SG_REL_ CGW_CCU SG_ 1227 DrvIMS_MemoryP3Req 0;
BA_ "NetworkRequest" SG_ 1227 DrvIMS_MemoryP3Req 0;
BA_ "NetworkRequestHoldingTime" SG_ 1227 DrvIMS_MemoryP3Req 5000;
BA_ "Version" SG_ 1227 DrvIMS_MemoryP3Req "17.11.00";
BA_ "Description" SG_ 1227 SmrtIMS_EnterSwSta "-(Old)C_SmartIMSOn";
BA_ "GenSigSendType" SG_ 1227 SmrtIMS_EnterSwSta 4;
BA_ "UserSigValidity" SG_ 1227 SmrtIMS_EnterSwSta 0;
BA_REL_ "GenSigTimeoutTime" BU_SG_REL_ CGW_CCU SG_ 1227 SmrtIMS_EnterSwSta 0;
BA_ "NetworkRequest" SG_ 1227 SmrtIMS_EnterSwSta 0;
BA_ "NetworkRequestHoldingTime" SG_ 1227 SmrtIMS_EnterSwSta 5000;
BA_ "Version" SG_ 1227 SmrtIMS_EnterSwSta "17.11.00";
BA_ "Description" SG_ 1227 DrvIMS_BzrReq "IMS ºÎÁ®À½À» Å¬·¯½ºÅÍ ½ºÇÇÄ¿¿¡¼­ Ãâ·ÂÇÏ±â À§ÇÑ ½Ã±×³Î";
BA_ "GenSigSendType" SG_ 1227 DrvIMS_BzrReq 4;
BA_ "UserSigValidity" SG_ 1227 DrvIMS_BzrReq 0;
BA_REL_ "GenSigTimeoutTime" BU_SG_REL_ CGW_CCU SG_ 1227 DrvIMS_BzrReq 0;
BA_ "NetworkRequest" SG_ 1227 DrvIMS_BzrReq 0;
BA_ "NetworkRequestHoldingTime" SG_ 1227 DrvIMS_BzrReq 5000;
BA_ "Version" SG_ 1227 DrvIMS_BzrReq "17.11.00";
BA_ "Description" SG_ 1227 DrvIMS_ErrConWmgDis "IMS ±â¾ï/Àç»ý Á¶°Ç ¿¡·¯ Ãâ·Â ½Ã±×³Î";
BA_ "GenSigSendType" SG_ 1227 DrvIMS_ErrConWmgDis 4;
BA_ "UserSigValidity" SG_ 1227 DrvIMS_ErrConWmgDis 0;
BA_REL_ "GenSigTimeoutTime" BU_SG_REL_ CGW_CCU SG_ 1227 DrvIMS_ErrConWmgDis 0;
BA_ "NetworkRequest" SG_ 1227 DrvIMS_ErrConWmgDis 0;
BA_ "NetworkRequestHoldingTime" SG_ 1227 DrvIMS_ErrConWmgDis 5000;
BA_ "Version" SG_ 1227 DrvIMS_ErrConWmgDis "18.07.01";
BA_ "Description" SG_ 1227 PSM_DrvRlxReturn_Req "one touch relax play and return";
BA_ "GenSigSendType" SG_ 1227 PSM_DrvRlxReturn_Req 4;
BA_ "UserSigValidity" SG_ 1227 PSM_DrvRlxReturn_Req 0;
BA_REL_ "GenSigTimeoutTime" BU_SG_REL_ CGW_CCU SG_ 1227 PSM_DrvRlxReturn_Req 0;
BA_ "NetworkRequest" SG_ 1227 PSM_DrvRlxReturn_Req 0;
BA_ "NetworkRequestHoldingTime" SG_ 1227 PSM_DrvRlxReturn_Req 5000;
BA_ "Version" SG_ 1227 PSM_DrvRlxReturn_Req "20.07.02";
BA_ "GenSigSendType" SG_ 1227 Drv_AutoRlxWrngDis 4;
BA_ "UserSigValidity" SG_ 1227 Drv_AutoRlxWrngDis 1;
BA_REL_ "GenSigTimeoutTime" BU_SG_REL_ CGW_CCU SG_ 1227 Drv_AutoRlxWrngDis 0;
BA_ "NetworkRequest" SG_ 1227 Drv_AutoRlxWrngDis 0;
BA_ "NetworkRequestHoldingTime" SG_ 1227 Drv_AutoRlxWrngDis 5000;
BA_ "Version" SG_ 1227 Drv_AutoRlxWrngDis "21.06.10";
BA_ "Description" SG_ 1227 DrvIMS_MemorySetEnaSta "-(Old)C_MEMENB";
BA_ "GenSigSendType" SG_ 1227 DrvIMS_MemorySetEnaSta 4;
BA_ "UserSigValidity" SG_ 1227 DrvIMS_MemorySetEnaSta 0;
BA_REL_ "GenSigTimeoutTime" BU_SG_REL_ CGW_CCU SG_ 1227 DrvIMS_MemorySetEnaSta 0;
BA_ "NetworkRequest" SG_ 1227 DrvIMS_MemorySetEnaSta 0;
BA_ "NetworkRequestHoldingTime" SG_ 1227 DrvIMS_MemorySetEnaSta 5000;
BA_ "Version" SG_ 1227 DrvIMS_MemorySetEnaSta "17.11.00";
BA_ "GenSigSendType" SG_ 1227 DrvIMS_PlyBckP1Req 4;
BA_ "UserSigValidity" SG_ 1227 DrvIMS_PlyBckP1Req 0;
BA_REL_ "GenSigTimeoutTime" BU_SG_REL_ CGW_CCU SG_ 1227 DrvIMS_PlyBckP1Req 0;
BA_ "NetworkRequest" SG_ 1227 DrvIMS_PlyBckP1Req 0;
BA_ "NetworkRequestHoldingTime" SG_ 1227 DrvIMS_PlyBckP1Req 5000;
BA_ "Version" SG_ 1227 DrvIMS_PlyBckP1Req "17.11.00";
BA_ "GenMsgCycleTime" BO_ 1237 0;
BA_ "Description" SG_ 1237 SWRC_Crc2Val "The data area for CRC calculation is based on the data length (DLC) of the message DB.

The CRC shall be calculated over the entire data block (excluding the CRC bytes) including the user data, alive counter and Data ID 

 

- CRC Polynomial (0x1D) , Initial Value : 0x00, XOR value : 0xFF, Data ID Mode : Both, Data ID : Message ID + 0xF800 

- The initial value is for CRC calculation and the message should be sent with the calculated result value. 

The mathematical expression to 8 bit CRC polynomial is given here. G(x) = x8 + x4 + x3 + x2 + 1";
BA_ "GenSigSendType" SG_ 1237 SWRC_Crc2Val 4;
BA_ "GenSigStartValue" SG_ 1237 SWRC_Crc2Val 255;
BA_ "UserSigValidity" SG_ 1237 SWRC_Crc2Val 0;
BA_ "Version" SG_ 1237 SWRC_Crc2Val "19.11.02";
BA_ "Description" SG_ 1237 SWRC_AlvCnt2Val "For the first transmission request for a data element the counter shall be initialized with 0 and shall be incremented by 1

for every subsequent send request. When the counter reaches the maximum value(0xE), then it shall restart with 0 for the next send request";
BA_ "GenSigSendType" SG_ 1237 SWRC_AlvCnt2Val 4;
BA_ "UserSigValidity" SG_ 1237 SWRC_AlvCnt2Val 0;
BA_ "Version" SG_ 1237 SWRC_AlvCnt2Val "19.11.02";
BA_ "Description" SG_ 1237 Audio_VolEncoderSta "Audio Volume switch

MM-CAN Gateway needed";
BA_ "GenSigSendType" SG_ 1237 Audio_VolEncoderSta 4;
BA_ "UserSigValidity" SG_ 1237 Audio_VolEncoderSta 0;
BA_REL_ "GenSigTimeoutTime" BU_SG_REL_ CGW_CCU SG_ 1237 Audio_VolEncoderSta 0;
BA_ "NetworkRequest" SG_ 1237 Audio_VolEncoderSta 0;
BA_ "NetworkRequestHoldingTime" SG_ 1237 Audio_VolEncoderSta 5000;
BA_ "Version" SG_ 1237 Audio_VolEncoderSta "19.11.02";
BA_ "Description" SG_ 1237 Cluster_ScrlEncoderSta "Cluster Trip Switch";
BA_ "GenSigSendType" SG_ 1237 Cluster_ScrlEncoderSta 4;
BA_ "UserSigValidity" SG_ 1237 Cluster_ScrlEncoderSta 0;
BA_REL_ "GenSigTimeoutTime" BU_SG_REL_ CGW_CCU SG_ 1237 Cluster_ScrlEncoderSta 0;
BA_ "NetworkRequest" SG_ 1237 Cluster_ScrlEncoderSta 0;
BA_ "NetworkRequestHoldingTime" SG_ 1237 Cluster_ScrlEncoderSta 5000;
BA_ "Version" SG_ 1237 Cluster_ScrlEncoderSta "19.11.02";
BA_ "GenMsgSendType" BO_ 139 0;
BA_ "Description" SG_ 139 SWRC_Crc5Val "The data area for CRC calculation is based on the data length (DLC) of the message DB.

The CRC shall be calculated over the entire data block (excluding the CRC bytes) including the user data, alive counter and Data ID 

 

- CRC Polynomial (0x1D) , Initial Value : 0x00, XOR value : 0xFF, Data ID Mode : Both, Data ID : Message ID + 0xF800 

- The initial value is for CRC calculation and the message should be sent with the calculated result value. 

The mathematical expression to 8 bit CRC polynomial is given here. G(x) = x8 + x4 + x3 + x2 + 1";
BA_ "GenSigSendType" SG_ 139 SWRC_Crc5Val 4;
BA_ "GenSigStartValue" SG_ 139 SWRC_Crc5Val 255;
BA_ "UserSigValidity" SG_ 139 SWRC_Crc5Val 3;
BA_REL_ "GenSigTimeoutTime" BU_SG_REL_ CGW_CCU SG_ 139 SWRC_Crc5Val 1500;
BA_ "Version" SG_ 139 SWRC_Crc5Val "20.04.06";
BA_ "Description" SG_ 139 SWRC_AlvCnt5Val "For the first transmission request for a data element the counter shall be initialized with 0 and shall be incremented by 1

for every subsequent send request. When the counter reaches the maximum value(0xE), then it shall restart with 0 for the next send request";
BA_ "GenSigSendType" SG_ 139 SWRC_AlvCnt5Val 4;
BA_ "UserSigValidity" SG_ 139 SWRC_AlvCnt5Val 3;
BA_REL_ "GenSigTimeoutTime" BU_SG_REL_ CGW_CCU SG_ 139 SWRC_AlvCnt5Val 1500;
BA_ "Version" SG_ 139 SWRC_AlvCnt5Val "20.04.06";
BA_ "Description" SG_ 139 SWRC_DriveModCWSwSta "Drive Mode Switch Status Clockwise(right)";
BA_ "GenSigSendType" SG_ 139 SWRC_DriveModCWSwSta 4;
BA_ "UserSigValidity" SG_ 139 SWRC_DriveModCWSwSta 0;
BA_REL_ "GenSigTimeoutTime" BU_SG_REL_ CGW_CCU SG_ 139 SWRC_DriveModCWSwSta 1500;
BA_ "NetworkRequest" SG_ 139 SWRC_DriveModCWSwSta 0;
BA_ "NetworkRequestHoldingTime" SG_ 139 SWRC_DriveModCWSwSta 5000;
BA_ "Version" SG_ 139 SWRC_DriveModCWSwSta "20.01.01";
BA_ "Description" SG_ 139 SWRC_DriveModCCWSwSta "Drive Mode Switch Status CounterClockWise (Left)";
BA_ "GenSigSendType" SG_ 139 SWRC_DriveModCCWSwSta 4;
BA_ "UserSigValidity" SG_ 139 SWRC_DriveModCCWSwSta 0;
BA_REL_ "GenSigTimeoutTime" BU_SG_REL_ CGW_CCU SG_ 139 SWRC_DriveModCCWSwSta 1500;
BA_ "NetworkRequest" SG_ 139 SWRC_DriveModCCWSwSta 0;
BA_ "NetworkRequestHoldingTime" SG_ 139 SWRC_DriveModCCWSwSta 5000;
BA_ "Version" SG_ 139 SWRC_DriveModCCWSwSta "20.01.01";
BA_ "Description" SG_ 139 SWRC_BoostSwSta "Boost Switch Status";
BA_ "GenSigSendType" SG_ 139 SWRC_BoostSwSta 4;
BA_ "UserSigValidity" SG_ 139 SWRC_BoostSwSta 0;
BA_REL_ "GenSigTimeoutTime" BU_SG_REL_ CGW_CCU SG_ 139 SWRC_BoostSwSta 1500;
BA_ "NetworkRequest" SG_ 139 SWRC_BoostSwSta 0;
BA_ "NetworkRequestHoldingTime" SG_ 139 SWRC_BoostSwSta 5000;
BA_ "Version" SG_ 139 SWRC_BoostSwSta "19.12.08";
BA_ "Description" SG_ 139 SWRC_DriveModeSwSta "Drive Mode Switch Status (Push Type)";
BA_ "GenSigSendType" SG_ 139 SWRC_DriveModeSwSta 4;
BA_ "UserSigValidity" SG_ 139 SWRC_DriveModeSwSta 0;
BA_REL_ "GenSigTimeoutTime" BU_SG_REL_ CGW_CCU SG_ 139 SWRC_DriveModeSwSta 1500;
BA_ "Version" SG_ 139 SWRC_DriveModeSwSta "20.03.05";
BA_ "Description" SG_ 139 SWRC_TerrainModeSwSta "Terrain Mode Switch Status (Push Type)";
BA_ "GenSigSendType" SG_ 139 SWRC_TerrainModeSwSta 4;
BA_ "UserSigValidity" SG_ 139 SWRC_TerrainModeSwSta 0;
BA_REL_ "GenSigTimeoutTime" BU_SG_REL_ CGW_CCU SG_ 139 SWRC_TerrainModeSwSta 1500;
BA_ "Version" SG_ 139 SWRC_TerrainModeSwSta "21.09.02";
BA_ "Description" SG_ 139 SWRC_N1SwSta "N Vehicle SWRC N1 Switch signal";
BA_ "GenSigSendType" SG_ 139 SWRC_N1SwSta 4;
BA_ "UserSigValidity" SG_ 139 SWRC_N1SwSta 0;
BA_REL_ "GenSigTimeoutTime" BU_SG_REL_ CGW_CCU SG_ 139 SWRC_N1SwSta 1500;
BA_ "NetworkRequest" SG_ 139 SWRC_N1SwSta 0;
BA_ "NetworkRequestHoldingTime" SG_ 139 SWRC_N1SwSta 5000;
BA_ "Version" SG_ 139 SWRC_N1SwSta "21.11.06";
BA_ "Description" SG_ 139 SWRC_N2SwSta "N Vehicle SWRC N2 Switch signal";
BA_ "GenSigSendType" SG_ 139 SWRC_N2SwSta 4;
BA_ "UserSigValidity" SG_ 139 SWRC_N2SwSta 0;
BA_REL_ "GenSigTimeoutTime" BU_SG_REL_ CGW_CCU SG_ 139 SWRC_N2SwSta 1500;
BA_ "NetworkRequest" SG_ 139 SWRC_N2SwSta 0;
BA_ "NetworkRequestHoldingTime" SG_ 139 SWRC_N2SwSta 5000;
BA_ "Version" SG_ 139 SWRC_N2SwSta "21.11.06";
BA_ "GenMsgSendType" BO_ 2160080130 0;
BA_ "GenMsgCycleTime" BO_ 2160080130 50;
BA_ "GenMsgCycleTimeFast" BO_ 2160080130 0;
BA_ "GenMsgNrOfRepetition" BO_ 2160080130 0;
BA_ "VFrameFormat" BO_ 2160080130 1;
BA_ "Description" SG_ 2160080130 VCU_FatcPwrUseVal "Predicted HVAC Power Consumption";
BA_ "UserSigValidity" SG_ 2160080130 VCU_FatcPwrUseVal 7;
BA_ "RoutingFactor" SG_ 2160080130 VCU_FatcPwrUseVal 5;
BA_ "Version" SG_ 2160080130 VCU_FatcPwrUseVal "20.04.05";
BA_ "Description" SG_ 2160080130 VCU_McuAntiJerkInhFrntSta "Anti-jerk Inhibition";
BA_ "GenSigStartValue" SG_ 2160080130 VCU_McuAntiJerkInhFrntSta 1;
BA_ "UserSigValidity" SG_ 2160080130 VCU_McuAntiJerkInhFrntSta 7;
BA_ "RoutingFactor" SG_ 2160080130 VCU_McuAntiJerkInhFrntSta 5;
BA_ "Version" SG_ 2160080130 VCU_McuAntiJerkInhFrntSta "20.04.05";
BA_ "Description" SG_ 2160080130 VCU_McuAntiJerkInhRearSta "Anti-jerk Inhibition";
BA_ "GenSigStartValue" SG_ 2160080130 VCU_McuAntiJerkInhRearSta 1;
BA_ "UserSigValidity" SG_ 2160080130 VCU_McuAntiJerkInhRearSta 7;
BA_ "RoutingFactor" SG_ 2160080130 VCU_McuAntiJerkInhRearSta 5;
BA_ "Version" SG_ 2160080130 VCU_McuAntiJerkInhRearSta "20.04.05";
BA_ "Description" SG_ 2160080130 VCU_McuPwrLatchHoldReq "Mcu Power Latch Hold Request";
BA_ "UserSigValidity" SG_ 2160080130 VCU_McuPwrLatchHoldReq 7;
BA_ "RoutingFactor" SG_ 2160080130 VCU_McuPwrLatchHoldReq 5;
BA_ "Version" SG_ 2160080130 VCU_McuPwrLatchHoldReq "20.04.05";
BA_ "Description" SG_ 2160080130 VCU_ScuParkReq "Parking Command Request";
BA_ "UserSigValidity" SG_ 2160080130 VCU_ScuParkReq 7;
BA_ "RoutingFactor" SG_ 2160080130 VCU_ScuParkReq 5;
BA_ "Version" SG_ 2160080130 VCU_ScuParkReq "20.04.05";
BA_ "Description" SG_ 2160080130 VCU_MotTqCmdFrntVal "Torque Command for Front Motor";
BA_ "UserSigValidity" SG_ 2160080130 VCU_MotTqCmdFrntVal 7;
BA_ "RoutingFactor" SG_ 2160080130 VCU_MotTqCmdFrntVal 5;
BA_ "Version" SG_ 2160080130 VCU_MotTqCmdFrntVal "20.04.05";
BA_ "Description" SG_ 2160080130 VCU_ScuKeepWakeReq "SCU Keep Wake Request";
BA_ "UserSigValidity" SG_ 2160080130 VCU_ScuKeepWakeReq 7;
BA_ "RoutingFactor" SG_ 2160080130 VCU_ScuKeepWakeReq 5;
BA_ "Version" SG_ 2160080130 VCU_ScuKeepWakeReq "20.04.05";
BA_ "Description" SG_ 2160080130 VCU_MotTqCmdRearVal "Torque Command for Rear Motor";
BA_ "UserSigValidity" SG_ 2160080130 VCU_MotTqCmdRearVal 7;
BA_ "RoutingFactor" SG_ 2160080130 VCU_MotTqCmdRearVal 5;
BA_ "Version" SG_ 2160080130 VCU_MotTqCmdRearVal "20.04.05";
BA_ "Description" SG_ 2160080130 VCU_FmcuZeroTqOfsReq "Fmcu Zero Torque Offset Request";
BA_ "UserSigValidity" SG_ 2160080130 VCU_FmcuZeroTqOfsReq 7;
BA_ "RoutingFactor" SG_ 2160080130 VCU_FmcuZeroTqOfsReq 5;
BA_ "Version" SG_ 2160080130 VCU_FmcuZeroTqOfsReq "20.04.05";
BA_ "Description" SG_ 2160080130 VCU_WhlDemTqVal "Driver's Demand Torque Restricted by Battery Limit and HHT Temperature";
BA_ "UserSigValidity" SG_ 2160080130 VCU_WhlDemTqVal 7;
BA_ "RoutingFactor" SG_ 2160080130 VCU_WhlDemTqVal 5;
BA_ "Version" SG_ 2160080130 VCU_WhlDemTqVal "20.04.05";
VAL_ 678 Ast_AutoRlxWrngDis 0 "Off" 1 "Auto relax Enable" 2 "Mode-Fail (Vehicle Speed Warning)" 3 "Mode-Fail (Not P Warning)" 4 "Mode-Fail (2nd Seat Belted)" 5 "Mode-Fail (Not Initialized)" 6 "Mode-Fail (2nd Seat Position Warning)" 7 "Invaild" ;
VAL_ 678 APSM_IMSWngDis 0 "Default" 1 "Inhibit Ast IMS" 2 "Reserved" 3 "Invaild" ;
VAL_ 678 Ast_2ndLnkRtnStop 0 "Default" 1 "Return Stop" 2 "Reserved" 3 "Invalid" ;
VAL_ 140 ATS_DATC_FrPsModeSet 0 "Reserved" 1 "Vent" 2 "BL" 3 "Floor" 4 "Reserved" 5 "Reserved" 6 "Reserved" 7 "Reserved" 8 "Reserved" 9 "Reserved" 10 "Reserved" 11 "Reserved" 12 "Reserved" 13 "Reserved" 14 "Reserved" 15 "Invalid" ;
VAL_ 140 ATS_DATC_FrPsAutoSet 0 "reserved" 1 "AUTO ON" 2 "reserved" 3 "Invalid" ;
VAL_ 140 ATS_DATC_FrPsBlowerSet 0 "DATC Off" 1 "0 level (Do not use)" 2 "1 level" 3 "2 level" 4 "3 level" 5 "4 level" 6 "5 level" 7 "6 level" 8 "7 level" 9 "8 level" 15 "Invalid" ;
VAL_ 140 ATS_DATC_FrPsBlowerUpDn 0 "Reserved" 1 "Up" 2 "Down" 3 "Invalid" ;
VAL_ 140 ATS_DATC_FrDrMultiAutoBlower 0 "Reserved" 1 "Low" 2 "Medium" 3 "High" 4 "Reserved" 5 "Reserved" 6 "Reserved" 7 "Invalid" ;
VAL_ 140 ATS_DATC_FrPsMultiAutoBlower 0 "Reserved" 1 "Low" 2 "Medium" 3 "High" 4 "Reserved" 5 "Reserved" 6 "Reserved" 7 "Invalid" ;
VAL_ 140 ATS_DATC_RrDrMultiAutoBlower 0 "Reserved" 1 "Low" 2 "Medium" 3 "High" 4 "Reserved" 5 "Reserved" 6 "Reserved" 7 "Invalid" ;
VAL_ 140 ATS_DATC_FragranceStrhSet 0 "Default" 1 "Off" 2 "Low" 3 "Medium" 4 "High" 5 "Reserved" 6 "Reserved" 7 "Invalid" ;
VAL_ 140 ATS_DATC_FragranceKindSet 0 "Default" 1 "First" 2 "Second" 3 "Reserved" 4 "Reserved" 5 "Reserved" 6 "Reserved" 7 "Invalid" ;
VAL_ 140 ATS_DATC_FragranceBttnMnlSet 0 "Default" 1 "Off" 2 "On" 3 "Invalid" ;
VAL_ 140 ATS_DATC_TempUnitSet 0 "Off" 1 "¢ªC (Centigrade)" 2 "¢ªF (Fahrenheit)" 3 "Invalid" ;
VAL_ 607 ATS_RRStSldFwdBtn 0 "Default" 1 "Off" 2 "On" 3 "Reserved" ;
VAL_ 607 ATS_RRStSldBwdBtn 0 "Default" 1 "Off" 2 "On" 3 "Reserved" ;
VAL_ 607 ATS_RRStRclFwdBtn 0 "Default" 1 "Off" 2 "On" 3 "Reserved" ;
VAL_ 607 ATS_RRStRclBwdBtn 0 "Default" 1 "Off" 2 "On" 3 "Reserved" ;
VAL_ 607 ATS_RRStTltUpBtn 0 "Default" 1 "Off" 2 "On" 3 "Reserved" ;
VAL_ 607 ATS_RRStTltDnBtn 0 "Default" 1 "Off" 2 "On" 3 "Reserved" ;
VAL_ 607 ATS_RRStLegRestPopBtn 0 "Default" 1 "Off" 2 "On" 3 "Reserved" ;
VAL_ 607 ATS_RRStFRestPopBtn 0 "Default" 1 "Off" 2 "On" 3 "Reserved" ;
VAL_ 607 ATS_RRStAstPopBtn 0 "Default" 1 "Off" 2 "On" 3 "Reserved" ;
VAL_ 607 ATS_RRFauCondiBtn 0 "Default" 1 "Off" 2 "On" 3 "Reserved" ;
VAL_ 607 ATS_RRStHRestUpBtn 0 "Default" 1 "Off" 2 "On" 3 "Reserved" ;
VAL_ 607 ATS_RRStHRestDnBtn 0 "Default" 1 "Off" 2 "On" 3 "Reserved" ;
VAL_ 607 ATS_RRStHRestFwdBtn 0 "Default" 1 "Off" 2 "On" 3 "Reserved" ;
VAL_ 607 ATS_RRStHRestBwdBtn 0 "Default" 1 "Off" 2 "On" 3 "Reserved" ;
VAL_ 607 ATS_RRStShoulderADJFwdBtn 0 "Default" 1 "Off" 2 "On" 3 "Reserved" ;
VAL_ 607 ATS_RRStShoulderADJBwdBtn 0 "Default" 1 "Off" 2 "On" 3 "Reserved" ;
VAL_ 607 ATS_RRStLegRestUpBtn 0 "Default" 1 "Off" 2 "On" 3 "Reserved" ;
VAL_ 607 ATS_RRStLegRestDnBtn 0 "Default" 1 "Off" 2 "On" 3 "Reserved" ;
VAL_ 607 ATS_RRStLegRestExtUpBtn 0 "Default" 1 "Off" 2 "On" 3 "Reserved" ;
VAL_ 607 ATS_RRStLegRestExtDnBtn 0 "Default" 1 "Off" 2 "On" 3 "Reserved" ;
VAL_ 1216 PHEV_FuelDrReleaseSwSta 0 "Off" 1 "On" 2 "Not Used" 3 "Error Indicator" ;
VAL_ 1216 StrWhlWrmr_MKBDBpReq 0 "Beep Off" 1 "Beep On" 2 "Not Used" 3 "Error Indicator" ;
VAL_ 1216 BckGls_RrGlsHtdMKBDBpReq 0 "Beep Off" 1 "Beep On" 2 "Not Used" 3 "Error Indicator" ;
VAL_ 1216 Wndshld_FrtGlsHtdMKBDBpReq 0 "Beep Off" 1 "Beep On" 2 "Not Used" 3 "Error Indicator" ;
VAL_ 1216 BAlarm_AutoLockrReq 0 "Off" 1 "Lock" 2 "Not Used" 3 "Error Indicator" ;
VAL_ 1216 TiltTele_SmrtIMSDBNum 0 "None" 1 "0x1~0x97E:SmartIMS DB Number (1~2430)" 2430 "0x1~0x97E:SmartIMS DB Number (1~2430)" 4095 "Error indicator" ;
VAL_ 1216 Tilt_IMSMemoryCmd 0 "None" 1 "Memory 1" 2 "Memory 2" 3 "Memory 3" ;
VAL_ 1216 Tele_IMSMemoryCmd 0 "None" 1 "Memory 1" 2 "Memory 2" 3 "Memory 3" ;
VAL_ 2323816449 C_CtrlDrLockRlyCCS_Copy_2 0 "Off (default)" 1 "On (remote Lock Command)" 2 "Reserved" 3 "Invalid" ;
VAL_ 2323816449 C_TeleHeatingCmdIBOX_Copy_2 0 "Off (default)" 1 "On(Remote Heating On)" 2 "Reserved" 3 "Invalid" ;
VAL_ 2323816449 C_TeleStrgWhlHeatingCmdIBOX_Copy_2 0 "Off (default)" 1 "On(Remote Heating On)" 2 "Reserved" 3 "Invalid" ;
VAL_ 2323816449 C_TeleDefoggerHeatingCmdIBOX_Copy_2 0 "Off (default)" 1 "On(Remote Heating On)" 2 "Reserved" 3 "Invalid" ;
VAL_ 2323816449 C_TeleDrvSeatOpCmdIBOX_Copy_2 0 "Init" 1 "Unused" 2 "Seat Heat&Vent OFF" 3 "Seat_Vent_Low" 4 "Seat_Vent_Mid" 5 "Seat_Vent_High" 6 "Seat_Heat_Low" 7 "Seat_Heat_Mid" 8 "Seat_Heat_High" 9 "Unused" 10 "Unused" 11 "Unused" 12 "Unused" 13 "Unused" 14 "Unused" 15 "Invalid" ;
VAL_ 2323816449 C_CtrlDrUnlockRlyCCS_Copy_2 0 "0ff" 1 "On (Remote Unlock Command)" 2 "Reserved" 3 "Invalid" ;
VAL_ 2323816449 C_TeleAstSeatOpCmdIBOX_Copy_2 0 "Init" 1 "Unused" 2 "Seat Heat&Vent OFF" 3 "Seat_Vent_Low" 4 "Seat_Vent_Mid" 5 "Seat_Vent_High" 6 "Seat_Heat_Low" 7 "Seat_Heat_Mid" 8 "Seat_Heat_High" 9 "Unused" 10 "Unused" 11 "Unused" 12 "Unused" 13 "Unused" 14 "Unused" 15 "Invalid" ;
VAL_ 2323816449 C_TeleRRSeatOpCmdIBOX_Copy_2 0 "Init" 1 "Unused" 2 "Seat Heat&Vent OFF" 3 "Seat_Vent_Low" 4 "Seat_Vent_Mid" 5 "Seat_Vent_High" 6 "Seat_Heat_Low" 7 "Seat_Heat_Mid" 8 "Seat_Heat_High" 9 "Unused" 10 "Unused" 11 "Unused" 12 "Unused" 13 "Unused" 14 "Unused" 15 "Invalid" ;
VAL_ 2323816449 C_TeleRLSeatOpCmdIBOX_Copy_1 0 "Init" 1 "Unused" 2 "Seat Heat&Vent OFF" 3 "Seat_Vent_Low" 4 "Seat_Vent_Mid" 5 "Seat_Vent_High" 6 "Seat_Heat_Low" 7 "Seat_Heat_Mid" 8 "Seat_Heat_High" 9 "Unused" 10 "Unused" 11 "Unused" 12 "Unused" 13 "Unused" 14 "Unused" 15 "Invalid" ;
VAL_ 2323816449 C_BlindCmdAVN_Copy_2 0 "No Action" 1 "R_Blind Auto Open" 2 "R_Blind Auto Close" 3 "Stop" 4 "reserved" 5 "reserved" 6 "reserved" 7 "Invalid" ;
VAL_ 2323816449 C_GlassCmdAVN_Copy_2 0 "No Action" 1 "Glass Auto Open" 2 "Glass Auto Close" 3 "Glass Auto Tilt Up" 4 "Stop" 5 "reserved" 6 "reserved" 7 "Invalid" ;
VAL_ 2323816449 C_DrvWindowCmdAVN_Copy_2 0 "No action" 1 "Manual Down" 2 "Manual Up" 3 "25% Open" 4 "50% Open" 5 "Auto Down" 6 "Auto Up" 7 "15% Open" 8 "Unused" 9 "Unused" 10 "Unused" 11 "Unused" 12 "Unused" 13 "Unused" 14 "Unused" 15 "Invalid" ;
VAL_ 2323816449 C_HazardFromCCS_Copy_2 0 "Off" 1 "On (Remote Hazard On)" 2 "Reserved" 3 "Invalid" ;
VAL_ 2323816449 C_AstWindowCmdAVN_Copy_2 0 "No action" 1 "Manual Down" 2 "Manual Up" 3 "25% Open" 4 "50%Open" 5 "Auto Down" 6 "Auto Up" 7 "15% Open" 8 "Unused" 9 "Unused" 10 "Unused" 11 "Unused" 12 "Unused" 13 "Unused" 14 "Unused" 15 "Invalid" ;
VAL_ 2323816449 C_RRWindowCmdAVN_Copy_2 0 "No action" 1 "Manual Down" 2 "Manual Up" 3 "25% Open" 4 "50% Open" 5 "Auto Down" 6 "Auto Up" 7 "15% Open" 8 "Unused" 9 "Unused" 10 "Unused" 11 "Unused" 12 "Unused" 13 "Unused" 14 "Unused" 15 "Invalid" ;
VAL_ 2323816449 C_RLWindowCmdAVN_Copy_2 0 "No action" 1 "Manual Down" 2 "Manual Up" 3 "25% Open" 4 "50% Open" 5 "Auto Down" 6 "Auto UP" 7 "15% Open" 8 "Unused" 9 "Unused" 10 "Unused" 11 "Unused" 12 "Unused" 13 "Unused" 14 "Unused" 15 "Invalid" ;
VAL_ 2323816449 TailCtrlReq_Copy 0 "No Action(Default)" 1 "Tail Off" 2 "Tail On" 3 "Error Indicator" ;
VAL_ 2323816449 HazardCtrlReq_Copy 0 "No Action(Default)" 1 "Hazard Off" 2 "Hazard On" 3 "Error Indicator" ;
VAL_ 2323816449 HU_DATC_AirCleaningSet_Copy_1 0 "Air Cleaning System Off" 1 "Air Cleaning System On" 2 "Air Cleaning System Not Support" 3 "Invalid" ;
VAL_ 2323816449 C_PanicFromCCS_Copy_2 0 "Off" 1 "On (Remote Horn and Hazard On)" 2 "Reserved" 3 "Invalid" ;
VAL_ 2323816449 C_TeleFrontHeatingCmdIBOX_Copy_1 0 "Off (Default)" 1 "On (Remote Heating On)" 2 "Reserved" 3 "Invalid" ;
VAL_ 2323816449 RAC_AirCleaningCtrlReq_Copy_1 0 "Deactive air cleaning control" 1 "Active air cleaning control" 2 "Not used" 3 "invalid" ;
VAL_ 2323816449 C_PreCrankReq_Copy 0 "Default" 1 "Req On" 2 "Not Support" 3 "Invalid" ;
VAL_ 2323816450 HU_CDMOpenCmd_Copy_1 0 "Default" 1 "CDM Open" 2 "CDM Close" 3 "Invalid" ;
VAL_ 2323816450 HU_StrgWhlHeatingSet_CCS_Copy 0 "Default (off)" 1 "Step1 On" 2 "Step2 On" 3 "Reserved" 4 "Reserved" 5 "Reserved" 6 "Reserved" 7 "Invalid" ;
VAL_ 2323816450 C_EsyAcsProfileID_CCU 0 "Default" 1 "Gueset" 2 "Profile 1" 3 "Profile 2" 4 "Reserved" 5 "Reserved" 6 "Reserved" 7 "Reserved" 8 "Reserved" 9 "Reserved" 10 "Reserved" 11 "Reserved" 12 "Reserved" 13 "Reserved" 14 "Reserved" 15 "Invalid" ;
VAL_ 679 USM_CMSDayBrgtnsLvlRHSta 0 "-5 Level" 1 "-4 Level" 2 "-3 Level" 3 "-2 Level" 4 "-1 Level" 5 "0 Level" 6 "1 Level" 7 "2 Level" 8 "3 Level" 9 "4 Level" 10 "5 Level" 11 "Not Used" 12 "Not Used" 13 "Not Used" 14 "Error Indicator" 15 "Invalid" ;
VAL_ 679 USM_CMSNgtBrgtnsLvlRHSta 0 "-5 Level" 1 "-4 Level" 2 "-3 Level" 3 "-2 Level" 4 "-1 Level" 5 "0 Level" 6 "1 Level" 7 "2 Level" 8 "3 Level" 9 "4 Level" 10 "5 Level" 11 "Not Used" 12 "Not Used" 13 "Not Used" 14 "Error Indicator" 15 "Invalid" ;
VAL_ 679 IMS_CMSPlayBackSta_RH 0 "Stop" 1 "Play 1" 2 "Play 2" 3 "Smart IMS" 4 "Profile 1" 5 "Profile 2" 6 "Guest" 7 "Invalid" ;
VAL_ 679 MonitorStatus 0 "Default" 1 "Off" 2 "On" 3 "Invalid" ;
VAL_ 679 CMS_RH_FoldingSta 0 "Off" 1 "Folding" 2 "Not Used" 3 "Error Indicator" ;
VAL_ 679 CMS_RH_UnfoldingSta 0 "Off" 1 "Unfolding" 2 "Not Used" 3 "Error Indicator" ;
VAL_ 679 CMS_RHVerPosVal 251 "Reserved" 252 "Reserved" 253 "Reserved" 254 "Reserved" 255 "Error Indicator" ;
VAL_ 679 CMS_RHHorPosVal 251 "Reserved" 252 "Reserved" 253 "Reserved" 254 "Reserved" 255 "Error Indicator" ;
VAL_ 2382594049 DATC_DrvTempCDis 0 "Blank Display" 1 "'LO' Display" 254 "'HI' Display" 255 "Error Indicator" ;
VAL_ 2382594049 DATC_DrvTempFDis 0 "Blank Display" 1 "'LO' Display" 254 "'HI' Display" 255 "Error Indicator" ;
VAL_ 2382594049 DATC_PassTempCDis 0 "Blank Display" 1 "'LO' Display" 254 "'HI' Display" 255 "Error Indicator" ;
VAL_ 2382594049 DATC_PassTempFDis 0 "Blank Display" 1 "'LO' Display" 254 "'HI' Display" 255 "Error Indicator" ;
VAL_ 2382594049 DATC_TempDispSta 0 "OLD Set Temp Display range" 1 "NEW Set Temp Display Range" 2 "Not used" 3 "Error Indicator" ;
VAL_ 2382594049 DATC_PreEngOnReq2 0 "Default" 1 "Off" 2 "PreEngineOn Request" 3 "Error Indicator" ;
VAL_ 687 HOD_Dir_Status 0 "HANDS OFF" 1 "HAND TOUCH (SOFT)" 2 "HAND TOUCH (STRONG)" 3 "HAND GRIP (SOFT)" 4 "HAND GRIP (STRONG)" 5 "Reserved" 6 "Reserved" 7 "INVALID" ;
VAL_ 687 HOD_Option 0 "HOD-Option-OFF" 1 "HOD-Option-On" ;
VAL_ 2176872449 HDCT_OBDErrSta 0 "No error" 1 "OBD error" 2 "Not used" 3 "Error Indicator" ;
VAL_ 2176872449 HDCT_StcShftLrchCtrl 0 "No DR or RD lurch control" 1 "DR lurch control active" 2 "RD lurch control active" 3 "Error Indicator" ;
VAL_ 2176872449 HDCT_EngCltchLmphmMod 0 "Inactive" 1 "Active" 2 "Not used" 3 "Error Indicator" ;
VAL_ 2176872449 HDCT_CurrPrgrm 0 "SOS" 1 "ECO" 16 "ACC_NLD" 17 "ACC_LD1" 18 "ACC_LD2" 19 "ACC_LD3" 20 "Manual" 21 "Manual_LD" 22 "CLT_PRT" 23 "TCS_NLD" 24 "TCS_LD" 25 "NORMAL" 26 "ECO_DLD" 27 "DS_DLD" 28 "EVEN" 29 "ODD" 30 "CD (EV Mode)" 31 "Reserve" 2 "DS" 3 "ECO_LD1" 4 "ECO_LD2" 5 "ECO_LD3" 6 "ECO_LD1_HAT" 7 "ECO_LD2_HAT" 8 "ECO_LD3_HAT" 9 "DS_LD1" 10 "DS_LD2" 11 "DS_LD3" 12 "SOC_L" 13 "SOC_N" 14 "SOC_H" 15 "Highway" ;
VAL_ 2176872449 HDCT_FltSta 0 "No fault" 1 "TCU Diagnostic failure" 2 "" 3 "TCU Diagnostic faulure & Limphome activated" 4 "OPU/EOP Diagnostic failure" 5 "" 6 "" 7 "" ;
VAL_ 2176872449 HDCT_MCUAntJrkInhbt 0 "Anti-jerk not inhibit" 1 "Anti-jerk inhibit" 2 "Not used" 3 "Error Indicator" ;
VAL_ 2176872449 HDCT_TrgtGear 0 "If N or P are detected(No frictional conncetion)" 1 "1st speed" 2 "2nd speed" 3 "3rd speed" 4 "4th speed" 5 "5th speed" 6 "6th speed" 15 "Reverse" ;
VAL_ 2176872449 HDCT_CurrGear 0 "if N or P are detected (no frictional connection)" 1 "1st speed" 2 "2nd speed" 3 "3rd speed" 4 "4th speed" 5 "5th speed" 6 "6th speed" 15 "Reverse speed" ;
VAL_ 2176872449 HDCT_GearSelDis 0 "P" 1 "L" 2 "2" 3 "3" 4 "DS Mode (by TGS lever)" 5 "D" 6 "N" 7 "R" 8 "Sports/Manual Mode" 9 "Not display at Cluster" 10 "DS Mode (by Drive Mode button)" 11 "Reserved" 12 "Paddle shift" 13 "Reserved" 14 "Intermediate Position" 15 "Fault" ;
VAL_ 2176872450 HDCT_TCURdySta 0 "Not ready" 1 "Ready" 2 "Not used" 3 "Error Indicator" ;
VAL_ 2176872450 HDCT_NetrlCtrlSta 0 "Not complete" 1 "Complete" 2 "Not used" 3 "Error Indicator" ;
VAL_ 2176872450 HDCT_GearShftSta 0 "Inactive" 1 "Active" 2 "Not used" 3 "Error Indicator" ;
VAL_ 2176872450 HDCT_CtrlablSta 0 "Not Ready" 1 "Controllable" 2 "Not used" 3 "Error Indicator" ;
VAL_ 2176872450 HDCT_TqIncReq 0 "Passive" 1 "Torque increase controls" 2 "Not used" 3 "Error Indicator" ;
VAL_ 2176872450 HDCT_TrgtShftCls 0 "static" 1 "Pon UP" 2 "Poff UP" 3 "reserve" 4 "Pon DN" 5 "PoffDn(manual)" 6 "NSTP to 5;4;3;2" 7 "NSTP to 1" 8 "reserve" 9 "reserve" 10 "reserve" 11 "reserve" 12 "reserve" 13 "reserve" 14 "reserve" ;
VAL_ 2176872450 HDCT_EOLReq 0 "No request" 1 "EOL request" 2 "Not used" 3 "Error Indicator" ;
VAL_ 2176872450 HDCT_CltchSta 0 "Open" 1 "Slip" 2 "Locked" 3 "Locked&Micro Slip" ;
VAL_ 2176872450 HDCT_DblCltchSta 0 "CS_Open" 1 "CS_TakeUp" 2 "CS_Engage" 3 "CS_Shift" 4 "CS_Drive" 5 "CS_Disengage" 6 "CS_SpinRequest" 7 "CS_TestMode" 8 "CS_Initialize" 9 "CS_Fail" ;
VAL_ 2176872450 HDCT_AcnChrgInhbtReq 0 "-" 1 "Freeze AC clutch" 2 "Not used" 3 "Error Indicator" ;
VAL_ 2176872450 HDCT_KckDnSkpShftCnt 0 "Normal K/D(No Skipº¯¼Ó) or No shift" 1 "1st Skip K/D" 2 "2nd Skip K/D" 3 "Error Indicator" ;
VAL_ 2176872450 HDCT_ShftPhase 0 "No shift" 1 "A0 (Prepataion for shift)" 2 "A1 (Prepataion for shift)" 3 "A2 (Prepataion for shift)" 4 "A3 (Prepataion for shift)" 5 "B1 (Beginning of shift)" 6 "B2 (Beginning of shift)" 7 "B3 (Beginning of shift)" 8 "B4 (Beginning of shift)" 9 "C1 (Duration of actual shift)" 10 "C2 (Duration of actual shift)" 11 "C3 (Duration of actual shift)" 12 "D1 (Duration of actual shift)" 13 "E1 (Finishing shift)" 14 "E2 (Finishing shift)" 15 "E3 (Finishing shift)" 16 "END (Shift End)" ;
VAL_ 2176872451 HDCT_FuelCutReq 0 "No Fuel Cut request" 1 "Activation of Fuel Cut request" 2 "Not used" 3 "Error Indicator" ;
VAL_ 2176872451 HDCT_NCoastTrgtGear 0 "gN" 1 "g1" 2 "g2" 3 "g3" 4 "g4" 5 "g5" 6 "g6" 7 "None" 8 "None" 9 "None" 10 "None" 11 "None" 12 "None" 13 "None" 14 "None" 15 "gR" ;
VAL_ 2176872451 HDCT_CLUEngSpdFlag 0 "Off" 1 "On" 2 "Not used" 3 "Error Indicator" ;
VAL_ 2176872451 HDCT_CLUTrgtGear 0 "If N or P are detected(No frictional conncetion)" 1 "1st speed" 2 "2nd speed" 3 "3rd speed" 4 "4th speed" 5 "5th speed" 6 "6th speed" 7 "7th speed" 15 "Reverse" ;
VAL_ 2176872451 HDCT_GSITrgtGear 0 "Neutral (Initial Value)" 1 "1st speed" 2 "2nd speed" 3 "3rd speed" 4 "4th speed" 5 "5th speed" 6 "6th speed" 7 "Reserved" 8 "Reserved" 9 "Reserved" 10 "Reserved" 11 "Reserved" 12 "Reserved" 13 "Reserved" 14 "Reserved" 15 "Reserved" ;
VAL_ 2176872451 HDCT_NCoastDnReq 0 "Off" 1 "On" 2 "Not used" 3 "Error Indicator" ;
VAL_ 2176872451 HDCT_CLUEngSpd 8191 "Error Indicator" ;
VAL_ 676 C_DrAirSptNValueSet_EC 0 "Default" 1 "Off" 2 "On" 3 "Invalid" ;
VAL_ 676 C_DrCushSoftNValueSet_EC 0 "Default" 1 "Off" 2 "Low" 3 "Mid" 4 "High" 5 "Reserved" 6 "Reserved" 7 "Invalid" ;
VAL_ 676 C_AstAirSptNValueSet_EC 0 "Default" 1 "Off" 2 "On" 3 "Invalid" ;
VAL_ 676 C_DrBackSoftNValueSet_EC 0 "Default" 1 "Off" 2 "Low" 3 "Mid" 4 "High" 5 "Reserved" 6 "Reserved" 7 "Invalid" ;
VAL_ 676 C_AstAirSptModeNValueSet_EC 0 "Default" 1 "Mode 1" 2 "Mode 2" 3 "Mode 3" 4 "Mode 4" 5 "Mode 5" 6 "Reserved" 7 "Invalid" ;
VAL_ 676 C_DrAirSptModeNValueSet_EC 0 "Default" 1 "Mode 1" 2 "Mode 2" 3 "Mode 3" 4 "Mode 4" 5 "Mode 5" 6 "Reserved" 7 "Invalid" ;
VAL_ 676 C_RLAirSptNValueSet_EC 0 "Default" 1 "Off" 2 "On" 3 "Invalid" ;
VAL_ 676 C_AstAirSptStrNValueSet_EC 0 "Default" 1 "Weak" 2 "Normal" 3 "Strong" 4 "Reserved" 5 "Reserved" 6 "Reserved" 7 "Invalid" ;
VAL_ 676 C_AstAirSptTimeNValueSet_EC 0 "Default" 1 "Short" 2 "Normal" 3 "Long" 4 "Reserved" 5 "Reserved" 6 "Reserved" 7 "Invalid" ;
VAL_ 676 C_RRAirSptNValueSet_EC 0 "Default" 1 "Off" 2 "On" 3 "Invalid" ;
VAL_ 676 C_AstCushSoftNValueSet_EC 0 "Default" 1 "Off" 2 "Low" 3 "Mid" 4 "High" 5 "Reserved" 6 "Reserved" 7 "Invalid" ;
VAL_ 676 C_AstBackSoftNValueSet_EC 0 "Default" 1 "Off" 2 "Low" 3 "Mid" 4 "High" 5 "Reserved" 6 "Reserved" 7 "Invalid" ;
VAL_ 676 C_AstRlxNValueSet_EC 0 "Default" 1 "Off" 2 "Return" 3 "Relax" 4 "Reserved" 5 "Reserved" 6 "Reserved" 7 "Invalid" ;
VAL_ 676 C_RLAirSptModeNValueSet_EC 0 "Default" 1 "Mode 1" 2 "Mode 2" 3 "Mode 3" 4 "Mode 4" 5 "Mode 5" 6 "Reserved" 7 "Invalid" ;
VAL_ 676 C_DrAirSptStrNValueSet_EC 0 "Default" 1 "Weak" 2 "Normal" 3 "Strong" 4 "Reserved" 5 "Reserved" 6 "Reserved" 7 "Invalid" ;
VAL_ 676 C_RLAirSptStrNValueSet_EC 0 "Default" 1 "Weak" 2 "Normal" 3 "Strong" 4 "Reserved" 5 "Reserved" 6 "Reserved" 7 "Invalid" ;
VAL_ 676 C_RLAirSptTimeNValueSet_EC 0 "Default" 1 "Short" 2 "Normal" 3 "Long" 4 "Reserved" 5 "Reserved" 6 "Reserved" 7 "Invalid" ;
VAL_ 676 C_DrAirSptTimeNValueSet_EC 0 "Default" 1 "Short" 2 "Normal" 3 "Long" 4 "Reserved" 5 "Reserved" 6 "Reserved" 7 "Invalid" ;
VAL_ 677 C_RLBackSoftNValueSet_EC 0 "Default" 1 "Off" 2 "Low" 3 "Mid" 4 "High" 5 "Reserved" 6 "Reserved" 7 "Invalid" ;
VAL_ 677 C_RRAirSptStrNValueSet_EC 0 "Default" 1 "Weak" 2 "Normal" 3 "Strong" 4 "Reserved" 5 "Reserved" 6 "Reserved" 7 "Invalid" ;
VAL_ 677 C_RRAirSptTimeNValueSet_EC 0 "Default" 1 "Short" 2 "Normal" 3 "Long" 4 "Reserved" 5 "Reserved" 6 "Reserved" 7 "Invalid" ;
VAL_ 677 C_RRBackSoftNValueSet_EC 0 "Default" 1 "Off" 2 "Low" 3 "Mid" 4 "High" 5 "Reserved" 6 "Reserved" 7 "Invalid" ;
VAL_ 677 C_RROneTchNvalueSet_EC 0 "Default" 1 "Off" 2 "Return" 3 "Relax" 4 "AV" 5 "Read" 6 "Reserved" 7 "Invalid" ;
VAL_ 677 C_RLOneTchNValueSet_EC 0 "Default" 1 "Off" 2 "Return" 3 "Relax" 4 "Reserved" 5 "Reserved" 6 "Reserved" 7 "Invalid" ;
VAL_ 677 C_RRAirSptModeNValueSet_EC 0 "Default" 1 "Mode 1" 2 "Mode 2" 3 "Mode 3" 4 "Mode 4" 5 "Mode 5" 6 "Reserved" 7 "Invalid" ;
VAL_ 1219 BLTN_CAM_Rec_OWD_NvalueSet 0 "Default" 1 "Off" 2 "On" 3 "Invalid" ;
VAL_ 1219 BLTN_CAM_Time_Stm_NvalueSet 0 "Default" 1 "Off" 2 "On" 3 "Invalid" ;
VAL_ 1219 BLTN_CAM_Spd_Stm_NvalueSet 0 "Default" 1 "Off" 2 "On" 3 "Invalid" ;
VAL_ 1219 BLTN_CAM_Locatn_Stm_NvalueSet 0 "Default" 1 "Off" 2 "On" 3 "Invalid" ;
VAL_ 1219 BLTN_CAM_TrnSig_Stm_NvalueSet 0 "Default" 1 "Off" 2 "On" 3 "Invalid" ;
VAL_ 1219 BLTN_CAM_AclBrk_Stm_NvalueSet 0 "Default" 1 "Off" 2 "On" 3 "Invalid" ;
VAL_ 1219 BLTN_CAM_Rec_DEV_NvalueSet 0 "Default" 1 "Off" 2 "On" 3 "Invalid" ;
VAL_ 1219 BLTN_CAM_GearPos_Stm_NvalueSet 0 "Default" 1 "Off" 2 "On" 3 "Invalid" ;
VAL_ 1219 BLTN_CAM_EVSen_Stm_NvalueSet 0 "Default" 1 "Off" 2 "On" 3 "Invalid" ;
VAL_ 1219 BLTN_CAM_Strangl_Stm_NvalueSet 0 "Default" 1 "Off" 2 "On" 3 "Invalid" ;
VAL_ 1219 BLTN_CAM_PrkTime_NvalueSet 0 "Default" 1 "0x01~0xFB:1~ 251  hr" 251 "0x01~0xFB:1~ 251  hr" 252 "RESERVED" 253 "RESERVED" 254 "Not Supported" 255 "Invalid" ;
VAL_ 1219 BLTN_CAM_EV_BfrTime_NvalueSet 0 "10~20 sec" 1 "10~20 sec" 2 "10~20 sec" 3 "10~20 sec" 4 "10~20 sec" 5 "10~20 sec" 6 "10~20 sec" 7 "10~20 sec" 8 "10~20 sec" 9 "10~20 sec" 10 "10~20 sec" 11 "Reserved" 12 "Reserved" 13 "Reserved" 14 "Reserved" 15 "Reserved" 16 "Reserved" 17 "Reserved" 18 "Reserved" 19 "Reserved" 20 "Reserved" 21 "Reserved" 22 "Reserved" 23 "Reserved" 24 "Reserved" 25 "Reserved" 26 "Reserved" 27 "Reserved" 28 "Reserved" 29 "Reserved" 30 "Reserved" 31 "Invalid" ;
VAL_ 1219 BLTN_CAM_Rec_OWP_NvalueSet 0 "Default" 1 "Off" 2 "On" 3 "Invalid" ;
VAL_ 1219 BLTN_CAM_EV_AftTime_NvalueSet 0 "10~20 sec" 1 "10~20 sec" 2 "10~20 sec" 3 "10~20 sec" 4 "10~20 sec" 5 "10~20 sec" 6 "10~20 sec" 7 "10~20 sec" 8 "10~20 sec" 9 "10~20 sec" 10 "10~20 sec" 11 "Reserved" 12 "Reserved" 13 "Reserved" 14 "Reserved" 15 "Reserved" 16 "Reserved" 17 "Reserved" 18 "Reserved" 19 "Reserved" 20 "Reserved" 21 "Reserved" 22 "Reserved" 23 "Reserved" 24 "Reserved" 25 "Reserved" 26 "Reserved" 27 "Reserved" 28 "Reserved" 29 "Reserved" 30 "Reserved" 31 "Invalid" ;
VAL_ 1219 BLTN_CAM_TML_Int_NvalueSet 0 "Default" 1 "1~ 10 sec" 2 "1~ 10 sec" 3 "1~ 10 sec" 4 "1~ 10 sec" 5 "1~ 10 sec" 6 "1~ 10 sec" 7 "1~ 10 sec" 8 "1~ 10 sec" 9 "1~ 10 sec" 10 "1~ 10 sec" 11 "Reserved" 12 "Reserved" 13 "Reserved" 14 "Reserved" 15 "Invalid" ;
VAL_ 1219 BLTN_CAM_Sen_DEV_NvalueSet 0 "Default" 1 "Level 1" 2 "Level 2" 3 "Level 3" 4 "Level 4" 5 "Level 5" 6 "Reserved" 7 "Reserved" 8 "Reserved" 9 "Reserved" 10 "Reserved" 11 "Reserved" 12 "Reserved" 13 "Reserved" 14 "Reserved" 15 "Invalid" ;
VAL_ 1219 BLTN_CAM_Sen_PEV_NvalueSet 0 "Default" 1 "Level 1" 2 "Level 2" 3 "Level 3" 4 "Level 4" 5 "Level 5" 6 "Reserved" 7 "Reserved" 8 "Reserved" 9 "Reserved" 10 "Reserved" 11 "Reserved" 12 "Reserved" 13 "Reserved" 14 "Reserved" 15 "Invalid" ;
VAL_ 1219 BLTN_CAM_Rec_PEV_NvalueSet 0 "Default" 1 "Off" 2 "On" 3 "Invalid" ;
VAL_ 1219 BLTN_CAM_AudRec_NvalueSet 0 "Default" 1 "Off" 2 "On" 3 "Invalid" ;
VAL_ 1239 HU_MKBD_BtnLEDCtr 0 "Default" 1 "OFF" 2 "ON" 3 "Invalid" ;
VAL_ 1239 HU_ADMSettingState 0 "ADM On (Setting Vaule in HU)" 1 "ADM Off" 2 "Reserved" 3 "Reserved" 4 "Reserved" 5 "Reserved" 6 "Reserved" 7 "Invalid" ;
VAL_ 1239 HU_VehiclePwr 0 "Key out or Audio OFF" 1 "Not used" 2 "ACC or Audio ON" 3 "KBD Wake-up" 4 "Waiting for Good-Bye (Key out or Audio OFF)" 5 "Not used" 6 "Not used" 7 "Not used" 8 "Not used" 9 "Not used" 10 "Not used" 11 "Not used" 12 "Not used" 13 "Not used" 14 "Not used" 15 "Invalid" ;
VAL_ 1239 HU_BtnShowReq 0 "default" 1 "on" 2 "off" 3 "reserved" 4 "reserved" 5 "reserved" 6 "reserved" 7 "invalid" ;
VAL_ 1221 HU_ChgInCurrModSet 0 "Default" 1 "Maximum" 2 "Decreasing" 3 "Minimum" 4 "Reserved" 5 "Reserved" 6 "Reserved" 7 "Invalid" ;
VAL_ 1221 SWRC_Sensitivity_SET 0 "Medium(default)" 1 "Low" 2 "High" 3 "Invalid" ;
VAL_ 1221 HU_EV_WinterMode 0 "Winter mode Off" 1 "Winter mode On" 2 "Reserved" 3 "Invalid" ;
VAL_ 1221 HU_TgSoc_ScChg_Set 0 "0x0x0~0xC8:PHY = HEX * 0.5" 200 "0x0x0~0xC8:PHY = HEX * 0.5" 201 "Reserved" 202 "Reserved" 203 "Reserved" 204 "Reserved" 205 "Reserved" 206 "Reserved" 207 "Reserved" 208 "Reserved" 209 "Reserved" 210 "Reserved" 211 "Reserved" 212 "Reserved" 213 "Reserved" 214 "Reserved" 215 "Reserved" 216 "Reserved" 217 "Reserved" 218 "Reserved" 219 "Reserved" 220 "Reserved" 221 "Reserved" 222 "Reserved" 223 "Reserved" 224 "Reserved" 225 "Reserved" 226 "Reserved" 227 "Reserved" 228 "Reserved" 229 "Reserved" 230 "Reserved" 231 "Reserved" 232 "Reserved" 233 "Reserved" 234 "Reserved" 235 "Reserved" 236 "Reserved" 237 "Reserved" 238 "Reserved" 239 "Reserved" 240 "Reserved" 241 "Reserved" 242 "Reserved" 243 "Reserved" 244 "Reserved" 245 "Reserved" 246 "Reserved" 247 "Reserved" 248 "Reserved" 249 "Reserved" 250 "Reserved" 251 "Reserved" 252 "Reserved" 253 "Reserved" 254 "Reserved" 255 "Invalid" ;
VAL_ 1221 HU_TgSoc_QcChg_Set 0 "0x0x0~0xC8:PHY = HEX * 0.5" 200 "0x0x0~0xC8:PHY = HEX * 0.5" 201 "Reserved" 202 "Reserved" 203 "Reserved" 204 "Reserved" 205 "Reserved" 206 "Reserved" 207 "Reserved" 208 "Reserved" 209 "Reserved" 210 "Reserved" 211 "Reserved" 212 "Reserved" 213 "Reserved" 214 "Reserved" 215 "Reserved" 216 "Reserved" 217 "Reserved" 218 "Reserved" 219 "Reserved" 220 "Reserved" 221 "Reserved" 222 "Reserved" 223 "Reserved" 224 "Reserved" 225 "Reserved" 226 "Reserved" 227 "Reserved" 228 "Reserved" 229 "Reserved" 230 "Reserved" 231 "Reserved" 232 "Reserved" 233 "Reserved" 234 "Reserved" 235 "Reserved" 236 "Reserved" 237 "Reserved" 238 "Reserved" 239 "Reserved" 240 "Reserved" 241 "Reserved" 242 "Reserved" 243 "Reserved" 244 "Reserved" 245 "Reserved" 246 "Reserved" 247 "Reserved" 248 "Reserved" 249 "Reserved" 250 "Reserved" 251 "Reserved" 252 "Reserved" 253 "Reserved" 254 "Reserved" 255 "Invalid" ;
VAL_ 1221 HU_UserApproval 0 "Initial Value" 1 "Approve" 2 "Reject" 3 "Start Trigger" 4 "Unrecognized Reject" 5 "Reserved" 6 "Reserved" 7 "Reserved" 8 "Reserved" 9 "Reserved" 10 "Reserved" 11 "Reserved" 12 "Reserved" 13 "Reserved" 14 "Reserved" 15 "Invalid" ;
VAL_ 1221 HU_OtaInfomationReq 0 "Initial" 1 "Vehicle S/W Version" 2 "What's New (Text Only)" 3 "Download progress" 4 "Update progress" 5 "Reserved" 6 "Reserved" 7 "Reserved" 8 "Reserved" 9 "Reserved" 10 "Reserved" 11 "Reserved" 12 "Reserved" 13 "Reserved" 14 "Reserved" 15 "Invalid" ;
VAL_ 1218 C_AVN_PTGHeightNValueSet 0 "Default" 1 "Level 1" 2 "Level 2" 3 "Level 3" 4 "Level 4" 5 "Reserved" 6 "User Setting" 7 "Invalid" ;
VAL_ 1218 CF_AVN_SCCMLReset 0 "Default" 1 "Reset" 2 "Reserved" 3 "Invalid" ;
VAL_ 1218 C_TgltAwayCloseNValue 0 "Default" 1 "Off" 2 "On" 3 "Invalid" ;
VAL_ 1218 C_HAnBNValueSet 0 "Default" 1 "Arm Disarm Buzzer Off" 2 "Arm Disarm Buzzer On" 3 "Invalid" ;
VAL_ 1218 CF_AVN_RrSeatRemindNValueSet 0 "Default" 1 "Off  (Disable)" 2 "On (Enable)" 3 "Invalid" ;
VAL_ 1218 CF_AVN_DSWNValueSet 0 "Default" 1 "Off" 2 "On" 3 "Invalid" ;
VAL_ 1218 CF_AVN_RRPSU_RLNValueSet 0 "Default" 1 "Off (Disable)" 2 "On (Enable)" 3 "Reserved" 4 "Reserved" 5 "Reserved" 6 "Reserved" 7 "Invalid" ;
VAL_ 1218 CF_AVN_APSUNValueSet 0 "Default" 1 "Off (Disable)" 2 "50mm On (Enable)" 3 "75mm On (Enable)" 4 "Reserved" 5 "Reserved" 6 "Reserved" 7 "Invalid" ;
VAL_ 1218 CF_AVN_NCC_CameraNValueSet 0 "Default" 1 "Function Off" 2 "Manual Resume (Function On)" 3 "Automatic Resume (Function On)" 4 "Reserved" 5 "Reserved" 6 "Reserved" 7 "Invalid" ;
VAL_ 1218 CF_AVN_RRPSU_RRNValueSet 0 "Default" 1 "Off (Disable)" 2 "On (Enable)" 3 "Reserved" 4 "Reserved" 5 "Reserved" 6 "Reserved" 7 "Invalid" ;
VAL_ 1218 CF_AVN_HtBlcAstNValueSet 0 "Default" 1 "Normal" 2 "Back 1" 3 "Back 2" 4 "Back 3" 5 "Cush 1" 6 "Cush 2" 7 "Cush 3" 8 "Reserved" 9 "Reserved" 10 "Reserved" 11 "Reserved" 12 "Reserved" 13 "Reserved" 14 "Reserved" 15 "Invalid" ;
VAL_ 1218 CF_AVN_HtBlcDrvNValueSet 0 "Default" 1 "Normal" 2 "Back 1" 3 "Back 2" 4 "Back 3" 5 "Cush 1" 6 "Cush 2" 7 "Cush 3" 8 "Reserved" 9 "Reserved" 10 "Reserved" 11 "Reserved" 12 "Reserved" 13 "Reserved" 14 "Reserved" 15 "Invalid" ;
VAL_ 1218 CF_AVN_SCCModeNValueSet 0 "Not applied" 1 "Drive mode" 2 "SCC-ML" 3 "Invalid" ;
VAL_ 1218 CF_AVN_SCCMLChar1Set 0 "None" 1 "Level 1(Weak)" 2 "Level 2" 3 "Level 3" 4 "Level 4" 5 "Level 5(Strong)" 6 "Reserved" 7 "Invalid" ;
VAL_ 1218 CF_AVN_UIPNValueSet 0 "Default" 1 "Off (Disable)" 2 "On (Enable)" 3 "Invalid" ;
VAL_ 1218 CF_AVN_SCCMLChar2Set 0 "None" 1 "Level 1(Short)" 2 "Level 2" 3 "Level 3" 4 "Level 4" 5 "Reserved" 6 "Reserved" 7 "Invalid" ;
VAL_ 1218 CF_AVN_SCCMLChar3Set 0 "None" 1 "Level 1(Slow)" 2 "Level 2" 3 "Level 3" 4 "Level 4" 5 "Level 5(Fast)" 6 "Reserved" 7 "Invalid" ;
VAL_ 1218 CF_AVN_HDALCFuncNValueSet 0 "Default" 1 "Off" 2 "On" 3 "Invalid" ;
VAL_ 675 Usm_RpmMUDSet 0 "Default" 1 "Off" 2 "On(RPM Gauge Display)" 3 "Invalid" ;
VAL_ 675 CF_AVN_HtBlcRLNValueSet 0 "Default" 1 "Normal" 2 "Back 1" 3 "Back 2" 4 "Back 3" 5 "Cush 1" 6 "Cush 2" 7 "Cush 3" 8 "Reserved" 9 "Reserved" 10 "Reserved" 11 "Reserved" 12 "Reserved" 13 "Reserved" 14 "Reserved" 15 "Invalid" ;
VAL_ 675 CF_AVN_BRAKE_PedalfeelNValueSet2 0 "Default" 1 "Normal" 2 "Sport" 3 "Chauffeur" 4 "Reserved" 5 "Reserved" 6 "Reserved" 7 "Invalid" ;
VAL_ 675 CF_AVN_ISLA_AutoNModSet 0 "Default" 1 "Off" 2 "On" 3 "Invalid(Gray)" ;
VAL_ 675 CF_AVN_HtBlcRRNValueSet 0 "Default" 1 "Normal" 2 "Back 1" 3 "Back 2" 4 "Back 3" 5 "Cush 1" 6 "Cush 2" 7 "Cush 3" 8 "Reserved" 9 "Reserved" 10 "Reserved" 11 "Reserved" 12 "Reserved" 13 "Reserved" 14 "Reserved" 15 "Invalid" ;
VAL_ 675 LapTimer_AutoMeasure_Setting 0 "default" 1 "off" 2 "on (auto-measure)" 3 "invalid" ;
VAL_ 675 LapTimer_TimeGap_Setting 0 "default" 1 "compare with best lap" 2 "compare with last lap" 3 "invalid" ;
VAL_ 675 Usm_RpmSANDSet 0 "Default" 1 "Off" 2 "On(RPM Gauge Display)" 3 "Invalid" ;
VAL_ 675 CF_AVN_RemoteWDWNValueSet 0 "Default" 1 "Disable (Off)" 2 "Enable (On)" 3 "Invalid" ;
VAL_ 675 USM_TowWeight_Set 0 "Default" 1 "Off" 2 "Auto" 3 "Small" 4 "Medium" 5 "Maximum" 6 "Reserved" 7 "Reserved" 8 "Reserved" 9 "Reserved" 10 "Reserved" 11 "Reserved" 12 "Reserved" 13 "Reserved" 14 "Reserved" 15 "Invalid" ;
VAL_ 675 CF_AVN_PABArbgNValueSet 0 "Default" 1 "PAB Off" 2 "PAB On" 3 "Invalid" ;
VAL_ 675 CF_AVN_SportHUD2 0 "Default" 1 "Off(Normal)" 2 "Sport HUD" 3 "Invalid" ;
VAL_ 675 C_SLB_SmartCtrl_Set_Nvalue 0 "Init" 1 "Off" 2 "10min" 3 "20min" 4 "30min" 5 "40min" 6 "50min" 7 "60min" 8 "Unused" 9 "Unused" 10 "Unused" 11 "Unused" 12 "Unused" 13 "Unused" 14 "Unused" 15 "Invalid" ;
VAL_ 675 HU_CustomNewMenuSet 0 "Default" 1 "MY Drive Mode (Custom)" 2 "Smart (Custom)" 3 "Baby (Custom)" 4 "Retro(Custom)" 5 "Snow(CUSTOM) - Not Terrain" 6 "Comfort(Rear) - Custom" 7 "Reserved" 8 "Reserved" 9 "Reserved" 10 "Reserved" 11 "Reserved" 12 "Reserved" 13 "Reserved" 14 "Off(Custom)" 15 "Invalid" ;
VAL_ 675 USM_RpmComfortRearSet 0 "Default (Not configured)" 1 "Off" 2 "On (Display RPM guage)" 3 "Invalid" ;
VAL_ 675 Usm_RpmMyDriveModeSet 0 "Default" 1 "Off" 2 "On(RPM Gauge Display)" 3 "Invalid" ;
VAL_ 675 CF_AVN_PDWLmtNvalueSet 0 "Default" 1 "Off" 2 "On" 3 "Invalid" ;
VAL_ 675 CF_AVN_PCA_RrEquipNvalueSet 0 "Default" 1 "Off" 2 "On" 3 "Invalid(Gray)" ;
VAL_ 1076 IAU_ProfileIDRVal 0 "Default" 1 "Guest" 2 "Profile1" 3 "Profile2" 4 "Reserved" 5 "Reserved" 6 "Reserved" 7 "Reserved" 8 "Reserved" 9 "Reserved" 10 "Reserved" 11 "Reserved" 12 "Reserved" 13 "Reserved" 14 "Reserved" 15 "Invalid" ;
VAL_ 1076 IAU_DigitalKeyProcessingSta 0 "None" 1 "DeviceOnWPC" 2 "DeviceRegistering" 3 "PhoneRegistered" 4 "All Phone Key Deleted" 5 "NFCCard1Registered" 6 "Server Registering" 7 "NFCCard1Deleted" 8 "BLE Searching" 9 "Owner Phone key Deleted" 10 "Valet Off Searching" 11 "Server Registering Fail" 12 "Reserved" 13 "Reserved" 14 "Reserved" 15 "Invalid" ;
VAL_ 1076 IAU_DigitalKeyExit 0 "Normal" 1 "Check System" 2 "NFC Not Detected" 3 "Fob Not Detected" 4 "Canceled by User (Timeout)" 5 "Device not Available" 6 "ProcessFail" 7 "Check Card Save" 8 "Certificate Update" 9 "Valet Off Fail" 10 "CardNotAvailable" 11 "DigitalKeyDisabled" 12 "KeyNotSaved" 13 "Reserved" 14 "Reserved" 15 "Invalid" ;
VAL_ 1076 IAU_DigitalKeyEnblRVal 0 "Default" 1 "Disable" 2 "Enable" 3 "Invalid" ;
VAL_ 1076 IAU_OwnerPhnRegRVal 0 "Default" 1 "Disable" 2 "Enable" 3 "Invalid" ;
VAL_ 1076 IAU_NFCCard1RegRVal 0 "Default" 1 "Disable" 2 "Enable" 3 "Invalid" ;
VAL_ 1076 IAU_NFCCard2RegRVal 0 "Default" 1 "Disable" 2 "Enable" 3 "Invalid" ;
VAL_ 1076 IAU_DISPWrng 0 "None" 1 "Auth_Fail2 (DigitalKey)" 2 "ReAuth_Warning" 3 "IAU Error" 4 "DigitalKey Saved" 5 "Auth_Fail2 (FP)" 6 "Auth_Fail2 (DigitalKey or FP)" 7 "BiometricKey Saved" 8 "DigitalKey and BiometricKey Saved" 9 "Reserved" 10 "Reserved" 11 "Reserved" 12 "Reserved" 13 "Reserved" 14 "Reserved" 15 "Invalid" ;
VAL_ 1076 IAU_DigitalKey2Opt 0 "Default (Not applied)" 1 "Digital Key Light (NFC)" 2 "Digital Key Medium (NFC/BLE)" 3 "Digital Key Full (NFC/BLE/UWB)" 4 "Reserved" 5 "Reserved" 6 "Reserved" 7 "invalid" ;
VAL_ 1076 IAUwFRULearnState 0 "Default (Normal)" 1 "Learning" 2 "Neutralizing" 3 "Invalid" ;
VAL_ 1076 IAUwFPMLearnState 0 "Default(Normal)" 1 "Learning" 2 "Neutralizing" 3 "Invalid" ;
VAL_ 1227 DrvIMS_MemoryP1Req 0 "None" 1 "P1" 2 "Not Used" 3 "Error Indicator" ;
VAL_ 1227 DrvIMS_PlyBckP2Req 0 "None" 1 "P2" 2 "Not Used" 3 "Error Indicator" ;
VAL_ 1227 DrvIMS_PlyBckP3Req 0 "None" 1 "P3" 2 "Not Used" 3 "Error Indicator" ;
VAL_ 1227 DrvIMS_PlyBckStpReq 0 "Off" 1 "Stop" 2 "Not Used" 3 "Error Indicator" ;
VAL_ 1227 SmrtIMS_PlyBckReq 0 "None" 1 "0x1~0x97E:Smart IMS DB Number(1~2430)" 2430 "0x1~0x97E:Smart IMS DB Number(1~2430)" 2431 "0x97F~0xFFE:RESERVED" 4094 "0x97F~0xFFE:RESERVED" 4095 "Invalid" ;
VAL_ 1227 DrvIMS_MemoryP2Req 0 "None" 1 "P2" 2 "Not Used" 3 "Error Indicator" ;
VAL_ 1227 PSM_IMSReq 0 "None" 1 "Replay1" 2 "Replay2" 3 "Replay3" 4 "Memory1" 5 "Memory2" 6 "Memory3" 7 "Stop" ;
VAL_ 1227 SmrtIMS_ImgDBVal 0 "none" 1 "Smart IMS Image DB 1~30" 2 "Smart IMS Image DB 1~30" 3 "Smart IMS Image DB 1~30" 4 "Smart IMS Image DB 1~30" 5 "Smart IMS Image DB 1~30" 6 "Smart IMS Image DB 1~30" 7 "Smart IMS Image DB 1~30" 8 "Smart IMS Image DB 1~30" 9 "Smart IMS Image DB 1~30" 10 "Smart IMS Image DB 1~30" 11 "Smart IMS Image DB 1~30" 12 "Smart IMS Image DB 1~30" 13 "Smart IMS Image DB 1~30" 14 "Smart IMS Image DB 1~30" 15 "Smart IMS Image DB 1~30" 16 "Smart IMS Image DB 1~30" 17 "Smart IMS Image DB 1~30" 18 "Smart IMS Image DB 1~30" 19 "Smart IMS Image DB 1~30" 20 "Smart IMS Image DB 1~30" 21 "Smart IMS Image DB 1~30" 22 "Smart IMS Image DB 1~30" 23 "Smart IMS Image DB 1~30" 24 "Smart IMS Image DB 1~30" 25 "Smart IMS Image DB 1~30" 26 "Smart IMS Image DB 1~30" 27 "Smart IMS Image DB 1~30" 28 "Smart IMS Image DB 1~30" 29 "Smart IMS Image DB 1~30" 30 "Smart IMS Image DB 1~30" 31 "Invalid" ;
VAL_ 1227 SmrtIMS_PlyBckStpReq 0 "OFF" 1 "On" 2 "Not Used" 3 "Error Indicator" ;
VAL_ 1227 DrvIMS_MemoryP3Req 0 "None" 1 "P3" 2 "Not Used" 3 "Error Indicator" ;
VAL_ 1227 SmrtIMS_EnterSwSta 0 "off" 1 "on" 2 "reserved" 3 "invalid" ;
VAL_ 1227 DrvIMS_BzrReq 0 "Off" 1 "On" 2 "Not Used" 3 "Error Indicator" ;
VAL_ 1227 DrvIMS_ErrConWmgDis 0 "Off" 1 "On" 2 "Not Used" 3 "Error Indicator" ;
VAL_ 1227 PSM_DrvRlxReturn_Req 0 "Default" 1 "One touch relax" 2 "One touch return" 3 "Stop" 4 "Reserved" 5 "Reserved" 6 "Reserved" 7 "invalid" ;
VAL_ 1227 Drv_AutoRlxWrngDis 0 "Off" 1 "Auto Relax Enable" 2 "Mode-Fail (Vehicle Speed Warning)" 3 "Mode-Fail (Not P Warning)" 4 "Mode-Fail (2nd Seat Belted)" 5 "Mode-Fail (Not Initialized)" 6 "Mode-Fail (2nd Seat Position Warning)" 7 "Invalid" ;
VAL_ 1227 DrvIMS_MemorySetEnaSta 0 "Disable" 1 "Enable" 2 "Not Used" 3 "Error Indicator" ;
VAL_ 1227 DrvIMS_PlyBckP1Req 0 "None" 1 "P1" 2 "Not Used" 3 "Error Indicator" ;
VAL_ 1237 Audio_VolEncoderSta 0 "Reserved" 1 "0x01~0x7F:Clockwise(Up)" 127 "0x01~0x7F:Clockwise(Up)" 128 "0x80~0xFE:Counterclockwise (Down)" 254 "0x80~0xFE:Counterclockwise (Down)" 255 "Invalid" ;
VAL_ 1237 Cluster_ScrlEncoderSta 0 "Reserved" 1 "0x01~0x7F:Clockwise(Up)" 127 "0x01~0x7F:Clockwise(Up)" 128 "0x80~0xFE:Counterclockwise (Down)" 254 "0x80~0xFE:Counterclockwise (Down)" 255 "Invalid" ;
VAL_ 139 SWRC_DriveModCWSwSta 0 "Off" 1 "On" 2 "Reserved" 3 "Invalid" ;
VAL_ 139 SWRC_DriveModCCWSwSta 0 "Off" 1 "On" 2 "Reserved" 3 "Invalid" ;
VAL_ 139 SWRC_BoostSwSta 0 "Off" 1 "Key On" 2 "Reserved" 3 "Invalid" ;
VAL_ 139 SWRC_DriveModeSwSta 0 "Off" 1 "On" 2 "Reserved" 3 "Invalid" ;
VAL_ 139 SWRC_TerrainModeSwSta 0 "Off" 1 "On" 2 "Reserved" 3 "Invalid" ;
VAL_ 139 SWRC_N1SwSta 0 "Off" 1 "Key On" 2 "RESERVED" 3 "Invalid" ;
VAL_ 139 SWRC_N2SwSta 0 "Off" 1 "Key On" 2 "RESERVED" 3 "Invalid" ;
VAL_ 2160080130 VCU_McuAntiJerkInhFrntSta 0 "Anti-jerk Not Inhibit" 1 "Anti-jerk Inhibit" 2 "Not used" 3 "Error Indicator" ;
VAL_ 2160080130 VCU_McuAntiJerkInhRearSta 0 "Anti-jerk Not Inhibit" 1 "Anti-jerk Inhibit" 2 "Not used" 3 "Error Indicator" ;
VAL_ 2160080130 VCU_McuPwrLatchHoldReq 0 "No Request" 1 "Power Latch Hold Request" 2 "Not used" 3 "Error Indicator" ;
VAL_ 2160080130 VCU_ScuParkReq 0 "Wait Command" 1 "Not used" 2 "Parking Command" 3 "Not Parking Command" ;
VAL_ 2160080130 VCU_ScuKeepWakeReq 0 "None" 1 "Keep Wake Request" 2 "Not used" 3 "Error Indicator" ;
VAL_ 2160080130 VCU_FmcuZeroTqOfsReq 0 "No Request" 1 "Request" 2 "Not used" 3 "Error Indicator" ;
